[part 13 of 15: packages /TPConfig to /ComponentTypes]
AUTOSAR XML (schema 4-3-0)
package /TPConfig
  can tp config CanTPConfig_HCP3_CANFD01: communication-cluster=HCP3_CANFD01, can-tp-ecu=HCP3_IONode
    68 x can tp address:
      TA_0x1C403B1B: tp-address=473971483
      TA_0x1C423B1B: tp-address=474102555
      TA_0x1CD02268: tp-address=483402344
      TA_0x1CD22268: tp-address=483533416
      TA_0x1CD0226B: tp-address=483402347
      TA_0x1CD2226B: tp-address=483533419
      TA_0x1CD0226E: tp-address=483402350
      TA_0x1CD2226E: tp-address=483533422
      TA_0x1C446822: tp-address=474245154
      TA_0x1C466822: tp-address=474376226
      TA_0x1C446723: tp-address=474244899
      TA_0x1C466723: tp-address=474375971
      TA_0x1C446B22: tp-address=474245922
      TA_0x1C466B22: tp-address=474376994
      TA_0x1C446A23: tp-address=474245667
      TA_0x1C466A23: tp-address=474376739
      TA_0x1D001B73: tp-address=486546291
      TA_0x1D021B73: tp-address=486677363
      TA_0x1D00731B: tp-address=486568731
      TA_0x1D02731B: tp-address=486699803
      TA_0x1C446E22: tp-address=474246690
      TA_0x1C466E22: tp-address=474377762
      TA_0x1C446C24: tp-address=474246180
      TA_0x1C466C24: tp-address=474377252
      TA_0x1C446D23: tp-address=474246435
      TA_0x1C466D23: tp-address=474377507
      TA_0x1CD0246C: tp-address=483402860
      TA_0x1CD2246C: tp-address=483533932
      TA_0x1CD02367: tp-address=483402599
      TA_0x1CD22367: tp-address=483533671
      TA_0x1CD0236A: tp-address=483402602
      TA_0x1CD2236A: tp-address=483533674
      TA_0x1CD0236D: tp-address=483402605
      TA_0x1CD2236D: tp-address=483533677
      TA_0x1CC01B3B: tp-address=482351931
      TA_0x1CC21B3B: tp-address=482483003
      TA_0x1C401693: tp-address=473962131
      TA_0x1C421693: tp-address=474093203
      TA_0x1C400693: tp-address=473958035
      TA_0x1C420693: tp-address=474089107
      TA_0x1C440024: tp-address=474218532
      TA_0x1C460024: tp-address=474349604
      TA_0x1C440022: tp-address=474218530
      TA_0x1C460022: tp-address=474349602
      TA_0x1C42001B: tp-address=474087451
      TA_0x1C460023: tp-address=474349603
      TA_0x1C4200A5: tp-address=474087589
      TA_0x1C4200A6: tp-address=474087590
      TA_0x1C410000: tp-address=474021888
      TA_0x1C40001B: tp-address=473956379
      TA_0x1C440023: tp-address=474218531
      TA_0x1C4000A5: tp-address=473956517
      TA_0x1C4000A6: tp-address=473956518
      TA_0x1C42021B: tp-address=474087963
      TA_0x1C460224: tp-address=474350116
      TA_0x1C460222: tp-address=474350114
      TA_0x1C460223: tp-address=474350115
      TA_0x1C4202A5: tp-address=474088101
      TA_0x1C4202A6: tp-address=474088102
      TA_0x1C410200: tp-address=474022400
      TA_0x1C440224: tp-address=474219044
      TA_0x1C440222: tp-address=474219042
      TA_0x1C40021B: tp-address=473956891
      TA_0x1C407093: tp-address=473985171
      TA_0x1C427093: tp-address=474116243
      TA_0x1C440223: tp-address=474219043
      TA_0x1C4002A5: tp-address=473957029
      TA_0x1C4002A6: tp-address=473957030
    35 x can tp channel, all with channel-mode=HALF-DUPLEX-MODE:
      TPC_HCP3_CANFD01_XIX_TPCHType_CANFD_ARC_Master_XIX_0x1C403B1B_XIX_0x1C423B1B_XIX_Physical: channel-id=781318823
      TPC_HCP3_CANFD01_XIX_TPCHType_CANFD_HID_Slave_XIX_0x1CD02268_XIX_0x1CD22268_XIX_Physical: channel-id=1886458101
      TPC_HCP3_CANFD01_XIX_TPCHType_CANFD_HID_Slave_XIX_0x1CD0226B_XIX_0x1CD2226B_XIX_Physical: channel-id=533078475
      TPC_HCP3_CANFD01_XIX_TPCHType_CANFD_HID_Slave_XIX_0x1CD0226E_XIX_0x1CD2226E_XIX_Physical: channel-id=29550741
      TPC_HCP3_CANFD01_XIX_TPCHType_CANFD_HID_Master_XIX_0x1C446822_XIX_0x1C466822_XIX_Physical: channel-id=267511542
      TPC_HCP3_CANFD01_XIX_TPCHType_CANFD_HID_Master_XIX_0x1C446723_XIX_0x1C466723_XIX_Physical: channel-id=79765770
      TPC_HCP3_CANFD01_XIX_TPCHType_CANFD_HID_Master_XIX_0x1C446B22_XIX_0x1C466B22_XIX_Physical: channel-id=1864853942
      TPC_HCP3_CANFD01_XIX_TPCHType_CANFD_HID_Master_XIX_0x1C446A23_XIX_0x1C466A23_XIX_Physical: channel-id=1517576630
      TPC_HCP3_CANFD01_XIX_TPCHType_CANFD_HID_Slave_XIX_0x1D001B73_XIX_0x1D021B73_XIX_Physical: channel-id=1735088907
      TPC_HCP3_CANFD01_XIX_TPCHType_CANFD_HID_Master_XIX_0x1D00731B_XIX_0x1D02731B_XIX_Physical: channel-id=1786858122
      TPC_HCP3_CANFD01_XIX_TPCHType_CANFD_HID_Master_XIX_0x1C446E22_XIX_0x1C466E22_XIX_Physical: channel-id=1950910634
      TPC_HCP3_CANFD01_XIX_TPCHType_CANFD_HID_Master_XIX_0x1C446C24_XIX_0x1C466C24_XIX_Physical: channel-id=1649502038
      TPC_HCP3_CANFD01_XIX_TPCHType_CANFD_HID_Master_XIX_0x1C446D23_XIX_0x1C466D23_XIX_Physical: channel-id=1996779350
      TPC_HCP3_CANFD01_XIX_TPCHType_CANFD_HID_Slave_XIX_0x1CD0246C_XIX_0x1CD2246C_XIX_Physical: channel-id=665003883
      TPC_HCP3_CANFD01_XIX_TPCHType_CANFD_HID_Slave_XIX_0x1CD02367_XIX_0x1CD22367_XIX_Physical: channel-id=1539180789
      TPC_HCP3_CANFD01_XIX_TPCHType_CANFD_HID_Slave_XIX_0x1CD0236A_XIX_0x1CD2236A_XIX_Physical: channel-id=880355787
      TPC_HCP3_CANFD01_XIX_TPCHType_CANFD_HID_Slave_XIX_0x1CD0236D_XIX_0x1CD2236D_XIX_Physical: channel-id=317726571
      TPC_HCP3_CANFD01_XIX_TPCHType_CANFD_ARC_Slave_XIX_0x1CC01B3B_XIX_0x1CC21B3B_XIX_Physical: channel-id=2114590746
      TPC_HCP3_CANFD01_XIX_TPCHType_CANFD_Flash_DIA_XIX_0x1C401693_XIX_0x1C421693_XIX_Physical: channel-id=4065219
      TPC_HCP3_CANFD01_XIX_TPCHType_CANFD_Diag_XIX_0x1C400693_XIX_0x1C420693_XIX_Physical: channel-id=307815037
      TPC_HCP3_CANFD01_XIX_TPCHType_CANFD_ISO_Diagnose_XIX_0x1C440024_XIX_0x1C460024_XIX_Physical: channel-id=237980624
      TPC_HCP3_CANFD01_XIX_TPCHType_CANFD_ISO_Diagnose_XIX_0x1C440022_XIX_0x1C460022_XIX_Physical: channel-id=613066768
      TPC_HCP3_CANFD01_XIX_TPCHType_CANFD_ISO_Diagnose_XIX_0x1C410000_XIX_Functional: channel-id=531585000
      TPC_HCP3_CANFD01_XIX_TPCHType_CANFD_ISO_Diagnose_XIX_0x1C40001B_XIX_0x1C42001B_XIX_Physical: channel-id=706849680
      TPC_HCP3_CANFD01_XIX_TPCHType_CANFD_ISO_Diagnose_XIX_0x1C440023_XIX_0x1C460023_XIX_Physical: channel-id=425523696
      TPC_HCP3_CANFD01_XIX_TPCHType_CANFD_ISO_Diagnose_XIX_0x1C4000A5_XIX_0x1C4200A5_XIX_Physical: channel-id=1095840240
      TPC_HCP3_CANFD01_XIX_TPCHType_CANFD_ISO_Diagnose_XIX_0x1C4000A6_XIX_0x1C4200A6_XIX_Physical: channel-id=1283383312
      TPC_HCP3_CANFD01_XIX_TPCHType_CANFD_OBDC_Diagnose_XIX_0x1C410200_XIX_Functional: channel-id=89177809
      TPC_HCP3_CANFD01_XIX_TPCHType_CANFD_OBDC_Diagnose_XIX_0x1C440224_XIX_0x1C460224_XIX_Physical: channel-id=1373287515
      TPC_HCP3_CANFD01_XIX_TPCHType_CANFD_OBDC_Diagnose_XIX_0x1C440222_XIX_0x1C460222_XIX_Physical: channel-id=1748373659
      TPC_HCP3_CANFD01_XIX_TPCHType_CANFD_OBDC_Diagnose_XIX_0x1C40021B_XIX_0x1C42021B_XIX_Physical: channel-id=428457211
      TPC_HCP3_CANFD01_XIX_TPCHType_CANFD_OBDC_SSN_Diagnose_XIX_0x1C407093_XIX_0x1C427093_XIX_Physical: channel-id=26808244
      TPC_HCP3_CANFD01_XIX_TPCHType_CANFD_OBDC_Diagnose_XIX_0x1C440223_XIX_0x1C460223_XIX_Physical: channel-id=1560830587
      TPC_HCP3_CANFD01_XIX_TPCHType_CANFD_OBDC_Diagnose_XIX_0x1C4002A5_XIX_0x1C4202A5_XIX_Physical: channel-id=39466651
      TPC_HCP3_CANFD01_XIX_TPCHType_CANFD_OBDC_Diagnose_XIX_0x1C4002A6_XIX_0x1C4202A6_XIX_Physical: channel-id=148076421
    can-tp-connection addressing-format=STANDARD, can-tp-channel=TPC_HCP3_CANFD01_XIX_TPCHType_CANFD_ARC_Master_XIX_0x1C403B1B_XIX_0x1C423B1B_XIX_Physical, cancellation=true, data-pdu=ARC_HUD_Req_FD_XIX_HCP3_CANFD01, flow-control-pdu=ARC_HUD_Resp_FD_XIX_HCP3_CANFD01, max-block-size=15, padding-activation=true, receiver=TPN_HUD_XIX_HCP3_CANFD01_XIX_474102555, ta-type=PHYSICAL, timeout-br=0.1, timeout-bs=1.0, timeout-cr=1.0, timeout-cs=0.2, tp-sdu=CDD_HCP3_CANFD01_XIX_TPCHType_CANFD_ARC_Master_XIX_0x1C403B1B_XIX_0x1C423B1B_XIX_Physical, transmitter=TPN_Info_El_XIX_HCP3_CANFD01_XIX_473971483:
      ident TPCN_HCP3_CANFD01_XIX_TPCHType_CANFD_ARC_Master_XIX_0x1C403B1B_Info_El_XIX_0x1C423B1B_HUD_XIX_Physical
    can-tp-connection addressing-format=STANDARD, can-tp-channel=TPC_HCP3_CANFD01_XIX_TPCHType_CANFD_ARC_Master_XIX_0x1C403B1B_XIX_0x1C423B1B_XIX_Physical, cancellation=true, data-pdu=ARC_HUD_Resp_FD_XIX_HCP3_CANFD01, flow-control-pdu=ARC_HUD_Req_FD_XIX_HCP3_CANFD01, max-block-size=15, padding-activation=true, receiver=TPN_Info_El_XIX_HCP3_CANFD01_XIX_473971483, ta-type=PHYSICAL, timeout-br=0.1, timeout-bs=1.0, timeout-cr=1.0, timeout-cs=0.2, tp-sdu=CDD_HCP3_CANFD01_XIX_TPCHType_CANFD_ARC_Master_XIX_0x1C423B1B_XIX_0x1C403B1B_XIX_Physical, transmitter=TPN_HUD_XIX_HCP3_CANFD01_XIX_474102555:
      ident TPCN_HCP3_CANFD01_XIX_TPCHType_CANFD_ARC_Master_XIX_0x1C423B1B_HUD_XIX_0x1C403B1B_Info_El_XIX_Physical
    can-tp-connection addressing-format=STANDARD, can-tp-channel=TPC_HCP3_CANFD01_XIX_TPCHType_CANFD_ARC_Slave_XIX_0x1CC01B3B_XIX_0x1CC21B3B_XIX_Physical, cancellation=true, data-pdu=HUD_ARC_Req_FD_XIX_HCP3_CANFD01, flow-control-pdu=HUD_ARC_Resp_FD_XIX_HCP3_CANFD01, max-block-size=15, padding-activation=true, receiver=TPN_Info_El_XIX_HCP3_CANFD01_XIX_482483003, ta-type=PHYSICAL, timeout-br=0.1, timeout-bs=1.0, timeout-cr=1.0, timeout-cs=0.2, tp-sdu=CDD_HCP3_CANFD01_XIX_TPCHType_CANFD_ARC_Slave_XIX_0x1CC01B3B_XIX_0x1CC21B3B_XIX_Physical, transmitter=TPN_HUD_XIX_HCP3_CANFD01_XIX_482351931:
      ident TPCN_HCP3_CANFD01_XIX_TPCHType_CANFD_ARC_Slave_XIX_0x1CC01B3B_HUD_XIX_0x1CC21B3B_Info_El_XIX_Physical
    can-tp-connection addressing-format=STANDARD, can-tp-channel=TPC_HCP3_CANFD01_XIX_TPCHType_CANFD_ARC_Slave_XIX_0x1CC01B3B_XIX_0x1CC21B3B_XIX_Physical, cancellation=true, data-pdu=HUD_ARC_Resp_FD_XIX_HCP3_CANFD01, flow-control-pdu=HUD_ARC_Req_FD_XIX_HCP3_CANFD01, max-block-size=15, padding-activation=true, receiver=TPN_HUD_XIX_HCP3_CANFD01_XIX_482351931, ta-type=PHYSICAL, timeout-br=0.1, timeout-bs=1.0, timeout-cr=1.0, timeout-cs=0.2, tp-sdu=CDD_HCP3_CANFD01_XIX_TPCHType_CANFD_ARC_Slave_XIX_0x1CC21B3B_XIX_0x1CC01B3B_XIX_Physical, transmitter=TPN_Info_El_XIX_HCP3_CANFD01_XIX_482483003:
      ident TPCN_HCP3_CANFD01_XIX_TPCHType_CANFD_ARC_Slave_XIX_0x1CC21B3B_Info_El_XIX_0x1CC01B3B_HUD_XIX_Physical
    can-tp-connection addressing-format=STANDARD, can-tp-channel=TPC_HCP3_CANFD01_XIX_TPCHType_CANFD_Diag_XIX_0x1C400693_XIX_0x1C420693_XIX_Physical, cancellation=true, data-pdu=Diag_LSR_1_Req_FD_XIX_HCP3_CANFD01, flow-control-pdu=Diag_LSR_1_Resp_FD_XIX_HCP3_CANFD01, max-block-size=15, padding-activation=true, receiver=TPN_LSR_1_XIX_HCP3_CANFD01_XIX_474089107, ta-type=PHYSICAL, timeout-br=0.1, timeout-bs=1.0, timeout-cr=1.0, timeout-cs=0.2, tp-sdu=DCM_HCP3_CANFD01_XIX_TPCHType_CANFD_Diag_XIX_0x1C400693_XIX_0x1C420693_XIX_Physical, transmitter=TPN_Info_El_XIX_HCP3_CANFD01_XIX_473958035:
      ident TPCN_HCP3_CANFD01_XIX_TPCHType_CANFD_Diag_XIX_0x1C400693_Info_El_XIX_0x1C420693_LSR_1_XIX_Physical
    can-tp-connection addressing-format=STANDARD, can-tp-channel=TPC_HCP3_CANFD01_XIX_TPCHType_CANFD_Diag_XIX_0x1C400693_XIX_0x1C420693_XIX_Physical, cancellation=true, data-pdu=Diag_LSR_1_Resp_FD_XIX_HCP3_CANFD01, flow-control-pdu=Diag_LSR_1_Req_FD_XIX_HCP3_CANFD01, max-block-size=15, padding-activation=true, receiver=TPN_Info_El_XIX_HCP3_CANFD01_XIX_473958035, ta-type=PHYSICAL, timeout-br=0.1, timeout-bs=1.0, timeout-cr=1.0, timeout-cs=0.2, tp-sdu=DCM_HCP3_CANFD01_XIX_TPCHType_CANFD_Diag_XIX_0x1C420693_XIX_0x1C400693_XIX_Physical, transmitter=TPN_LSR_1_XIX_HCP3_CANFD01_XIX_474089107:
      ident TPCN_HCP3_CANFD01_XIX_TPCHType_CANFD_Diag_XIX_0x1C420693_LSR_1_XIX_0x1C400693_Info_El_XIX_Physical
    can-tp-connection addressing-format=STANDARD, can-tp-channel=TPC_HCP3_CANFD01_XIX_TPCHType_CANFD_Flash_DIA_XIX_0x1C401693_XIX_0x1C421693_XIX_Physical, cancellation=true, data-pdu=DIA_LSR_1_Req_FD_XIX_HCP3_CANFD01, flow-control-pdu=DIA_LSR_1_Resp_FD_XIX_HCP3_CANFD01, max-block-size=15, padding-activation=true, receiver=TPN_LSR_1_XIX_HCP3_CANFD01_XIX_474093203, ta-type=PHYSICAL, timeout-br=0.1, timeout-bs=1.0, timeout-cr=1.0, timeout-cs=0.2, tp-sdu=DCM_HCP3_CANFD01_XIX_TPCHType_CANFD_Flash_DIA_XIX_0x1C401693_XIX_0x1C421693_XIX_Physical, transmitter=TPN_Info_El_XIX_HCP3_CANFD01_XIX_473962131:
      ident TPCN_HCP3_CANFD01_XIX_TPCHType_CANFD_Flash_DIA_XIX_0x1C401693_Info_El_XIX_0x1C421693_LSR_1_XIX_Physical
    can-tp-connection addressing-format=STANDARD, can-tp-channel=TPC_HCP3_CANFD01_XIX_TPCHType_CANFD_Flash_DIA_XIX_0x1C401693_XIX_0x1C421693_XIX_Physical, cancellation=true, data-pdu=DIA_LSR_1_Resp_FD_XIX_HCP3_CANFD01, flow-control-pdu=DIA_LSR_1_Req_FD_XIX_HCP3_CANFD01, max-block-size=15, padding-activation=true, receiver=TPN_Info_El_XIX_HCP3_CANFD01_XIX_473962131, ta-type=PHYSICAL, timeout-br=0.1, timeout-bs=1.0, timeout-cr=1.0, timeout-cs=0.2, tp-sdu=DCM_HCP3_CANFD01_XIX_TPCHType_CANFD_Flash_DIA_XIX_0x1C421693_XIX_0x1C401693_XIX_Physical, transmitter=TPN_LSR_1_XIX_HCP3_CANFD01_XIX_474093203:
      ident TPCN_HCP3_CANFD01_XIX_TPCHType_CANFD_Flash_DIA_XIX_0x1C421693_LSR_1_XIX_0x1C401693_Info_El_XIX_Physical
    can-tp-connection addressing-format=STANDARD, can-tp-channel=TPC_HCP3_CANFD01_XIX_TPCHType_CANFD_HID_Master_XIX_0x1C446723_XIX_0x1C466723_XIX_Physical, cancellation=true, data-pdu=DispCtrlPID_PID_Req_FD_XIX_HCP3_CANFD01, flow-control-pdu=DispCtrlPID_PID_Resp_FD_XIX_HCP3_CANFD01, max-block-size=15, padding-activation=true, receiver=TPN_PID_XIX_HCP3_CANFD01_XIX_474375971, ta-type=PHYSICAL, timeout-br=0.1, timeout-bs=1.0, timeout-cr=1.0, timeout-cs=0.2, tp-sdu=CDD_HCP3_CANFD01_XIX_TPCHType_CANFD_HID_Master_XIX_0x1C446723_XIX_0x1C466723_XIX_Physical, transmitter=TPN_Info_El_XIX_HCP3_CANFD01_XIX_474244899:
      ident TPCN_HCP3_CANFD01_XIX_TPCHType_CANFD_HID_Master_XIX_0x1C446723_Info_El_XIX_0x1C466723_PID_XIX_Physical
    can-tp-connection addressing-format=STANDARD, can-tp-channel=TPC_HCP3_CANFD01_XIX_TPCHType_CANFD_HID_Master_XIX_0x1C446822_XIX_0x1C466822_XIX_Physical, cancellation=true, data-pdu=DispCtrlCID_CID_Req_FD_XIX_HCP3_CANFD01, flow-control-pdu=DispCtrlCID_CID_Resp_FD_XIX_HCP3_CANFD01, max-block-size=15, padding-activation=true, receiver=TPN_CID_XIX_HCP3_CANFD01_XIX_474376226, ta-type=PHYSICAL, timeout-br=0.1, timeout-bs=1.0, timeout-cr=1.0, timeout-cs=0.2, tp-sdu=CDD_HCP3_CANFD01_XIX_TPCHType_CANFD_HID_Master_XIX_0x1C446822_XIX_0x1C466822_XIX_Physical, transmitter=TPN_Info_El_XIX_HCP3_CANFD01_XIX_474245154:
      ident TPCN_HCP3_CANFD01_XIX_TPCHType_CANFD_HID_Master_XIX_0x1C446822_Info_El_XIX_0x1C466822_CID_XIX_Physical
    can-tp-connection addressing-format=STANDARD, can-tp-channel=TPC_HCP3_CANFD01_XIX_TPCHType_CANFD_HID_Master_XIX_0x1C446A23_XIX_0x1C466A23_XIX_Physical, cancellation=true, data-pdu=DispInpPID_PID_Req_FD_XIX_HCP3_CANFD01, flow-control-pdu=DispInpPID_PID_Resp_FD_XIX_HCP3_CANFD01, max-block-size=15, padding-activation=true, receiver=TPN_PID_XIX_HCP3_CANFD01_XIX_474376739, ta-type=PHYSICAL, timeout-br=0.1, timeout-bs=1.0, timeout-cr=1.0, timeout-cs=0.2, tp-sdu=CDD_HCP3_CANFD01_XIX_TPCHType_CANFD_HID_Master_XIX_0x1C446A23_XIX_0x1C466A23_XIX_Physical, transmitter=TPN_Info_El_XIX_HCP3_CANFD01_XIX_474245667:
      ident TPCN_HCP3_CANFD01_XIX_TPCHType_CANFD_HID_Master_XIX_0x1C446A23_Info_El_XIX_0x1C466A23_PID_XIX_Physical
    can-tp-connection addressing-format=STANDARD, can-tp-channel=TPC_HCP3_CANFD01_XIX_TPCHType_CANFD_HID_Master_XIX_0x1C446B22_XIX_0x1C466B22_XIX_Physical, cancellation=true, data-pdu=DispInpCID_CID_Req_FD_XIX_HCP3_CANFD01, flow-control-pdu=DispInpCID_CID_Resp_FD_XIX_HCP3_CANFD01, max-block-size=15, padding-activation=true, receiver=TPN_CID_XIX_HCP3_CANFD01_XIX_474376994, ta-type=PHYSICAL, timeout-br=0.1, timeout-bs=1.0, timeout-cr=1.0, timeout-cs=0.2, tp-sdu=CDD_HCP3_CANFD01_XIX_TPCHType_CANFD_HID_Master_XIX_0x1C446B22_XIX_0x1C466B22_XIX_Physical, transmitter=TPN_Info_El_XIX_HCP3_CANFD01_XIX_474245922:
      ident TPCN_HCP3_CANFD01_XIX_TPCHType_CANFD_HID_Master_XIX_0x1C446B22_Info_El_XIX_0x1C466B22_CID_XIX_Physical
    can-tp-connection addressing-format=STANDARD, can-tp-channel=TPC_HCP3_CANFD01_XIX_TPCHType_CANFD_HID_Master_XIX_0x1C446C24_XIX_0x1C466C24_XIX_Physical, cancellation=true, data-pdu=KeyInpLSR_LSR_Req_FD_XIX_HCP3_CANFD01, flow-control-pdu=KeyInpLSR_LSR_Resp_FD_XIX_HCP3_CANFD01, max-block-size=15, padding-activation=true, receiver=TPN_CCF_XIX_HCP3_CANFD01_XIX_474377252, ta-type=PHYSICAL, timeout-br=0.1, timeout-bs=1.0, timeout-cr=1.0, timeout-cs=0.2, tp-sdu=CDD_HCP3_CANFD01_XIX_TPCHType_CANFD_HID_Master_XIX_0x1C446C24_XIX_0x1C466C24_XIX_Physical, transmitter=TPN_Info_El_XIX_HCP3_CANFD01_XIX_474246180:
      ident TPCN_HCP3_CANFD01_XIX_TPCHType_CANFD_HID_Master_XIX_0x1C446C24_Info_El_XIX_0x1C466C24_CCF_XIX_Physical
    can-tp-connection addressing-format=STANDARD, can-tp-channel=TPC_HCP3_CANFD01_XIX_TPCHType_CANFD_HID_Master_XIX_0x1C446D23_XIX_0x1C466D23_XIX_Physical, cancellation=true, data-pdu=KeyInpPID_PID_Req_FD_XIX_HCP3_CANFD01, flow-control-pdu=KeyInpPID_PID_Resp_FD_XIX_HCP3_CANFD01, max-block-size=15, padding-activation=true, receiver=TPN_PID_XIX_HCP3_CANFD01_XIX_474377507, ta-type=PHYSICAL, timeout-br=0.1, timeout-bs=1.0, timeout-cr=1.0, timeout-cs=0.2, tp-sdu=CDD_HCP3_CANFD01_XIX_TPCHType_CANFD_HID_Master_XIX_0x1C446D23_XIX_0x1C466D23_XIX_Physical, transmitter=TPN_Info_El_XIX_HCP3_CANFD01_XIX_474246435:
      ident TPCN_HCP3_CANFD01_XIX_TPCHType_CANFD_HID_Master_XIX_0x1C446D23_Info_El_XIX_0x1C466D23_PID_XIX_Physical
    can-tp-connection addressing-format=STANDARD, can-tp-channel=TPC_HCP3_CANFD01_XIX_TPCHType_CANFD_HID_Master_XIX_0x1C446E22_XIX_0x1C466E22_XIX_Physical, cancellation=true, data-pdu=KeyInpCID_CID_Req_FD_XIX_HCP3_CANFD01, flow-control-pdu=KeyInpCID_CID_Resp_FD_XIX_HCP3_CANFD01, max-block-size=15, padding-activation=true, receiver=TPN_CID_XIX_HCP3_CANFD01_XIX_474377762, ta-type=PHYSICAL, timeout-br=0.1, timeout-bs=1.0, timeout-cr=1.0, timeout-cs=0.2, tp-sdu=CDD_HCP3_CANFD01_XIX_TPCHType_CANFD_HID_Master_XIX_0x1C446E22_XIX_0x1C466E22_XIX_Physical, transmitter=TPN_Info_El_XIX_HCP3_CANFD01_XIX_474246690:
      ident TPCN_HCP3_CANFD01_XIX_TPCHType_CANFD_HID_Master_XIX_0x1C446E22_Info_El_XIX_0x1C466E22_CID_XIX_Physical
    can-tp-connection addressing-format=STANDARD, can-tp-channel=TPC_HCP3_CANFD01_XIX_TPCHType_CANFD_HID_Master_XIX_0x1C446723_XIX_0x1C466723_XIX_Physical, cancellation=true, data-pdu=DispCtrlPID_PID_Resp_FD_XIX_HCP3_CANFD01, flow-control-pdu=DispCtrlPID_PID_Req_FD_XIX_HCP3_CANFD01, max-block-size=15, padding-activation=true, receiver=TPN_Info_El_XIX_HCP3_CANFD01_XIX_474244899, ta-type=PHYSICAL, timeout-br=0.1, timeout-bs=1.0, timeout-cr=1.0, timeout-cs=0.2, tp-sdu=CDD_HCP3_CANFD01_XIX_TPCHType_CANFD_HID_Master_XIX_0x1C466723_XIX_0x1C446723_XIX_Physical, transmitter=TPN_PID_XIX_HCP3_CANFD01_XIX_474375971:
      ident TPCN_HCP3_CANFD01_XIX_TPCHType_CANFD_HID_Master_XIX_0x1C466723_PID_XIX_0x1C446723_Info_El_XIX_Physical
    can-tp-connection addressing-format=STANDARD, can-tp-channel=TPC_HCP3_CANFD01_XIX_TPCHType_CANFD_HID_Master_XIX_0x1C446822_XIX_0x1C466822_XIX_Physical, cancellation=true, data-pdu=DispCtrlCID_CID_Resp_FD_XIX_HCP3_CANFD01, flow-control-pdu=DispCtrlCID_CID_Req_FD_XIX_HCP3_CANFD01, max-block-size=15, padding-activation=true, receiver=TPN_Info_El_XIX_HCP3_CANFD01_XIX_474245154, ta-type=PHYSICAL, timeout-br=0.1, timeout-bs=1.0, timeout-cr=1.0, timeout-cs=0.2, tp-sdu=CDD_HCP3_CANFD01_XIX_TPCHType_CANFD_HID_Master_XIX_0x1C466822_XIX_0x1C446822_XIX_Physical, transmitter=TPN_CID_XIX_HCP3_CANFD01_XIX_474376226:
      ident TPCN_HCP3_CANFD01_XIX_TPCHType_CANFD_HID_Master_XIX_0x1C466822_CID_XIX_0x1C446822_Info_El_XIX_Physical
    can-tp-connection addressing-format=STANDARD, can-tp-channel=TPC_HCP3_CANFD01_XIX_TPCHType_CANFD_HID_Master_XIX_0x1C446A23_XIX_0x1C466A23_XIX_Physical, cancellation=true, data-pdu=DispInpPID_PID_Resp_FD_XIX_HCP3_CANFD01, flow-control-pdu=DispInpPID_PID_Req_FD_XIX_HCP3_CANFD01, max-block-size=15, padding-activation=true, receiver=TPN_Info_El_XIX_HCP3_CANFD01_XIX_474245667, ta-type=PHYSICAL, timeout-br=0.1, timeout-bs=1.0, timeout-cr=1.0, timeout-cs=0.2, tp-sdu=CDD_HCP3_CANFD01_XIX_TPCHType_CANFD_HID_Master_XIX_0x1C466A23_XIX_0x1C446A23_XIX_Physical, transmitter=TPN_PID_XIX_HCP3_CANFD01_XIX_474376739:
      ident TPCN_HCP3_CANFD01_XIX_TPCHType_CANFD_HID_Master_XIX_0x1C466A23_PID_XIX_0x1C446A23_Info_El_XIX_Physical
    can-tp-connection addressing-format=STANDARD, can-tp-channel=TPC_HCP3_CANFD01_XIX_TPCHType_CANFD_HID_Master_XIX_0x1C446B22_XIX_0x1C466B22_XIX_Physical, cancellation=true, data-pdu=DispInpCID_CID_Resp_FD_XIX_HCP3_CANFD01, flow-control-pdu=DispInpCID_CID_Req_FD_XIX_HCP3_CANFD01, max-block-size=15, padding-activation=true, receiver=TPN_Info_El_XIX_HCP3_CANFD01_XIX_474245922, ta-type=PHYSICAL, timeout-br=0.1, timeout-bs=1.0, timeout-cr=1.0, timeout-cs=0.2, tp-sdu=CDD_HCP3_CANFD01_XIX_TPCHType_CANFD_HID_Master_XIX_0x1C466B22_XIX_0x1C446B22_XIX_Physical, transmitter=TPN_CID_XIX_HCP3_CANFD01_XIX_474376994:
      ident TPCN_HCP3_CANFD01_XIX_TPCHType_CANFD_HID_Master_XIX_0x1C466B22_CID_XIX_0x1C446B22_Info_El_XIX_Physical
    can-tp-connection addressing-format=STANDARD, can-tp-channel=TPC_HCP3_CANFD01_XIX_TPCHType_CANFD_HID_Master_XIX_0x1C446C24_XIX_0x1C466C24_XIX_Physical, cancellation=true, data-pdu=KeyInpLSR_LSR_Resp_FD_XIX_HCP3_CANFD01, flow-control-pdu=KeyInpLSR_LSR_Req_FD_XIX_HCP3_CANFD01, max-block-size=15, padding-activation=true, receiver=TPN_Info_El_XIX_HCP3_CANFD01_XIX_474246180, ta-type=PHYSICAL, timeout-br=0.1, timeout-bs=1.0, timeout-cr=1.0, timeout-cs=0.2, tp-sdu=CDD_HCP3_CANFD01_XIX_TPCHType_CANFD_HID_Master_XIX_0x1C466C24_XIX_0x1C446C24_XIX_Physical, transmitter=TPN_CCF_XIX_HCP3_CANFD01_XIX_474377252:
      ident TPCN_HCP3_CANFD01_XIX_TPCHType_CANFD_HID_Master_XIX_0x1C466C24_CCF_XIX_0x1C446C24_Info_El_XIX_Physical
    can-tp-connection addressing-format=STANDARD, can-tp-channel=TPC_HCP3_CANFD01_XIX_TPCHType_CANFD_HID_Master_XIX_0x1C446D23_XIX_0x1C466D23_XIX_Physical, cancellation=true, data-pdu=KeyInpPID_PID_Resp_FD_XIX_HCP3_CANFD01, flow-control-pdu=KeyInpPID_PID_Req_FD_XIX_HCP3_CANFD01, max-block-size=15, padding-activation=true, receiver=TPN_Info_El_XIX_HCP3_CANFD01_XIX_474246435, ta-type=PHYSICAL, timeout-br=0.1, timeout-bs=1.0, timeout-cr=1.0, timeout-cs=0.2, tp-sdu=CDD_HCP3_CANFD01_XIX_TPCHType_CANFD_HID_Master_XIX_0x1C466D23_XIX_0x1C446D23_XIX_Physical, transmitter=TPN_PID_XIX_HCP3_CANFD01_XIX_474377507:
      ident TPCN_HCP3_CANFD01_XIX_TPCHType_CANFD_HID_Master_XIX_0x1C466D23_PID_XIX_0x1C446D23_Info_El_XIX_Physical
    can-tp-connection addressing-format=STANDARD, can-tp-channel=TPC_HCP3_CANFD01_XIX_TPCHType_CANFD_HID_Master_XIX_0x1C446E22_XIX_0x1C466E22_XIX_Physical, cancellation=true, data-pdu=KeyInpCID_CID_Resp_FD_XIX_HCP3_CANFD01, flow-control-pdu=KeyInpCID_CID_Req_FD_XIX_HCP3_CANFD01, max-block-size=15, padding-activation=true, receiver=TPN_Info_El_XIX_HCP3_CANFD01_XIX_474246690, ta-type=PHYSICAL, timeout-br=0.1, timeout-bs=1.0, timeout-cr=1.0, timeout-cs=0.2, tp-sdu=CDD_HCP3_CANFD01_XIX_TPCHType_CANFD_HID_Master_XIX_0x1C466E22_XIX_0x1C446E22_XIX_Physical, transmitter=TPN_CID_XIX_HCP3_CANFD01_XIX_474377762:
      ident TPCN_HCP3_CANFD01_XIX_TPCHType_CANFD_HID_Master_XIX_0x1C466E22_CID_XIX_0x1C446E22_Info_El_XIX_Physical
    can-tp-connection addressing-format=STANDARD, can-tp-channel=TPC_HCP3_CANFD01_XIX_TPCHType_CANFD_HID_Master_XIX_0x1D00731B_XIX_0x1D02731B_XIX_Physical, cancellation=true, data-pdu=HID_ZR_HUD_Req_FD_XIX_HCP3_CANFD01, flow-control-pdu=HID_ZR_HUD_Resp_FD_XIX_HCP3_CANFD01, max-block-size=15, padding-activation=true, receiver=TPN_HUD_XIX_HCP3_CANFD01_XIX_486699803, ta-type=PHYSICAL, timeout-br=0.1, timeout-bs=1.0, timeout-cr=1.0, timeout-cs=0.2, tp-sdu=CDD_HCP3_CANFD01_XIX_TPCHType_CANFD_HID_Master_XIX_0x1D00731B_XIX_0x1D02731B_XIX_Physical, transmitter=TPN_Info_El_XIX_HCP3_CANFD01_XIX_486568731:
      ident TPCN_HCP3_CANFD01_XIX_TPCHType_CANFD_HID_Master_XIX_0x1D00731B_Info_El_XIX_0x1D02731B_HUD_XIX_Physical
    can-tp-connection addressing-format=STANDARD, can-tp-channel=TPC_HCP3_CANFD01_XIX_TPCHType_CANFD_HID_Master_XIX_0x1D00731B_XIX_0x1D02731B_XIX_Physical, cancellation=true, data-pdu=HID_ZR_HUD_Resp_FD_XIX_HCP3_CANFD01, flow-control-pdu=HID_ZR_HUD_Req_FD_XIX_HCP3_CANFD01, max-block-size=15, padding-activation=true, receiver=TPN_Info_El_XIX_HCP3_CANFD01_XIX_486568731, ta-type=PHYSICAL, timeout-br=0.1, timeout-bs=1.0, timeout-cr=1.0, timeout-cs=0.2, tp-sdu=CDD_HCP3_CANFD01_XIX_TPCHType_CANFD_HID_Master_XIX_0x1D02731B_XIX_0x1D00731B_XIX_Physical, transmitter=TPN_HUD_XIX_HCP3_CANFD01_XIX_486699803:
      ident TPCN_HCP3_CANFD01_XIX_TPCHType_CANFD_HID_Master_XIX_0x1D02731B_HUD_XIX_0x1D00731B_Info_El_XIX_Physical
    can-tp-connection addressing-format=STANDARD, can-tp-channel=TPC_HCP3_CANFD01_XIX_TPCHType_CANFD_HID_Slave_XIX_0x1CD02268_XIX_0x1CD22268_XIX_Physical, cancellation=true, data-pdu=CID_DispCtrlCID_Req_FD_XIX_HCP3_CANFD01, flow-control-pdu=CID_DispCtrlCID_Resp_FD_XIX_HCP3_CANFD01, max-block-size=15, padding-activation=true, receiver=TPN_Info_El_XIX_HCP3_CANFD01_XIX_483533416, ta-type=PHYSICAL, timeout-br=0.1, timeout-bs=1.0, timeout-cr=1.0, timeout-cs=0.2, tp-sdu=CDD_HCP3_CANFD01_XIX_TPCHType_CANFD_HID_Slave_XIX_0x1CD02268_XIX_0x1CD22268_XIX_Physical, transmitter=TPN_CID_XIX_HCP3_CANFD01_XIX_483402344:
      ident TPCN_HCP3_CANFD01_XIX_TPCHType_CANFD_HID_Slave_XIX_0x1CD02268_CID_XIX_0x1CD22268_Info_El_XIX_Physical
    can-tp-connection addressing-format=STANDARD, can-tp-channel=TPC_HCP3_CANFD01_XIX_TPCHType_CANFD_HID_Slave_XIX_0x1CD0226B_XIX_0x1CD2226B_XIX_Physical, cancellation=true, data-pdu=CID_DispInpCID_Req_FD_XIX_HCP3_CANFD01, flow-control-pdu=CID_DispInpCID_Resp_FD_XIX_HCP3_CANFD01, max-block-size=15, padding-activation=true, receiver=TPN_Info_El_XIX_HCP3_CANFD01_XIX_483533419, ta-type=PHYSICAL, timeout-br=0.1, timeout-bs=1.0, timeout-cr=1.0, timeout-cs=0.2, tp-sdu=CDD_HCP3_CANFD01_XIX_TPCHType_CANFD_HID_Slave_XIX_0x1CD0226B_XIX_0x1CD2226B_XIX_Physical, transmitter=TPN_CID_XIX_HCP3_CANFD01_XIX_483402347:
      ident TPCN_HCP3_CANFD01_XIX_TPCHType_CANFD_HID_Slave_XIX_0x1CD0226B_CID_XIX_0x1CD2226B_Info_El_XIX_Physical
    can-tp-connection addressing-format=STANDARD, can-tp-channel=TPC_HCP3_CANFD01_XIX_TPCHType_CANFD_HID_Slave_XIX_0x1CD0226E_XIX_0x1CD2226E_XIX_Physical, cancellation=true, data-pdu=CID_KeyInpCID_Req_FD_XIX_HCP3_CANFD01, flow-control-pdu=CID_KeyInpCID_Resp_FD_XIX_HCP3_CANFD01, max-block-size=15, padding-activation=true, receiver=TPN_Info_El_XIX_HCP3_CANFD01_XIX_483533422, ta-type=PHYSICAL, timeout-br=0.1, timeout-bs=1.0, timeout-cr=1.0, timeout-cs=0.2, tp-sdu=CDD_HCP3_CANFD01_XIX_TPCHType_CANFD_HID_Slave_XIX_0x1CD0226E_XIX_0x1CD2226E_XIX_Physical, transmitter=TPN_CID_XIX_HCP3_CANFD01_XIX_483402350:
      ident TPCN_HCP3_CANFD01_XIX_TPCHType_CANFD_HID_Slave_XIX_0x1CD0226E_CID_XIX_0x1CD2226E_Info_El_XIX_Physical
    can-tp-connection addressing-format=STANDARD, can-tp-channel=TPC_HCP3_CANFD01_XIX_TPCHType_CANFD_HID_Slave_XIX_0x1CD02367_XIX_0x1CD22367_XIX_Physical, cancellation=true, data-pdu=PID_DispCtrlPID_Req_FD_XIX_HCP3_CANFD01, flow-control-pdu=PID_DispCtrlPID_Resp_FD_XIX_HCP3_CANFD01, max-block-size=15, padding-activation=true, receiver=TPN_Info_El_XIX_HCP3_CANFD01_XIX_483533671, ta-type=PHYSICAL, timeout-br=0.1, timeout-bs=1.0, timeout-cr=1.0, timeout-cs=0.2, tp-sdu=CDD_HCP3_CANFD01_XIX_TPCHType_CANFD_HID_Slave_XIX_0x1CD02367_XIX_0x1CD22367_XIX_Physical, transmitter=TPN_PID_XIX_HCP3_CANFD01_XIX_483402599:
      ident TPCN_HCP3_CANFD01_XIX_TPCHType_CANFD_HID_Slave_XIX_0x1CD02367_PID_XIX_0x1CD22367_Info_El_XIX_Physical
    can-tp-connection addressing-format=STANDARD, can-tp-channel=TPC_HCP3_CANFD01_XIX_TPCHType_CANFD_HID_Slave_XIX_0x1CD0236A_XIX_0x1CD2236A_XIX_Physical, cancellation=true, data-pdu=PID_DispInpPID_Req_FD_XIX_HCP3_CANFD01, flow-control-pdu=PID_DispInpPID_Resp_FD_XIX_HCP3_CANFD01, max-block-size=15, padding-activation=true, receiver=TPN_Info_El_XIX_HCP3_CANFD01_XIX_483533674, ta-type=PHYSICAL, timeout-br=0.1, timeout-bs=1.0, timeout-cr=1.0, timeout-cs=0.2, tp-sdu=CDD_HCP3_CANFD01_XIX_TPCHType_CANFD_HID_Slave_XIX_0x1CD0236A_XIX_0x1CD2236A_XIX_Physical, transmitter=TPN_PID_XIX_HCP3_CANFD01_XIX_483402602:
      ident TPCN_HCP3_CANFD01_XIX_TPCHType_CANFD_HID_Slave_XIX_0x1CD0236A_PID_XIX_0x1CD2236A_Info_El_XIX_Physical
    can-tp-connection addressing-format=STANDARD, can-tp-channel=TPC_HCP3_CANFD01_XIX_TPCHType_CANFD_HID_Slave_XIX_0x1CD0236D_XIX_0x1CD2236D_XIX_Physical, cancellation=true, data-pdu=PID_KeyInpPID_Req_FD_XIX_HCP3_CANFD01, flow-control-pdu=PID_KeyInpPID_Resp_FD_XIX_HCP3_CANFD01, max-block-size=15, padding-activation=true, receiver=TPN_Info_El_XIX_HCP3_CANFD01_XIX_483533677, ta-type=PHYSICAL, timeout-br=0.1, timeout-bs=1.0, timeout-cr=1.0, timeout-cs=0.2, tp-sdu=CDD_HCP3_CANFD01_XIX_TPCHType_CANFD_HID_Slave_XIX_0x1CD0236D_XIX_0x1CD2236D_XIX_Physical, transmitter=TPN_PID_XIX_HCP3_CANFD01_XIX_483402605:
      ident TPCN_HCP3_CANFD01_XIX_TPCHType_CANFD_HID_Slave_XIX_0x1CD0236D_PID_XIX_0x1CD2236D_Info_El_XIX_Physical
    can-tp-connection addressing-format=STANDARD, can-tp-channel=TPC_HCP3_CANFD01_XIX_TPCHType_CANFD_HID_Slave_XIX_0x1CD0246C_XIX_0x1CD2246C_XIX_Physical, cancellation=true, data-pdu=LSR_KeyInpLSR_Req_FD_XIX_HCP3_CANFD01, flow-control-pdu=LSR_KeyInpLSR_Resp_FD_XIX_HCP3_CANFD01, max-block-size=15, padding-activation=true, receiver=TPN_Info_El_XIX_HCP3_CANFD01_XIX_483533932, ta-type=PHYSICAL, timeout-br=0.1, timeout-bs=1.0, timeout-cr=1.0, timeout-cs=0.2, tp-sdu=CDD_HCP3_CANFD01_XIX_TPCHType_CANFD_HID_Slave_XIX_0x1CD0246C_XIX_0x1CD2246C_XIX_Physical, transmitter=TPN_CCF_XIX_HCP3_CANFD01_XIX_483402860:
      ident TPCN_HCP3_CANFD01_XIX_TPCHType_CANFD_HID_Slave_XIX_0x1CD0246C_CCF_XIX_0x1CD2246C_Info_El_XIX_Physical
    can-tp-connection addressing-format=STANDARD, can-tp-channel=TPC_HCP3_CANFD01_XIX_TPCHType_CANFD_HID_Slave_XIX_0x1CD02268_XIX_0x1CD22268_XIX_Physical, cancellation=true, data-pdu=CID_DispCtrlCID_Resp_FD_XIX_HCP3_CANFD01, flow-control-pdu=CID_DispCtrlCID_Req_FD_XIX_HCP3_CANFD01, max-block-size=15, padding-activation=true, receiver=TPN_CID_XIX_HCP3_CANFD01_XIX_483402344, ta-type=PHYSICAL, timeout-br=0.1, timeout-bs=1.0, timeout-cr=1.0, timeout-cs=0.2, tp-sdu=CDD_HCP3_CANFD01_XIX_TPCHType_CANFD_HID_Slave_XIX_0x1CD22268_XIX_0x1CD02268_XIX_Physical, transmitter=TPN_Info_El_XIX_HCP3_CANFD01_XIX_483533416:
      ident TPCN_HCP3_CANFD01_XIX_TPCHType_CANFD_HID_Slave_XIX_0x1CD22268_Info_El_XIX_0x1CD02268_CID_XIX_Physical
    can-tp-connection addressing-format=STANDARD, can-tp-channel=TPC_HCP3_CANFD01_XIX_TPCHType_CANFD_HID_Slave_XIX_0x1CD0226B_XIX_0x1CD2226B_XIX_Physical, cancellation=true, data-pdu=CID_DispInpCID_Resp_FD_XIX_HCP3_CANFD01, flow-control-pdu=CID_DispInpCID_Req_FD_XIX_HCP3_CANFD01, max-block-size=15, padding-activation=true, receiver=TPN_CID_XIX_HCP3_CANFD01_XIX_483402347, ta-type=PHYSICAL, timeout-br=0.1, timeout-bs=1.0, timeout-cr=1.0, timeout-cs=0.2, tp-sdu=CDD_HCP3_CANFD01_XIX_TPCHType_CANFD_HID_Slave_XIX_0x1CD2226B_XIX_0x1CD0226B_XIX_Physical, transmitter=TPN_Info_El_XIX_HCP3_CANFD01_XIX_483533419:
      ident TPCN_HCP3_CANFD01_XIX_TPCHType_CANFD_HID_Slave_XIX_0x1CD2226B_Info_El_XIX_0x1CD0226B_CID_XIX_Physical
    can-tp-connection addressing-format=STANDARD, can-tp-channel=TPC_HCP3_CANFD01_XIX_TPCHType_CANFD_HID_Slave_XIX_0x1CD0226E_XIX_0x1CD2226E_XIX_Physical, cancellation=true, data-pdu=CID_KeyInpCID_Resp_FD_XIX_HCP3_CANFD01, flow-control-pdu=CID_KeyInpCID_Req_FD_XIX_HCP3_CANFD01, max-block-size=15, padding-activation=true, receiver=TPN_CID_XIX_HCP3_CANFD01_XIX_483402350, ta-type=PHYSICAL, timeout-br=0.1, timeout-bs=1.0, timeout-cr=1.0, timeout-cs=0.2, tp-sdu=CDD_HCP3_CANFD01_XIX_TPCHType_CANFD_HID_Slave_XIX_0x1CD2226E_XIX_0x1CD0226E_XIX_Physical, transmitter=TPN_Info_El_XIX_HCP3_CANFD01_XIX_483533422:
      ident TPCN_HCP3_CANFD01_XIX_TPCHType_CANFD_HID_Slave_XIX_0x1CD2226E_Info_El_XIX_0x1CD0226E_CID_XIX_Physical
    can-tp-connection addressing-format=STANDARD, can-tp-channel=TPC_HCP3_CANFD01_XIX_TPCHType_CANFD_HID_Slave_XIX_0x1CD02367_XIX_0x1CD22367_XIX_Physical, cancellation=true, data-pdu=PID_DispCtrlPID_Resp_FD_XIX_HCP3_CANFD01, flow-control-pdu=PID_DispCtrlPID_Req_FD_XIX_HCP3_CANFD01, max-block-size=15, padding-activation=true, receiver=TPN_PID_XIX_HCP3_CANFD01_XIX_483402599, ta-type=PHYSICAL, timeout-br=0.1, timeout-bs=1.0, timeout-cr=1.0, timeout-cs=0.2, tp-sdu=CDD_HCP3_CANFD01_XIX_TPCHType_CANFD_HID_Slave_XIX_0x1CD22367_XIX_0x1CD02367_XIX_Physical, transmitter=TPN_Info_El_XIX_HCP3_CANFD01_XIX_483533671:
      ident TPCN_HCP3_CANFD01_XIX_TPCHType_CANFD_HID_Slave_XIX_0x1CD22367_Info_El_XIX_0x1CD02367_PID_XIX_Physical
    can-tp-connection addressing-format=STANDARD, can-tp-channel=TPC_HCP3_CANFD01_XIX_TPCHType_CANFD_HID_Slave_XIX_0x1CD0236A_XIX_0x1CD2236A_XIX_Physical, cancellation=true, data-pdu=PID_DispInpPID_Resp_FD_XIX_HCP3_CANFD01, flow-control-pdu=PID_DispInpPID_Req_FD_XIX_HCP3_CANFD01, max-block-size=15, padding-activation=true, receiver=TPN_PID_XIX_HCP3_CANFD01_XIX_483402602, ta-type=PHYSICAL, timeout-br=0.1, timeout-bs=1.0, timeout-cr=1.0, timeout-cs=0.2, tp-sdu=CDD_HCP3_CANFD01_XIX_TPCHType_CANFD_HID_Slave_XIX_0x1CD2236A_XIX_0x1CD0236A_XIX_Physical, transmitter=TPN_Info_El_XIX_HCP3_CANFD01_XIX_483533674:
      ident TPCN_HCP3_CANFD01_XIX_TPCHType_CANFD_HID_Slave_XIX_0x1CD2236A_Info_El_XIX_0x1CD0236A_PID_XIX_Physical
    can-tp-connection addressing-format=STANDARD, can-tp-channel=TPC_HCP3_CANFD01_XIX_TPCHType_CANFD_HID_Slave_XIX_0x1CD0236D_XIX_0x1CD2236D_XIX_Physical, cancellation=true, data-pdu=PID_KeyInpPID_Resp_FD_XIX_HCP3_CANFD01, flow-control-pdu=PID_KeyInpPID_Req_FD_XIX_HCP3_CANFD01, max-block-size=15, padding-activation=true, receiver=TPN_PID_XIX_HCP3_CANFD01_XIX_483402605, ta-type=PHYSICAL, timeout-br=0.1, timeout-bs=1.0, timeout-cr=1.0, timeout-cs=0.2, tp-sdu=CDD_HCP3_CANFD01_XIX_TPCHType_CANFD_HID_Slave_XIX_0x1CD2236D_XIX_0x1CD0236D_XIX_Physical, transmitter=TPN_Info_El_XIX_HCP3_CANFD01_XIX_483533677:
      ident TPCN_HCP3_CANFD01_XIX_TPCHType_CANFD_HID_Slave_XIX_0x1CD2236D_Info_El_XIX_0x1CD0236D_PID_XIX_Physical
    can-tp-connection addressing-format=STANDARD, can-tp-channel=TPC_HCP3_CANFD01_XIX_TPCHType_CANFD_HID_Slave_XIX_0x1CD0246C_XIX_0x1CD2246C_XIX_Physical, cancellation=true, data-pdu=LSR_KeyInpLSR_Resp_FD_XIX_HCP3_CANFD01, flow-control-pdu=LSR_KeyInpLSR_Req_FD_XIX_HCP3_CANFD01, max-block-size=15, padding-activation=true, receiver=TPN_CCF_XIX_HCP3_CANFD01_XIX_483402860, ta-type=PHYSICAL, timeout-br=0.1, timeout-bs=1.0, timeout-cr=1.0, timeout-cs=0.2, tp-sdu=CDD_HCP3_CANFD01_XIX_TPCHType_CANFD_HID_Slave_XIX_0x1CD2246C_XIX_0x1CD0246C_XIX_Physical, transmitter=TPN_Info_El_XIX_HCP3_CANFD01_XIX_483533932:
      ident TPCN_HCP3_CANFD01_XIX_TPCHType_CANFD_HID_Slave_XIX_0x1CD2246C_Info_El_XIX_0x1CD0246C_CCF_XIX_Physical
    can-tp-connection addressing-format=STANDARD, can-tp-channel=TPC_HCP3_CANFD01_XIX_TPCHType_CANFD_HID_Slave_XIX_0x1D001B73_XIX_0x1D021B73_XIX_Physical, cancellation=true, data-pdu=HID_HUD_ZR_Req_FD_XIX_HCP3_CANFD01, flow-control-pdu=HID_HUD_ZR_Resp_FD_XIX_HCP3_CANFD01, max-block-size=15, padding-activation=true, receiver=TPN_Info_El_XIX_HCP3_CANFD01_XIX_486677363, ta-type=PHYSICAL, timeout-br=0.1, timeout-bs=1.0, timeout-cr=1.0, timeout-cs=0.2, tp-sdu=CDD_HCP3_CANFD01_XIX_TPCHType_CANFD_HID_Slave_XIX_0x1D001B73_XIX_0x1D021B73_XIX_Physical, transmitter=TPN_HUD_XIX_HCP3_CANFD01_XIX_486546291:
      ident TPCN_HCP3_CANFD01_XIX_TPCHType_CANFD_HID_Slave_XIX_0x1D001B73_HUD_XIX_0x1D021B73_Info_El_XIX_Physical
    can-tp-connection addressing-format=STANDARD, can-tp-channel=TPC_HCP3_CANFD01_XIX_TPCHType_CANFD_HID_Slave_XIX_0x1D001B73_XIX_0x1D021B73_XIX_Physical, cancellation=true, data-pdu=HID_HUD_ZR_Resp_FD_XIX_HCP3_CANFD01, flow-control-pdu=HID_HUD_ZR_Req_FD_XIX_HCP3_CANFD01, max-block-size=15, padding-activation=true, receiver=TPN_HUD_XIX_HCP3_CANFD01_XIX_486546291, ta-type=PHYSICAL, timeout-br=0.1, timeout-bs=1.0, timeout-cr=1.0, timeout-cs=0.2, tp-sdu=CDD_HCP3_CANFD01_XIX_TPCHType_CANFD_HID_Slave_XIX_0x1D021B73_XIX_0x1D001B73_XIX_Physical, transmitter=TPN_Info_El_XIX_HCP3_CANFD01_XIX_486677363:
      ident TPCN_HCP3_CANFD01_XIX_TPCHType_CANFD_HID_Slave_XIX_0x1D021B73_Info_El_XIX_0x1D001B73_HUD_XIX_Physical
    can-tp-connection addressing-format=STANDARD, can-tp-channel=TPC_HCP3_CANFD01_XIX_TPCHType_CANFD_ISO_Diagnose_XIX_0x1C40001B_XIX_0x1C42001B_XIX_Physical, cancellation=true, data-pdu=ISOx_HUD_Req_FD_XIX_HCP3_CANFD01, flow-control-pdu=ISOx_HUD_Resp_FD_XIX_HCP3_CANFD01, max-block-size=15, padding-activation=true, receiver=TPN_HUD_XIX_HCP3_CANFD01_XIX_474087451, ta-type=PHYSICAL, timeout-br=0.1, timeout-bs=1.0, timeout-cr=1.0, timeout-cs=0.2, tp-sdu=DCM_HCP3_CANFD01_XIX_TPCHType_CANFD_ISO_Diagnose_XIX_0x1C40001B_XIX_0x1C42001B_XIX_Physical, transmitter=TPN_Info_El_XIX_HCP3_CANFD01_XIX_473956379:
      ident TPCN_HCP3_CANFD01_XIX_TPCHType_CANFD_ISO_Diagnose_XIX_0x1C40001B_Info_El_XIX_0x1C42001B_HUD_XIX_Physical
    can-tp-connection addressing-format=STANDARD, can-tp-channel=TPC_HCP3_CANFD01_XIX_TPCHType_CANFD_ISO_Diagnose_XIX_0x1C4000A5_XIX_0x1C4200A5_XIX_Physical, cancellation=true, data-pdu=ISOx_WLC1_Req_FD_XIX_HCP3_CANFD01, flow-control-pdu=ISOx_WLC1_Resp_FD_XIX_HCP3_CANFD01, max-block-size=15, padding-activation=true, receiver=TPN_WLC1_XIX_HCP3_CANFD01_XIX_474087589, ta-type=PHYSICAL, timeout-br=0.1, timeout-bs=1.0, timeout-cr=1.0, timeout-cs=0.2, tp-sdu=DCM_HCP3_CANFD01_XIX_TPCHType_CANFD_ISO_Diagnose_XIX_0x1C4000A5_XIX_0x1C4200A5_XIX_Physical, transmitter=TPN_Info_El_XIX_HCP3_CANFD01_XIX_473956517:
      ident TPCN_HCP3_CANFD01_XIX_TPCHType_CANFD_ISO_Diagnose_XIX_0x1C4000A5_Info_El_XIX_0x1C4200A5_WLC1_XIX_Physical
    can-tp-connection addressing-format=STANDARD, can-tp-channel=TPC_HCP3_CANFD01_XIX_TPCHType_CANFD_ISO_Diagnose_XIX_0x1C4000A6_XIX_0x1C4200A6_XIX_Physical, cancellation=true, data-pdu=ISOx_WLC2_Req_FD_XIX_HCP3_CANFD01, flow-control-pdu=ISOx_WLC2_Resp_FD_XIX_HCP3_CANFD01, max-block-size=15, padding-activation=true, receiver=TPN_WLC2_XIX_HCP3_CANFD01_XIX_474087590, ta-type=PHYSICAL, timeout-br=0.1, timeout-bs=1.0, timeout-cr=1.0, timeout-cs=0.2, tp-sdu=DCM_HCP3_CANFD01_XIX_TPCHType_CANFD_ISO_Diagnose_XIX_0x1C4000A6_XIX_0x1C4200A6_XIX_Physical, transmitter=TPN_Info_El_XIX_HCP3_CANFD01_XIX_473956518:
      ident TPCN_HCP3_CANFD01_XIX_TPCHType_CANFD_ISO_Diagnose_XIX_0x1C4000A6_Info_El_XIX_0x1C4200A6_WLC2_XIX_Physical
    can-tp-connection addressing-format=STANDARD, can-tp-channel=TPC_HCP3_CANFD01_XIX_TPCHType_CANFD_ISO_Diagnose_XIX_0x1C410000_XIX_Functional, cancellation=true, data-pdu=ISOx_Funkt_Req_All_FD_XIX_HCP3_CANFD01, max-block-size=15, multicast=TA_0x1C410000, padding-activation=true, receiver=[TPN_HUD_XIX_HCP3_CANFD01_XIX_474087451, TPN_HUD_XIX_HCP3_CANFD01_XIX_474087589, TPN_HUD_XIX_HCP3_CANFD01_XIX_474087590, TPN_HUD_XIX_HCP3_CANFD01_XIX_474349602, TPN_HUD_XIX_HCP3_CANFD01_XIX_474349603, TPN_HUD_XIX_HCP3_CANFD01_XIX_474349604, TPN_CCF_XIX_HCP3_CANFD01_XIX_474087451, TPN_CCF_XIX_HCP3_CANFD01_XIX_474087589, TPN_CCF_XIX_HCP3_CANFD01_XIX_474087590, TPN_CCF_XIX_HCP3_CANFD01_XIX_474349602, TPN_CCF_XIX_HCP3_CANFD01_XIX_474349603, TPN_CCF_XIX_HCP3_CANFD01_XIX_474349604, TPN_CID_XIX_HCP3_CANFD01_XIX_474087451, TPN_CID_XIX_HCP3_CANFD01_XIX_474087589, TPN_CID_XIX_HCP3_CANFD01_XIX_474087590, TPN_CID_XIX_HCP3_CANFD01_XIX_474349602, TPN_CID_XIX_HCP3_CANFD01_XIX_474349603, TPN_CID_XIX_HCP3_CANFD01_XIX_474349604, TPN_PID_XIX_HCP3_CANFD01_XIX_474087451, TPN_PID_XIX_HCP3_CANFD01_XIX_474087589, TPN_PID_XIX_HCP3_CANFD01_XIX_474087590, TPN_PID_XIX_HCP3_CANFD01_XIX_474349602, TPN_PID_XIX_HCP3_CANFD01_XIX_474349603, TPN_PID_XIX_HCP3_CANFD01_XIX_474349604, TPN_WLC1_XIX_HCP3_CANFD01_XIX_474087451, TPN_WLC1_XIX_HCP3_CANFD01_XIX_474087589, TPN_WLC1_XIX_HCP3_CANFD01_XIX_474087590, TPN_WLC1_XIX_HCP3_CANFD01_XIX_474349602, TPN_WLC1_XIX_HCP3_CANFD01_XIX_474349603, TPN_WLC1_XIX_HCP3_CANFD01_XIX_474349604, TPN_WLC2_XIX_HCP3_CANFD01_XIX_474087451, TPN_WLC2_XIX_HCP3_CANFD01_XIX_474087589, TPN_WLC2_XIX_HCP3_CANFD01_XIX_474087590, TPN_WLC2_XIX_HCP3_CANFD01_XIX_474349602, TPN_WLC2_XIX_HCP3_CANFD01_XIX_474349603, TPN_WLC2_XIX_HCP3_CANFD01_XIX_474349604], ta-type=FUNCTIONAL, timeout-br=0.1, timeout-bs=1.0, timeout-cr=1.0, timeout-cs=0.2, tp-sdu=DCM_HCP3_CANFD01_XIX_TPCHType_CANFD_ISO_Diagnose_XIX_0x1C410000_XIX_Functional, transmitter=TPN_Info_El_XIX_HCP3_CANFD01_XIX_474021888:
      ident TPCN_HCP3_CANFD01_XIX_TPCHType_CANFD_ISO_Diagnose_XIX_0x1C410000_Info_El_XIX_Functional
    can-tp-connection addressing-format=STANDARD, can-tp-channel=TPC_HCP3_CANFD01_XIX_TPCHType_CANFD_ISO_Diagnose_XIX_0x1C40001B_XIX_0x1C42001B_XIX_Physical, cancellation=true, data-pdu=ISOx_HUD_Resp_FD_XIX_HCP3_CANFD01, flow-control-pdu=ISOx_HUD_Req_FD_XIX_HCP3_CANFD01, max-block-size=15, padding-activation=true, receiver=TPN_Info_El_XIX_HCP3_CANFD01_XIX_473956379, ta-type=PHYSICAL, timeout-br=0.1, timeout-bs=1.0, timeout-cr=1.0, timeout-cs=0.2, tp-sdu=DCM_HCP3_CANFD01_XIX_TPCHType_CANFD_ISO_Diagnose_XIX_0x1C42001B_XIX_0x1C40001B_XIX_Physical, transmitter=TPN_HUD_XIX_HCP3_CANFD01_XIX_474087451:
      ident TPCN_HCP3_CANFD01_XIX_TPCHType_CANFD_ISO_Diagnose_XIX_0x1C42001B_HUD_XIX_0x1C40001B_Info_El_XIX_Physical
    can-tp-connection addressing-format=STANDARD, can-tp-channel=TPC_HCP3_CANFD01_XIX_TPCHType_CANFD_ISO_Diagnose_XIX_0x1C4000A5_XIX_0x1C4200A5_XIX_Physical, cancellation=true, data-pdu=ISOx_WLC1_Resp_FD_XIX_HCP3_CANFD01, flow-control-pdu=ISOx_WLC1_Req_FD_XIX_HCP3_CANFD01, max-block-size=15, padding-activation=true, receiver=TPN_Info_El_XIX_HCP3_CANFD01_XIX_473956517, ta-type=PHYSICAL, timeout-br=0.1, timeout-bs=1.0, timeout-cr=1.0, timeout-cs=0.2, tp-sdu=DCM_HCP3_CANFD01_XIX_TPCHType_CANFD_ISO_Diagnose_XIX_0x1C4200A5_XIX_0x1C4000A5_XIX_Physical, transmitter=TPN_WLC1_XIX_HCP3_CANFD01_XIX_474087589:
      ident TPCN_HCP3_CANFD01_XIX_TPCHType_CANFD_ISO_Diagnose_XIX_0x1C4200A5_WLC1_XIX_0x1C4000A5_Info_El_XIX_Physical
    can-tp-connection addressing-format=STANDARD, can-tp-channel=TPC_HCP3_CANFD01_XIX_TPCHType_CANFD_ISO_Diagnose_XIX_0x1C4000A6_XIX_0x1C4200A6_XIX_Physical, cancellation=true, data-pdu=ISOx_WLC2_Resp_FD_XIX_HCP3_CANFD01, flow-control-pdu=ISOx_WLC2_Req_FD_XIX_HCP3_CANFD01, max-block-size=15, padding-activation=true, receiver=TPN_Info_El_XIX_HCP3_CANFD01_XIX_473956518, ta-type=PHYSICAL, timeout-br=0.1, timeout-bs=1.0, timeout-cr=1.0, timeout-cs=0.2, tp-sdu=DCM_HCP3_CANFD01_XIX_TPCHType_CANFD_ISO_Diagnose_XIX_0x1C4200A6_XIX_0x1C4000A6_XIX_Physical, transmitter=TPN_WLC2_XIX_HCP3_CANFD01_XIX_474087590:
      ident TPCN_HCP3_CANFD01_XIX_TPCHType_CANFD_ISO_Diagnose_XIX_0x1C4200A6_WLC2_XIX_0x1C4000A6_Info_El_XIX_Physical
    can-tp-connection addressing-format=STANDARD, can-tp-channel=TPC_HCP3_CANFD01_XIX_TPCHType_CANFD_ISO_Diagnose_XIX_0x1C440022_XIX_0x1C460022_XIX_Physical, cancellation=true, data-pdu=ISOx_CID_Req_FD_XIX_HCP3_CANFD01, flow-control-pdu=ISOx_CID_Resp_FD_XIX_HCP3_CANFD01, max-block-size=15, padding-activation=true, receiver=TPN_CID_XIX_HCP3_CANFD01_XIX_474349602, ta-type=PHYSICAL, timeout-br=0.1, timeout-bs=1.0, timeout-cr=1.0, timeout-cs=0.2, tp-sdu=DCM_HCP3_CANFD01_XIX_TPCHType_CANFD_ISO_Diagnose_XIX_0x1C440022_XIX_0x1C460022_XIX_Physical, transmitter=TPN_Info_El_XIX_HCP3_CANFD01_XIX_474218530:
      ident TPCN_HCP3_CANFD01_XIX_TPCHType_CANFD_ISO_Diagnose_XIX_0x1C440022_Info_El_XIX_0x1C460022_CID_XIX_Physical
    can-tp-connection addressing-format=STANDARD, can-tp-channel=TPC_HCP3_CANFD01_XIX_TPCHType_CANFD_ISO_Diagnose_XIX_0x1C440023_XIX_0x1C460023_XIX_Physical, cancellation=true, data-pdu=ISOx_PID_Req_FD_XIX_HCP3_CANFD01, flow-control-pdu=ISOx_PID_Resp_FD_XIX_HCP3_CANFD01, max-block-size=15, padding-activation=true, receiver=TPN_PID_XIX_HCP3_CANFD01_XIX_474349603, ta-type=PHYSICAL, timeout-br=0.1, timeout-bs=1.0, timeout-cr=1.0, timeout-cs=0.2, tp-sdu=DCM_HCP3_CANFD01_XIX_TPCHType_CANFD_ISO_Diagnose_XIX_0x1C440023_XIX_0x1C460023_XIX_Physical, transmitter=TPN_Info_El_XIX_HCP3_CANFD01_XIX_474218531:
      ident TPCN_HCP3_CANFD01_XIX_TPCHType_CANFD_ISO_Diagnose_XIX_0x1C440023_Info_El_XIX_0x1C460023_PID_XIX_Physical
    can-tp-connection addressing-format=STANDARD, can-tp-channel=TPC_HCP3_CANFD01_XIX_TPCHType_CANFD_ISO_Diagnose_XIX_0x1C440024_XIX_0x1C460024_XIX_Physical, cancellation=true, data-pdu=ISOx_CCF_Req_FD_XIX_HCP3_CANFD01, flow-control-pdu=ISOx_CCF_Resp_FD_XIX_HCP3_CANFD01, max-block-size=15, padding-activation=true, receiver=TPN_CCF_XIX_HCP3_CANFD01_XIX_474349604, ta-type=PHYSICAL, timeout-br=0.1, timeout-bs=1.0, timeout-cr=1.0, timeout-cs=0.2, tp-sdu=DCM_HCP3_CANFD01_XIX_TPCHType_CANFD_ISO_Diagnose_XIX_0x1C440024_XIX_0x1C460024_XIX_Physical, transmitter=TPN_Info_El_XIX_HCP3_CANFD01_XIX_474218532:
      ident TPCN_HCP3_CANFD01_XIX_TPCHType_CANFD_ISO_Diagnose_XIX_0x1C440024_Info_El_XIX_0x1C460024_CCF_XIX_Physical
    can-tp-connection addressing-format=STANDARD, can-tp-channel=TPC_HCP3_CANFD01_XIX_TPCHType_CANFD_ISO_Diagnose_XIX_0x1C440022_XIX_0x1C460022_XIX_Physical, cancellation=true, data-pdu=ISOx_CID_Resp_FD_XIX_HCP3_CANFD01, flow-control-pdu=ISOx_CID_Req_FD_XIX_HCP3_CANFD01, max-block-size=15, padding-activation=true, receiver=TPN_Info_El_XIX_HCP3_CANFD01_XIX_474218530, ta-type=PHYSICAL, timeout-br=0.1, timeout-bs=1.0, timeout-cr=1.0, timeout-cs=0.2, tp-sdu=DCM_HCP3_CANFD01_XIX_TPCHType_CANFD_ISO_Diagnose_XIX_0x1C460022_XIX_0x1C440022_XIX_Physical, transmitter=TPN_CID_XIX_HCP3_CANFD01_XIX_474349602:
      ident TPCN_HCP3_CANFD01_XIX_TPCHType_CANFD_ISO_Diagnose_XIX_0x1C460022_CID_XIX_0x1C440022_Info_El_XIX_Physical
    can-tp-connection addressing-format=STANDARD, can-tp-channel=TPC_HCP3_CANFD01_XIX_TPCHType_CANFD_ISO_Diagnose_XIX_0x1C440023_XIX_0x1C460023_XIX_Physical, cancellation=true, data-pdu=ISOx_PID_Resp_FD_XIX_HCP3_CANFD01, flow-control-pdu=ISOx_PID_Req_FD_XIX_HCP3_CANFD01, max-block-size=15, padding-activation=true, receiver=TPN_Info_El_XIX_HCP3_CANFD01_XIX_474218531, ta-type=PHYSICAL, timeout-br=0.1, timeout-bs=1.0, timeout-cr=1.0, timeout-cs=0.2, tp-sdu=DCM_HCP3_CANFD01_XIX_TPCHType_CANFD_ISO_Diagnose_XIX_0x1C460023_XIX_0x1C440023_XIX_Physical, transmitter=TPN_PID_XIX_HCP3_CANFD01_XIX_474349603:
      ident TPCN_HCP3_CANFD01_XIX_TPCHType_CANFD_ISO_Diagnose_XIX_0x1C460023_PID_XIX_0x1C440023_Info_El_XIX_Physical
    can-tp-connection addressing-format=STANDARD, can-tp-channel=TPC_HCP3_CANFD01_XIX_TPCHType_CANFD_ISO_Diagnose_XIX_0x1C440024_XIX_0x1C460024_XIX_Physical, cancellation=true, data-pdu=ISOx_CCF_Resp_FD_XIX_HCP3_CANFD01, flow-control-pdu=ISOx_CCF_Req_FD_XIX_HCP3_CANFD01, max-block-size=15, padding-activation=true, receiver=TPN_Info_El_XIX_HCP3_CANFD01_XIX_474218532, ta-type=PHYSICAL, timeout-br=0.1, timeout-bs=1.0, timeout-cr=1.0, timeout-cs=0.2, tp-sdu=DCM_HCP3_CANFD01_XIX_TPCHType_CANFD_ISO_Diagnose_XIX_0x1C460024_XIX_0x1C440024_XIX_Physical, transmitter=TPN_CCF_XIX_HCP3_CANFD01_XIX_474349604:
      ident TPCN_HCP3_CANFD01_XIX_TPCHType_CANFD_ISO_Diagnose_XIX_0x1C460024_CCF_XIX_0x1C440024_Info_El_XIX_Physical
    can-tp-connection addressing-format=STANDARD, can-tp-channel=TPC_HCP3_CANFD01_XIX_TPCHType_CANFD_OBDC_Diagnose_XIX_0x1C40021B_XIX_0x1C42021B_XIX_Physical, cancellation=true, data-pdu=OBDC_HUD_Req_FD_XIX_HCP3_CANFD01, flow-control-pdu=OBDC_HUD_Resp_FD_XIX_HCP3_CANFD01, max-block-size=15, padding-activation=true, receiver=TPN_HUD_XIX_HCP3_CANFD01_XIX_474087963, ta-type=PHYSICAL, timeout-br=0.1, timeout-bs=1.0, timeout-cr=1.0, timeout-cs=0.2, tp-sdu=DCM_HCP3_CANFD01_XIX_TPCHType_CANFD_OBDC_Diagnose_XIX_0x1C40021B_XIX_0x1C42021B_XIX_Physical, transmitter=TPN_Info_El_XIX_HCP3_CANFD01_XIX_473956891:
      ident TPCN_HCP3_CANFD01_XIX_TPCHType_CANFD_OBDC_Diagnose_XIX_0x1C40021B_Info_El_XIX_0x1C42021B_HUD_XIX_Physical
    can-tp-connection addressing-format=STANDARD, can-tp-channel=TPC_HCP3_CANFD01_XIX_TPCHType_CANFD_OBDC_Diagnose_XIX_0x1C4002A5_XIX_0x1C4202A5_XIX_Physical, cancellation=true, data-pdu=OBDC_WLC1_Req_FD_XIX_HCP3_CANFD01, flow-control-pdu=OBDC_WLC1_Resp_FD_XIX_HCP3_CANFD01, max-block-size=15, padding-activation=true, receiver=TPN_WLC1_XIX_HCP3_CANFD01_XIX_474088101, ta-type=PHYSICAL, timeout-br=0.1, timeout-bs=1.0, timeout-cr=1.0, timeout-cs=0.2, tp-sdu=DCM_HCP3_CANFD01_XIX_TPCHType_CANFD_OBDC_Diagnose_XIX_0x1C4002A5_XIX_0x1C4202A5_XIX_Physical, transmitter=TPN_Info_El_XIX_HCP3_CANFD01_XIX_473957029:
      ident TPCN_HCP3_CANFD01_XIX_TPCHType_CANFD_OBDC_Diagnose_XIX_0x1C4002A5_Info_El_XIX_0x1C4202A5_WLC1_XIX_Physical
    can-tp-connection addressing-format=STANDARD, can-tp-channel=TPC_HCP3_CANFD01_XIX_TPCHType_CANFD_OBDC_Diagnose_XIX_0x1C4002A6_XIX_0x1C4202A6_XIX_Physical, cancellation=true, data-pdu=OBDC_WLC2_Req_FD_XIX_HCP3_CANFD01, flow-control-pdu=OBDC_WLC2_Resp_FD_XIX_HCP3_CANFD01, max-block-size=15, padding-activation=true, receiver=TPN_WLC2_XIX_HCP3_CANFD01_XIX_474088102, ta-type=PHYSICAL, timeout-br=0.1, timeout-bs=1.0, timeout-cr=1.0, timeout-cs=0.2, tp-sdu=DCM_HCP3_CANFD01_XIX_TPCHType_CANFD_OBDC_Diagnose_XIX_0x1C4002A6_XIX_0x1C4202A6_XIX_Physical, transmitter=TPN_Info_El_XIX_HCP3_CANFD01_XIX_473957030:
      ident TPCN_HCP3_CANFD01_XIX_TPCHType_CANFD_OBDC_Diagnose_XIX_0x1C4002A6_Info_El_XIX_0x1C4202A6_WLC2_XIX_Physical
    can-tp-connection addressing-format=STANDARD, can-tp-channel=TPC_HCP3_CANFD01_XIX_TPCHType_CANFD_OBDC_Diagnose_XIX_0x1C410200_XIX_Functional, cancellation=true, data-pdu=OBDC_Funktionaler_Req_All_FD_XIX_HCP3_CANFD01, max-block-size=15, multicast=TA_0x1C410200, padding-activation=true, receiver=[TPN_HUD_XIX_HCP3_CANFD01_XIX_474087963, TPN_HUD_XIX_HCP3_CANFD01_XIX_474088101, TPN_HUD_XIX_HCP3_CANFD01_XIX_474088102, TPN_HUD_XIX_HCP3_CANFD01_XIX_474350114, TPN_HUD_XIX_HCP3_CANFD01_XIX_474350115, TPN_HUD_XIX_HCP3_CANFD01_XIX_474350116, TPN_CCF_XIX_HCP3_CANFD01_XIX_474087963, TPN_CCF_XIX_HCP3_CANFD01_XIX_474088101, TPN_CCF_XIX_HCP3_CANFD01_XIX_474088102, TPN_CCF_XIX_HCP3_CANFD01_XIX_474350114, TPN_CCF_XIX_HCP3_CANFD01_XIX_474350115, TPN_CCF_XIX_HCP3_CANFD01_XIX_474350116, TPN_CID_XIX_HCP3_CANFD01_XIX_474087963, TPN_CID_XIX_HCP3_CANFD01_XIX_474088101, TPN_CID_XIX_HCP3_CANFD01_XIX_474088102, TPN_CID_XIX_HCP3_CANFD01_XIX_474350114, TPN_CID_XIX_HCP3_CANFD01_XIX_474350115, TPN_CID_XIX_HCP3_CANFD01_XIX_474350116, TPN_PID_XIX_HCP3_CANFD01_XIX_474087963, TPN_PID_XIX_HCP3_CANFD01_XIX_474088101, TPN_PID_XIX_HCP3_CANFD01_XIX_474088102, TPN_PID_XIX_HCP3_CANFD01_XIX_474350114, TPN_PID_XIX_HCP3_CANFD01_XIX_474350115, TPN_PID_XIX_HCP3_CANFD01_XIX_474350116, TPN_WLC1_XIX_HCP3_CANFD01_XIX_474087963, TPN_WLC1_XIX_HCP3_CANFD01_XIX_474088101, TPN_WLC1_XIX_HCP3_CANFD01_XIX_474088102, TPN_WLC1_XIX_HCP3_CANFD01_XIX_474350114, TPN_WLC1_XIX_HCP3_CANFD01_XIX_474350115, TPN_WLC1_XIX_HCP3_CANFD01_XIX_474350116, TPN_WLC2_XIX_HCP3_CANFD01_XIX_474087963, TPN_WLC2_XIX_HCP3_CANFD01_XIX_474088101, TPN_WLC2_XIX_HCP3_CANFD01_XIX_474088102, TPN_WLC2_XIX_HCP3_CANFD01_XIX_474350114, TPN_WLC2_XIX_HCP3_CANFD01_XIX_474350115, TPN_WLC2_XIX_HCP3_CANFD01_XIX_474350116], ta-type=FUNCTIONAL, timeout-br=0.1, timeout-bs=1.0, timeout-cr=1.0, timeout-cs=0.2, tp-sdu=DCM_HCP3_CANFD01_XIX_TPCHType_CANFD_OBDC_Diagnose_XIX_0x1C410200_XIX_Functional, transmitter=TPN_Info_El_XIX_HCP3_CANFD01_XIX_474022400:
      ident TPCN_HCP3_CANFD01_XIX_TPCHType_CANFD_OBDC_Diagnose_XIX_0x1C410200_Info_El_XIX_Functional
    can-tp-connection addressing-format=STANDARD, can-tp-channel=TPC_HCP3_CANFD01_XIX_TPCHType_CANFD_OBDC_Diagnose_XIX_0x1C40021B_XIX_0x1C42021B_XIX_Physical, cancellation=true, data-pdu=OBDC_HUD_Resp_FD_XIX_HCP3_CANFD01, flow-control-pdu=OBDC_HUD_Req_FD_XIX_HCP3_CANFD01, max-block-size=15, padding-activation=true, receiver=TPN_Info_El_XIX_HCP3_CANFD01_XIX_473956891, ta-type=PHYSICAL, timeout-br=0.1, timeout-bs=1.0, timeout-cr=1.0, timeout-cs=0.2, tp-sdu=DCM_HCP3_CANFD01_XIX_TPCHType_CANFD_OBDC_Diagnose_XIX_0x1C42021B_XIX_0x1C40021B_XIX_Physical, transmitter=TPN_HUD_XIX_HCP3_CANFD01_XIX_474087963:
      ident TPCN_HCP3_CANFD01_XIX_TPCHType_CANFD_OBDC_Diagnose_XIX_0x1C42021B_HUD_XIX_0x1C40021B_Info_El_XIX_Physical
    can-tp-connection addressing-format=STANDARD, can-tp-channel=TPC_HCP3_CANFD01_XIX_TPCHType_CANFD_OBDC_Diagnose_XIX_0x1C4002A5_XIX_0x1C4202A5_XIX_Physical, cancellation=true, data-pdu=OBDC_WLC1_Resp_FD_XIX_HCP3_CANFD01, flow-control-pdu=OBDC_WLC1_Req_FD_XIX_HCP3_CANFD01, max-block-size=15, padding-activation=true, receiver=TPN_Info_El_XIX_HCP3_CANFD01_XIX_473957029, ta-type=PHYSICAL, timeout-br=0.1, timeout-bs=1.0, timeout-cr=1.0, timeout-cs=0.2, tp-sdu=DCM_HCP3_CANFD01_XIX_TPCHType_CANFD_OBDC_Diagnose_XIX_0x1C4202A5_XIX_0x1C4002A5_XIX_Physical, transmitter=TPN_WLC1_XIX_HCP3_CANFD01_XIX_474088101:
      ident TPCN_HCP3_CANFD01_XIX_TPCHType_CANFD_OBDC_Diagnose_XIX_0x1C4202A5_WLC1_XIX_0x1C4002A5_Info_El_XIX_Physical
    can-tp-connection addressing-format=STANDARD, can-tp-channel=TPC_HCP3_CANFD01_XIX_TPCHType_CANFD_OBDC_Diagnose_XIX_0x1C4002A6_XIX_0x1C4202A6_XIX_Physical, cancellation=true, data-pdu=OBDC_WLC2_Resp_FD_XIX_HCP3_CANFD01, flow-control-pdu=OBDC_WLC2_Req_FD_XIX_HCP3_CANFD01, max-block-size=15, padding-activation=true, receiver=TPN_Info_El_XIX_HCP3_CANFD01_XIX_473957030, ta-type=PHYSICAL, timeout-br=0.1, timeout-bs=1.0, timeout-cr=1.0, timeout-cs=0.2, tp-sdu=DCM_HCP3_CANFD01_XIX_TPCHType_CANFD_OBDC_Diagnose_XIX_0x1C4202A6_XIX_0x1C4002A6_XIX_Physical, transmitter=TPN_WLC2_XIX_HCP3_CANFD01_XIX_474088102:
      ident TPCN_HCP3_CANFD01_XIX_TPCHType_CANFD_OBDC_Diagnose_XIX_0x1C4202A6_WLC2_XIX_0x1C4002A6_Info_El_XIX_Physical
    can-tp-connection addressing-format=STANDARD, can-tp-channel=TPC_HCP3_CANFD01_XIX_TPCHType_CANFD_OBDC_Diagnose_XIX_0x1C440222_XIX_0x1C460222_XIX_Physical, cancellation=true, data-pdu=OBDC_CID_Req_FD_XIX_HCP3_CANFD01, flow-control-pdu=OBDC_CID_Resp_FD_XIX_HCP3_CANFD01, max-block-size=15, padding-activation=true, receiver=TPN_CID_XIX_HCP3_CANFD01_XIX_474350114, ta-type=PHYSICAL, timeout-br=0.1, timeout-bs=1.0, timeout-cr=1.0, timeout-cs=0.2, tp-sdu=DCM_HCP3_CANFD01_XIX_TPCHType_CANFD_OBDC_Diagnose_XIX_0x1C440222_XIX_0x1C460222_XIX_Physical, transmitter=TPN_Info_El_XIX_HCP3_CANFD01_XIX_474219042:
      ident TPCN_HCP3_CANFD01_XIX_TPCHType_CANFD_OBDC_Diagnose_XIX_0x1C440222_Info_El_XIX_0x1C460222_CID_XIX_Physical
    can-tp-connection addressing-format=STANDARD, can-tp-channel=TPC_HCP3_CANFD01_XIX_TPCHType_CANFD_OBDC_Diagnose_XIX_0x1C440223_XIX_0x1C460223_XIX_Physical, cancellation=true, data-pdu=OBDC_PID_Req_FD_XIX_HCP3_CANFD01, flow-control-pdu=OBDC_PID_Resp_FD_XIX_HCP3_CANFD01, max-block-size=15, padding-activation=true, receiver=TPN_PID_XIX_HCP3_CANFD01_XIX_474350115, ta-type=PHYSICAL, timeout-br=0.1, timeout-bs=1.0, timeout-cr=1.0, timeout-cs=0.2, tp-sdu=DCM_HCP3_CANFD01_XIX_TPCHType_CANFD_OBDC_Diagnose_XIX_0x1C440223_XIX_0x1C460223_XIX_Physical, transmitter=TPN_Info_El_XIX_HCP3_CANFD01_XIX_474219043:
      ident TPCN_HCP3_CANFD01_XIX_TPCHType_CANFD_OBDC_Diagnose_XIX_0x1C440223_Info_El_XIX_0x1C460223_PID_XIX_Physical
    can-tp-connection addressing-format=STANDARD, can-tp-channel=TPC_HCP3_CANFD01_XIX_TPCHType_CANFD_OBDC_Diagnose_XIX_0x1C440224_XIX_0x1C460224_XIX_Physical, cancellation=true, data-pdu=OBDC_CCF_Req_FD_XIX_HCP3_CANFD01, flow-control-pdu=OBDC_CCF_Resp_FD_XIX_HCP3_CANFD01, max-block-size=15, padding-activation=true, receiver=TPN_CCF_XIX_HCP3_CANFD01_XIX_474350116, ta-type=PHYSICAL, timeout-br=0.1, timeout-bs=1.0, timeout-cr=1.0, timeout-cs=0.2, tp-sdu=DCM_HCP3_CANFD01_XIX_TPCHType_CANFD_OBDC_Diagnose_XIX_0x1C440224_XIX_0x1C460224_XIX_Physical, transmitter=TPN_Info_El_XIX_HCP3_CANFD01_XIX_474219044:
      ident TPCN_HCP3_CANFD01_XIX_TPCHType_CANFD_OBDC_Diagnose_XIX_0x1C440224_Info_El_XIX_0x1C460224_CCF_XIX_Physical
    can-tp-connection addressing-format=STANDARD, can-tp-channel=TPC_HCP3_CANFD01_XIX_TPCHType_CANFD_OBDC_Diagnose_XIX_0x1C440222_XIX_0x1C460222_XIX_Physical, cancellation=true, data-pdu=OBDC_CID_Resp_FD_XIX_HCP3_CANFD01, flow-control-pdu=OBDC_CID_Req_FD_XIX_HCP3_CANFD01, max-block-size=15, padding-activation=true, receiver=TPN_Info_El_XIX_HCP3_CANFD01_XIX_474219042, ta-type=PHYSICAL, timeout-br=0.1, timeout-bs=1.0, timeout-cr=1.0, timeout-cs=0.2, tp-sdu=DCM_HCP3_CANFD01_XIX_TPCHType_CANFD_OBDC_Diagnose_XIX_0x1C460222_XIX_0x1C440222_XIX_Physical, transmitter=TPN_CID_XIX_HCP3_CANFD01_XIX_474350114:
      ident TPCN_HCP3_CANFD01_XIX_TPCHType_CANFD_OBDC_Diagnose_XIX_0x1C460222_CID_XIX_0x1C440222_Info_El_XIX_Physical
    can-tp-connection addressing-format=STANDARD, can-tp-channel=TPC_HCP3_CANFD01_XIX_TPCHType_CANFD_OBDC_Diagnose_XIX_0x1C440223_XIX_0x1C460223_XIX_Physical, cancellation=true, data-pdu=OBDC_PID_Resp_FD_XIX_HCP3_CANFD01, flow-control-pdu=OBDC_PID_Req_FD_XIX_HCP3_CANFD01, max-block-size=15, padding-activation=true, receiver=TPN_Info_El_XIX_HCP3_CANFD01_XIX_474219043, ta-type=PHYSICAL, timeout-br=0.1, timeout-bs=1.0, timeout-cr=1.0, timeout-cs=0.2, tp-sdu=DCM_HCP3_CANFD01_XIX_TPCHType_CANFD_OBDC_Diagnose_XIX_0x1C460223_XIX_0x1C440223_XIX_Physical, transmitter=TPN_PID_XIX_HCP3_CANFD01_XIX_474350115:
      ident TPCN_HCP3_CANFD01_XIX_TPCHType_CANFD_OBDC_Diagnose_XIX_0x1C460223_PID_XIX_0x1C440223_Info_El_XIX_Physical
    can-tp-connection addressing-format=STANDARD, can-tp-channel=TPC_HCP3_CANFD01_XIX_TPCHType_CANFD_OBDC_Diagnose_XIX_0x1C440224_XIX_0x1C460224_XIX_Physical, cancellation=true, data-pdu=OBDC_CCF_Resp_FD_XIX_HCP3_CANFD01, flow-control-pdu=OBDC_CCF_Req_FD_XIX_HCP3_CANFD01, max-block-size=15, padding-activation=true, receiver=TPN_Info_El_XIX_HCP3_CANFD01_XIX_474219044, ta-type=PHYSICAL, timeout-br=0.1, timeout-bs=1.0, timeout-cr=1.0, timeout-cs=0.2, tp-sdu=DCM_HCP3_CANFD01_XIX_TPCHType_CANFD_OBDC_Diagnose_XIX_0x1C460224_XIX_0x1C440224_XIX_Physical, transmitter=TPN_CCF_XIX_HCP3_CANFD01_XIX_474350116:
      ident TPCN_HCP3_CANFD01_XIX_TPCHType_CANFD_OBDC_Diagnose_XIX_0x1C460224_CCF_XIX_0x1C440224_Info_El_XIX_Physical
    can-tp-connection addressing-format=STANDARD, can-tp-channel=TPC_HCP3_CANFD01_XIX_TPCHType_CANFD_OBDC_SSN_Diagnose_XIX_0x1C407093_XIX_0x1C427093_XIX_Physical, cancellation=true, data-pdu=OBDC_SSN_LSR_1_Req_FD_XIX_HCP3_CANFD01, flow-control-pdu=OBDC_SSN_LSR_1_Resp_FD_XIX_HCP3_CANFD01, max-block-size=15, padding-activation=true, receiver=TPN_LSR_1_XIX_HCP3_CANFD01_XIX_474116243, ta-type=PHYSICAL, timeout-br=0.1, timeout-bs=1.0, timeout-cr=1.0, timeout-cs=0.2, tp-sdu=DCM_HCP3_CANFD01_XIX_TPCHType_CANFD_OBDC_SSN_Diagnose_XIX_0x1C407093_XIX_0x1C427093_XIX_Physical, transmitter=TPN_Info_El_XIX_HCP3_CANFD01_XIX_473985171:
      ident TPCN_HCP3_CANFD01_XIX_TPCHType_CANFD_OBDC_SSN_Diagnose_XIX_0x1C407093_Info_El_XIX_0x1C427093_LSR_1_XIX_Physical
    can-tp-connection addressing-format=STANDARD, can-tp-channel=TPC_HCP3_CANFD01_XIX_TPCHType_CANFD_OBDC_SSN_Diagnose_XIX_0x1C407093_XIX_0x1C427093_XIX_Physical, cancellation=true, data-pdu=OBDC_SSN_LSR_1_Resp_FD_XIX_HCP3_CANFD01, flow-control-pdu=OBDC_SSN_LSR_1_Req_FD_XIX_HCP3_CANFD01, max-block-size=15, padding-activation=true, receiver=TPN_Info_El_XIX_HCP3_CANFD01_XIX_473985171, ta-type=PHYSICAL, timeout-br=0.1, timeout-bs=1.0, timeout-cr=1.0, timeout-cs=0.2, tp-sdu=DCM_HCP3_CANFD01_XIX_TPCHType_CANFD_OBDC_SSN_Diagnose_XIX_0x1C427093_XIX_0x1C407093_XIX_Physical, transmitter=TPN_LSR_1_XIX_HCP3_CANFD01_XIX_474116243:
      ident TPCN_HCP3_CANFD01_XIX_TPCHType_CANFD_OBDC_SSN_Diagnose_XIX_0x1C427093_LSR_1_XIX_0x1C407093_Info_El_XIX_Physical
    128 x can tp node, all with max-fc-wait=15, st-min=0.005, timeout-ar=1.0, timeout-as=1.0:
      TPN_HUD_XIX_HCP3_CANFD01_XIX_474087451: tp-address=TA_0x1C42001B
      TPN_HUD_XIX_HCP3_CANFD01_XIX_474087589: tp-address=TA_0x1C4200A5
      TPN_HUD_XIX_HCP3_CANFD01_XIX_474087590: tp-address=TA_0x1C4200A6
      TPN_HUD_XIX_HCP3_CANFD01_XIX_474087963: tp-address=TA_0x1C42021B
      TPN_HUD_XIX_HCP3_CANFD01_XIX_474088101: tp-address=TA_0x1C4202A5
      TPN_HUD_XIX_HCP3_CANFD01_XIX_474088102: tp-address=TA_0x1C4202A6
      TPN_HUD_XIX_HCP3_CANFD01_XIX_474102555: tp-address=TA_0x1C423B1B
      TPN_HUD_XIX_HCP3_CANFD01_XIX_474349602: tp-address=TA_0x1C460022
      TPN_HUD_XIX_HCP3_CANFD01_XIX_474349603: tp-address=TA_0x1C460023
      TPN_HUD_XIX_HCP3_CANFD01_XIX_474349604: tp-address=TA_0x1C460024
      TPN_HUD_XIX_HCP3_CANFD01_XIX_474350114: tp-address=TA_0x1C460222
      TPN_HUD_XIX_HCP3_CANFD01_XIX_474350115: tp-address=TA_0x1C460223
      TPN_HUD_XIX_HCP3_CANFD01_XIX_474350116: tp-address=TA_0x1C460224
      TPN_HUD_XIX_HCP3_CANFD01_XIX_482351931: tp-address=TA_0x1CC01B3B
      TPN_HUD_XIX_HCP3_CANFD01_XIX_486546291: tp-address=TA_0x1D001B73
      TPN_HUD_XIX_HCP3_CANFD01_XIX_486699803: tp-address=TA_0x1D02731B
      TPN_CCF_XIX_HCP3_CANFD01_XIX_474087451: tp-address=TA_0x1C42001B
      TPN_CCF_XIX_HCP3_CANFD01_XIX_474087589: tp-address=TA_0x1C4200A5
      TPN_CCF_XIX_HCP3_CANFD01_XIX_474087590: tp-address=TA_0x1C4200A6
      TPN_CCF_XIX_HCP3_CANFD01_XIX_474087963: tp-address=TA_0x1C42021B
      TPN_CCF_XIX_HCP3_CANFD01_XIX_474088101: tp-address=TA_0x1C4202A5
      TPN_CCF_XIX_HCP3_CANFD01_XIX_474088102: tp-address=TA_0x1C4202A6
      TPN_CCF_XIX_HCP3_CANFD01_XIX_474349602: tp-address=TA_0x1C460022
      TPN_CCF_XIX_HCP3_CANFD01_XIX_474349603: tp-address=TA_0x1C460023
      TPN_CCF_XIX_HCP3_CANFD01_XIX_474349604: tp-address=TA_0x1C460024
      TPN_CCF_XIX_HCP3_CANFD01_XIX_474350114: tp-address=TA_0x1C460222
      TPN_CCF_XIX_HCP3_CANFD01_XIX_474350115: tp-address=TA_0x1C460223
      TPN_CCF_XIX_HCP3_CANFD01_XIX_474350116: tp-address=TA_0x1C460224
      TPN_CCF_XIX_HCP3_CANFD01_XIX_474377252: tp-address=TA_0x1C466C24
      TPN_CCF_XIX_HCP3_CANFD01_XIX_483402860: tp-address=TA_0x1CD0246C
      TPN_CID_XIX_HCP3_CANFD01_XIX_474087451: tp-address=TA_0x1C42001B
      TPN_CID_XIX_HCP3_CANFD01_XIX_474087589: tp-address=TA_0x1C4200A5
      TPN_CID_XIX_HCP3_CANFD01_XIX_474087590: tp-address=TA_0x1C4200A6
      TPN_CID_XIX_HCP3_CANFD01_XIX_474087963: tp-address=TA_0x1C42021B
      TPN_CID_XIX_HCP3_CANFD01_XIX_474088101: tp-address=TA_0x1C4202A5
      TPN_CID_XIX_HCP3_CANFD01_XIX_474088102: tp-address=TA_0x1C4202A6
      TPN_CID_XIX_HCP3_CANFD01_XIX_474349602: tp-address=TA_0x1C460022
      TPN_CID_XIX_HCP3_CANFD01_XIX_474349603: tp-address=TA_0x1C460023
      TPN_CID_XIX_HCP3_CANFD01_XIX_474349604: tp-address=TA_0x1C460024
      TPN_CID_XIX_HCP3_CANFD01_XIX_474350114: tp-address=TA_0x1C460222
      TPN_CID_XIX_HCP3_CANFD01_XIX_474350115: tp-address=TA_0x1C460223
      TPN_CID_XIX_HCP3_CANFD01_XIX_474350116: tp-address=TA_0x1C460224
      TPN_CID_XIX_HCP3_CANFD01_XIX_474376226: tp-address=TA_0x1C466822
      TPN_CID_XIX_HCP3_CANFD01_XIX_474376994: tp-address=TA_0x1C466B22
      TPN_CID_XIX_HCP3_CANFD01_XIX_474377762: tp-address=TA_0x1C466E22
      TPN_CID_XIX_HCP3_CANFD01_XIX_483402344: tp-address=TA_0x1CD02268
      TPN_CID_XIX_HCP3_CANFD01_XIX_483402347: tp-address=TA_0x1CD0226B
      TPN_CID_XIX_HCP3_CANFD01_XIX_483402350: tp-address=TA_0x1CD0226E
      TPN_Info_El_XIX_HCP3_CANFD01_XIX_473956379: connector=CN_HCP3_CANFD01, tp-address=TA_0x1C40001B
      TPN_Info_El_XIX_HCP3_CANFD01_XIX_473956517: connector=CN_HCP3_CANFD01, tp-address=TA_0x1C4000A5
      TPN_Info_El_XIX_HCP3_CANFD01_XIX_473956518: connector=CN_HCP3_CANFD01, tp-address=TA_0x1C4000A6
      TPN_Info_El_XIX_HCP3_CANFD01_XIX_473956891: connector=CN_HCP3_CANFD01, tp-address=TA_0x1C40021B
      TPN_Info_El_XIX_HCP3_CANFD01_XIX_473957029: connector=CN_HCP3_CANFD01, tp-address=TA_0x1C4002A5
      TPN_Info_El_XIX_HCP3_CANFD01_XIX_473957030: connector=CN_HCP3_CANFD01, tp-address=TA_0x1C4002A6
      TPN_Info_El_XIX_HCP3_CANFD01_XIX_473958035: connector=CN_HCP3_CANFD01, tp-address=TA_0x1C400693
      TPN_Info_El_XIX_HCP3_CANFD01_XIX_473962131: connector=CN_HCP3_CANFD01, tp-address=TA_0x1C401693
      TPN_Info_El_XIX_HCP3_CANFD01_XIX_473971483: connector=CN_HCP3_CANFD01, tp-address=TA_0x1C403B1B
      TPN_Info_El_XIX_HCP3_CANFD01_XIX_473985171: connector=CN_HCP3_CANFD01, tp-address=TA_0x1C407093
      TPN_Info_El_XIX_HCP3_CANFD01_XIX_474021888: connector=CN_HCP3_CANFD01, tp-address=TA_0x1C410000
      TPN_Info_El_XIX_HCP3_CANFD01_XIX_474022400: connector=CN_HCP3_CANFD01, tp-address=TA_0x1C410200
      TPN_Info_El_XIX_HCP3_CANFD01_XIX_474218530: connector=CN_HCP3_CANFD01, tp-address=TA_0x1C440022
      TPN_Info_El_XIX_HCP3_CANFD01_XIX_474218531: connector=CN_HCP3_CANFD01, tp-address=TA_0x1C440023
      TPN_Info_El_XIX_HCP3_CANFD01_XIX_474218532: connector=CN_HCP3_CANFD01, tp-address=TA_0x1C440024
      TPN_Info_El_XIX_HCP3_CANFD01_XIX_474219042: connector=CN_HCP3_CANFD01, tp-address=TA_0x1C440222
      TPN_Info_El_XIX_HCP3_CANFD01_XIX_474219043: connector=CN_HCP3_CANFD01, tp-address=TA_0x1C440223
      TPN_Info_El_XIX_HCP3_CANFD01_XIX_474219044: connector=CN_HCP3_CANFD01, tp-address=TA_0x1C440224
      TPN_Info_El_XIX_HCP3_CANFD01_XIX_474244899: connector=CN_HCP3_CANFD01, tp-address=TA_0x1C446723
      TPN_Info_El_XIX_HCP3_CANFD01_XIX_474245154: connector=CN_HCP3_CANFD01, tp-address=TA_0x1C446822
      TPN_Info_El_XIX_HCP3_CANFD01_XIX_474245667: connector=CN_HCP3_CANFD01, tp-address=TA_0x1C446A23
      TPN_Info_El_XIX_HCP3_CANFD01_XIX_474245922: connector=CN_HCP3_CANFD01, tp-address=TA_0x1C446B22
      TPN_Info_El_XIX_HCP3_CANFD01_XIX_474246180: connector=CN_HCP3_CANFD01, tp-address=TA_0x1C446C24
      TPN_Info_El_XIX_HCP3_CANFD01_XIX_474246435: connector=CN_HCP3_CANFD01, tp-address=TA_0x1C446D23
      TPN_Info_El_XIX_HCP3_CANFD01_XIX_474246690: connector=CN_HCP3_CANFD01, tp-address=TA_0x1C446E22
      TPN_Info_El_XIX_HCP3_CANFD01_XIX_482483003: connector=CN_HCP3_CANFD01, tp-address=TA_0x1CC21B3B
      TPN_Info_El_XIX_HCP3_CANFD01_XIX_483533416: connector=CN_HCP3_CANFD01, tp-address=TA_0x1CD22268
      TPN_Info_El_XIX_HCP3_CANFD01_XIX_483533419: connector=CN_HCP3_CANFD01, tp-address=TA_0x1CD2226B
      TPN_Info_El_XIX_HCP3_CANFD01_XIX_483533422: connector=CN_HCP3_CANFD01, tp-address=TA_0x1CD2226E
      TPN_Info_El_XIX_HCP3_CANFD01_XIX_483533671: connector=CN_HCP3_CANFD01, tp-address=TA_0x1CD22367
      TPN_Info_El_XIX_HCP3_CANFD01_XIX_483533674: connector=CN_HCP3_CANFD01, tp-address=TA_0x1CD2236A
      TPN_Info_El_XIX_HCP3_CANFD01_XIX_483533677: connector=CN_HCP3_CANFD01, tp-address=TA_0x1CD2236D
      TPN_Info_El_XIX_HCP3_CANFD01_XIX_483533932: connector=CN_HCP3_CANFD01, tp-address=TA_0x1CD2246C
      TPN_Info_El_XIX_HCP3_CANFD01_XIX_486568731: connector=CN_HCP3_CANFD01, tp-address=TA_0x1D00731B
      TPN_Info_El_XIX_HCP3_CANFD01_XIX_486677363: connector=CN_HCP3_CANFD01, tp-address=TA_0x1D021B73
      TPN_LSR_1_XIX_HCP3_CANFD01_XIX_474089107: tp-address=TA_0x1C420693
      TPN_LSR_1_XIX_HCP3_CANFD01_XIX_474093203: tp-address=TA_0x1C421693
      TPN_LSR_1_XIX_HCP3_CANFD01_XIX_474116243: tp-address=TA_0x1C427093
      TPN_PID_XIX_HCP3_CANFD01_XIX_474087451: tp-address=TA_0x1C42001B
      TPN_PID_XIX_HCP3_CANFD01_XIX_474087589: tp-address=TA_0x1C4200A5
      TPN_PID_XIX_HCP3_CANFD01_XIX_474087590: tp-address=TA_0x1C4200A6
      TPN_PID_XIX_HCP3_CANFD01_XIX_474087963: tp-address=TA_0x1C42021B
      TPN_PID_XIX_HCP3_CANFD01_XIX_474088101: tp-address=TA_0x1C4202A5
      TPN_PID_XIX_HCP3_CANFD01_XIX_474088102: tp-address=TA_0x1C4202A6
      TPN_PID_XIX_HCP3_CANFD01_XIX_474349602: tp-address=TA_0x1C460022
      TPN_PID_XIX_HCP3_CANFD01_XIX_474349603: tp-address=TA_0x1C460023
      TPN_PID_XIX_HCP3_CANFD01_XIX_474349604: tp-address=TA_0x1C460024
      TPN_PID_XIX_HCP3_CANFD01_XIX_474350114: tp-address=TA_0x1C460222
      TPN_PID_XIX_HCP3_CANFD01_XIX_474350115: tp-address=TA_0x1C460223
      TPN_PID_XIX_HCP3_CANFD01_XIX_474350116: tp-address=TA_0x1C460224
      TPN_PID_XIX_HCP3_CANFD01_XIX_474375971: tp-address=TA_0x1C466723
      TPN_PID_XIX_HCP3_CANFD01_XIX_474376739: tp-address=TA_0x1C466A23
      TPN_PID_XIX_HCP3_CANFD01_XIX_474377507: tp-address=TA_0x1C466D23
      TPN_PID_XIX_HCP3_CANFD01_XIX_483402599: tp-address=TA_0x1CD02367
      TPN_PID_XIX_HCP3_CANFD01_XIX_483402602: tp-address=TA_0x1CD0236A
      TPN_PID_XIX_HCP3_CANFD01_XIX_483402605: tp-address=TA_0x1CD0236D
      TPN_WLC1_XIX_HCP3_CANFD01_XIX_474087451: tp-address=TA_0x1C42001B
      TPN_WLC1_XIX_HCP3_CANFD01_XIX_474087589: tp-address=TA_0x1C4200A5
      TPN_WLC1_XIX_HCP3_CANFD01_XIX_474087590: tp-address=TA_0x1C4200A6
      TPN_WLC1_XIX_HCP3_CANFD01_XIX_474087963: tp-address=TA_0x1C42021B
      TPN_WLC1_XIX_HCP3_CANFD01_XIX_474088101: tp-address=TA_0x1C4202A5
      TPN_WLC1_XIX_HCP3_CANFD01_XIX_474088102: tp-address=TA_0x1C4202A6
      TPN_WLC1_XIX_HCP3_CANFD01_XIX_474349602: tp-address=TA_0x1C460022
      TPN_WLC1_XIX_HCP3_CANFD01_XIX_474349603: tp-address=TA_0x1C460023
      TPN_WLC1_XIX_HCP3_CANFD01_XIX_474349604: tp-address=TA_0x1C460024
      TPN_WLC1_XIX_HCP3_CANFD01_XIX_474350114: tp-address=TA_0x1C460222
      TPN_WLC1_XIX_HCP3_CANFD01_XIX_474350115: tp-address=TA_0x1C460223
      TPN_WLC1_XIX_HCP3_CANFD01_XIX_474350116: tp-address=TA_0x1C460224
      TPN_WLC2_XIX_HCP3_CANFD01_XIX_474087451: tp-address=TA_0x1C42001B
      TPN_WLC2_XIX_HCP3_CANFD01_XIX_474087589: tp-address=TA_0x1C4200A5
      TPN_WLC2_XIX_HCP3_CANFD01_XIX_474087590: tp-address=TA_0x1C4200A6
      TPN_WLC2_XIX_HCP3_CANFD01_XIX_474087963: tp-address=TA_0x1C42021B
      TPN_WLC2_XIX_HCP3_CANFD01_XIX_474088101: tp-address=TA_0x1C4202A5
      TPN_WLC2_XIX_HCP3_CANFD01_XIX_474088102: tp-address=TA_0x1C4202A6
      TPN_WLC2_XIX_HCP3_CANFD01_XIX_474349602: tp-address=TA_0x1C460022
      TPN_WLC2_XIX_HCP3_CANFD01_XIX_474349603: tp-address=TA_0x1C460023
      TPN_WLC2_XIX_HCP3_CANFD01_XIX_474349604: tp-address=TA_0x1C460024
      TPN_WLC2_XIX_HCP3_CANFD01_XIX_474350114: tp-address=TA_0x1C460222
      TPN_WLC2_XIX_HCP3_CANFD01_XIX_474350115: tp-address=TA_0x1C460223
      TPN_WLC2_XIX_HCP3_CANFD01_XIX_474350116: tp-address=TA_0x1C460224
  do ip tp config DoIPTPConfig_ETH_Cluster_E3_1_2: communication-cluster=ETH_Cluster_E3_1_2
    11 x do ip logic address:
      DLA_XIX_0xE80: address=3712
      DLA_XIX_0xE400: address=58368
      DLA_XIX_0x3124: address=12580
      DLA_XIX_0x3122: address=12578
      DLA_XIX_0x1073: address=4211
      DLA_XIX_0x101B: address=4123
      DLA_XIX_0x3493: address=13459
      DLA_XIX_0x3123: address=12579
      DLA_XIX_0x30A5: address=12453
      DLA_XIX_0x30A6: address=12454
      DLA_XIX_0xF02: address=3842
    do-ip-tp-connection do-ip-source-address=DLA_XIX_0xE80, do-ip-target-address=DLA_XIX_0xE400, tp-sdu=PT_VLAN_Cockpit_XIX_TPCHType_DoIP_Cockpit_XIX_0xE80_XIX_Functional:
      ident TPCN_VLAN_Cockpit_XIX_TPCHType_DoIP_Cockpit_XIX_0xE80_ICAS1Sys02_XIX_Functional
    do-ip-tp-connection do-ip-source-address=DLA_XIX_0xE80, do-ip-target-address=DLA_XIX_0x3124, tp-sdu=PT_VLAN_Cockpit_XIX_TPCHType_DoIP_Cockpit_XIX_0xE80_XIX_0x3124_XIX_Physical:
      ident TPCN_VLAN_Cockpit_XIX_TPCHType_DoIP_Cockpit_XIX_0xE80_ICAS1Sys02_XIX_0x3124_Info_El_XIX_Physical
    do-ip-tp-connection do-ip-source-address=DLA_XIX_0x3124, do-ip-target-address=DLA_XIX_0xE80, tp-sdu=PT_VLAN_Cockpit_XIX_TPCHType_DoIP_Cockpit_XIX_0x3124_XIX_0xE80_XIX_Physical:
      ident TPCN_VLAN_Cockpit_XIX_TPCHType_DoIP_Cockpit_XIX_0x3124_Info_El_XIX_0xE80_ICAS1Sys02_XIX_Physical
    do-ip-tp-connection do-ip-source-address=DLA_XIX_0xE80, do-ip-target-address=DLA_XIX_0x3122, tp-sdu=PT_VLAN_Cockpit_XIX_TPCHType_DoIP_Cockpit_XIX_0xE80_XIX_0x3122_XIX_Physical:
      ident TPCN_VLAN_Cockpit_XIX_TPCHType_DoIP_Cockpit_XIX_0xE80_ICAS1Sys02_XIX_0x3122_Info_El_XIX_Physical
    do-ip-tp-connection do-ip-source-address=DLA_XIX_0x3122, do-ip-target-address=DLA_XIX_0xE80, tp-sdu=PT_VLAN_Cockpit_XIX_TPCHType_DoIP_Cockpit_XIX_0x3122_XIX_0xE80_XIX_Physical:
      ident TPCN_VLAN_Cockpit_XIX_TPCHType_DoIP_Cockpit_XIX_0x3122_Info_El_XIX_0xE80_ICAS1Sys02_XIX_Physical
    do-ip-tp-connection do-ip-source-address=DLA_XIX_0xE80, do-ip-target-address=DLA_XIX_0x1073, tp-sdu=PT_VLAN_Cockpit_XIX_TPCHType_DoIP_Cockpit_XIX_0xE80_XIX_0x1073_XIX_Physical:
      ident TPCN_VLAN_Cockpit_XIX_TPCHType_DoIP_Cockpit_XIX_0xE80_ICAS1Sys02_XIX_0x1073_Info_El_XIX_Physical
    do-ip-tp-connection do-ip-source-address=DLA_XIX_0x1073, do-ip-target-address=DLA_XIX_0xE80, tp-sdu=PT_VLAN_Cockpit_XIX_TPCHType_DoIP_Cockpit_XIX_0x1073_XIX_0xE80_XIX_Physical:
      ident TPCN_VLAN_Cockpit_XIX_TPCHType_DoIP_Cockpit_XIX_0x1073_Info_El_XIX_0xE80_ICAS1Sys02_XIX_Physical
    do-ip-tp-connection do-ip-source-address=DLA_XIX_0xE80, do-ip-target-address=DLA_XIX_0x101B, tp-sdu=PT_VLAN_Cockpit_XIX_TPCHType_DoIP_Cockpit_XIX_0xE80_XIX_0x101B_XIX_Physical:
      ident TPCN_VLAN_Cockpit_XIX_TPCHType_DoIP_Cockpit_XIX_0xE80_ICAS1Sys02_XIX_0x101B_Info_El_XIX_Physical
    do-ip-tp-connection do-ip-source-address=DLA_XIX_0x101B, do-ip-target-address=DLA_XIX_0xE80, tp-sdu=PT_VLAN_Cockpit_XIX_TPCHType_DoIP_Cockpit_XIX_0x101B_XIX_0xE80_XIX_Physical:
      ident TPCN_VLAN_Cockpit_XIX_TPCHType_DoIP_Cockpit_XIX_0x101B_Info_El_XIX_0xE80_ICAS1Sys02_XIX_Physical
    do-ip-tp-connection do-ip-source-address=DLA_XIX_0xE80, do-ip-target-address=DLA_XIX_0x3493, tp-sdu=PT_VLAN_Cockpit_XIX_TPCHType_DoIP_Cockpit_XIX_0xE80_XIX_0x3493_XIX_Physical:
      ident TPCN_VLAN_Cockpit_XIX_TPCHType_DoIP_Cockpit_XIX_0xE80_ICAS1Sys02_XIX_0x3493_Info_El_XIX_Physical
    do-ip-tp-connection do-ip-source-address=DLA_XIX_0x3493, do-ip-target-address=DLA_XIX_0xE80, tp-sdu=PT_VLAN_Cockpit_XIX_TPCHType_DoIP_Cockpit_XIX_0x3493_XIX_0xE80_XIX_Physical:
      ident TPCN_VLAN_Cockpit_XIX_TPCHType_DoIP_Cockpit_XIX_0x3493_Info_El_XIX_0xE80_ICAS1Sys02_XIX_Physical
    do-ip-tp-connection do-ip-source-address=DLA_XIX_0xE80, do-ip-target-address=DLA_XIX_0x3123, tp-sdu=PT_VLAN_Cockpit_XIX_TPCHType_DoIP_Cockpit_XIX_0xE80_XIX_0x3123_XIX_Physical:
      ident TPCN_VLAN_Cockpit_XIX_TPCHType_DoIP_Cockpit_XIX_0xE80_ICAS1Sys02_XIX_0x3123_Info_El_XIX_Physical
    do-ip-tp-connection do-ip-source-address=DLA_XIX_0x3123, do-ip-target-address=DLA_XIX_0xE80, tp-sdu=PT_VLAN_Cockpit_XIX_TPCHType_DoIP_Cockpit_XIX_0x3123_XIX_0xE80_XIX_Physical:
      ident TPCN_VLAN_Cockpit_XIX_TPCHType_DoIP_Cockpit_XIX_0x3123_Info_El_XIX_0xE80_ICAS1Sys02_XIX_Physical
    do-ip-tp-connection do-ip-source-address=DLA_XIX_0xE80, do-ip-target-address=DLA_XIX_0x30A5, tp-sdu=PT_VLAN_Cockpit_XIX_TPCHType_DoIP_Cockpit_XIX_0xE80_XIX_0x30A5_XIX_Physical:
      ident TPCN_VLAN_Cockpit_XIX_TPCHType_DoIP_Cockpit_XIX_0xE80_ICAS1Sys02_XIX_0x30A5_Info_El_XIX_Physical
    do-ip-tp-connection do-ip-source-address=DLA_XIX_0x30A5, do-ip-target-address=DLA_XIX_0xE80, tp-sdu=PT_VLAN_Cockpit_XIX_TPCHType_DoIP_Cockpit_XIX_0x30A5_XIX_0xE80_XIX_Physical:
      ident TPCN_VLAN_Cockpit_XIX_TPCHType_DoIP_Cockpit_XIX_0x30A5_Info_El_XIX_0xE80_ICAS1Sys02_XIX_Physical
    do-ip-tp-connection do-ip-source-address=DLA_XIX_0xE80, do-ip-target-address=DLA_XIX_0x30A6, tp-sdu=PT_VLAN_Cockpit_XIX_TPCHType_DoIP_Cockpit_XIX_0xE80_XIX_0x30A6_XIX_Physical:
      ident TPCN_VLAN_Cockpit_XIX_TPCHType_DoIP_Cockpit_XIX_0xE80_ICAS1Sys02_XIX_0x30A6_Info_El_XIX_Physical
    do-ip-tp-connection do-ip-source-address=DLA_XIX_0x30A6, do-ip-target-address=DLA_XIX_0xE80, tp-sdu=PT_VLAN_Cockpit_XIX_TPCHType_DoIP_Cockpit_XIX_0x30A6_XIX_0xE80_XIX_Physical:
      ident TPCN_VLAN_Cockpit_XIX_TPCHType_DoIP_Cockpit_XIX_0x30A6_Info_El_XIX_0xE80_ICAS1Sys02_XIX_Physical
    do-ip-tp-connection do-ip-source-address=DLA_XIX_0xF02, do-ip-target-address=DLA_XIX_0xE400, tp-sdu=PT_VLAN_Cockpit_XIX_TPCHType_DoIP_Cockpit_OBDC_XIX_0xF02_XIX_Functional:
      ident TPCN_VLAN_Cockpit_XIX_TPCHType_DoIP_Cockpit_OBDC_XIX_0xF02_ICAS1Sys02_XIX_Functional
    do-ip-tp-connection do-ip-source-address=DLA_XIX_0xF02, do-ip-target-address=DLA_XIX_0x3124, tp-sdu=PT_VLAN_Cockpit_XIX_TPCHType_DoIP_Cockpit_OBDC_XIX_0xF02_XIX_0x3124_XIX_Physical:
      ident TPCN_VLAN_Cockpit_XIX_TPCHType_DoIP_Cockpit_OBDC_XIX_0xF02_ICAS1Sys02_XIX_0x3124_Info_El_XIX_Physical
    do-ip-tp-connection do-ip-source-address=DLA_XIX_0x3124, do-ip-target-address=DLA_XIX_0xF02, tp-sdu=PT_VLAN_Cockpit_XIX_TPCHType_DoIP_Cockpit_OBDC_XIX_0x3124_XIX_0xF02_XIX_Physical:
      ident TPCN_VLAN_Cockpit_XIX_TPCHType_DoIP_Cockpit_OBDC_XIX_0x3124_Info_El_XIX_0xF02_ICAS1Sys02_XIX_Physical
    do-ip-tp-connection do-ip-source-address=DLA_XIX_0xF02, do-ip-target-address=DLA_XIX_0x3122, tp-sdu=PT_VLAN_Cockpit_XIX_TPCHType_DoIP_Cockpit_OBDC_XIX_0xF02_XIX_0x3122_XIX_Physical:
      ident TPCN_VLAN_Cockpit_XIX_TPCHType_DoIP_Cockpit_OBDC_XIX_0xF02_ICAS1Sys02_XIX_0x3122_Info_El_XIX_Physical
    do-ip-tp-connection do-ip-source-address=DLA_XIX_0x3122, do-ip-target-address=DLA_XIX_0xF02, tp-sdu=PT_VLAN_Cockpit_XIX_TPCHType_DoIP_Cockpit_OBDC_XIX_0x3122_XIX_0xF02_XIX_Physical:
      ident TPCN_VLAN_Cockpit_XIX_TPCHType_DoIP_Cockpit_OBDC_XIX_0x3122_Info_El_XIX_0xF02_ICAS1Sys02_XIX_Physical
    do-ip-tp-connection do-ip-source-address=DLA_XIX_0xF02, do-ip-target-address=DLA_XIX_0x101B, tp-sdu=PT_VLAN_Cockpit_XIX_TPCHType_DoIP_Cockpit_OBDC_XIX_0xF02_XIX_0x101B_XIX_Physical:
      ident TPCN_VLAN_Cockpit_XIX_TPCHType_DoIP_Cockpit_OBDC_XIX_0xF02_ICAS1Sys02_XIX_0x101B_Info_El_XIX_Physical
    do-ip-tp-connection do-ip-source-address=DLA_XIX_0x101B, do-ip-target-address=DLA_XIX_0xF02, tp-sdu=PT_VLAN_Cockpit_XIX_TPCHType_DoIP_Cockpit_OBDC_XIX_0x101B_XIX_0xF02_XIX_Physical:
      ident TPCN_VLAN_Cockpit_XIX_TPCHType_DoIP_Cockpit_OBDC_XIX_0x101B_Info_El_XIX_0xF02_ICAS1Sys02_XIX_Physical
    do-ip-tp-connection do-ip-source-address=DLA_XIX_0xF02, do-ip-target-address=DLA_XIX_0x3493, tp-sdu=PT_VLAN_Cockpit_XIX_TPCHType_DoIP_Cockpit_OBDC_XIX_0xF02_XIX_0x3493_XIX_Physical:
      ident TPCN_VLAN_Cockpit_XIX_TPCHType_DoIP_Cockpit_OBDC_XIX_0xF02_ICAS1Sys02_XIX_0x3493_Info_El_XIX_Physical
    do-ip-tp-connection do-ip-source-address=DLA_XIX_0x3493, do-ip-target-address=DLA_XIX_0xF02, tp-sdu=PT_VLAN_Cockpit_XIX_TPCHType_DoIP_Cockpit_OBDC_XIX_0x3493_XIX_0xF02_XIX_Physical:
      ident TPCN_VLAN_Cockpit_XIX_TPCHType_DoIP_Cockpit_OBDC_XIX_0x3493_Info_El_XIX_0xF02_ICAS1Sys02_XIX_Physical
    do-ip-tp-connection do-ip-source-address=DLA_XIX_0xF02, do-ip-target-address=DLA_XIX_0x3123, tp-sdu=PT_VLAN_Cockpit_XIX_TPCHType_DoIP_Cockpit_OBDC_XIX_0xF02_XIX_0x3123_XIX_Physical:
      ident TPCN_VLAN_Cockpit_XIX_TPCHType_DoIP_Cockpit_OBDC_XIX_0xF02_ICAS1Sys02_XIX_0x3123_Info_El_XIX_Physical
    do-ip-tp-connection do-ip-source-address=DLA_XIX_0x3123, do-ip-target-address=DLA_XIX_0xF02, tp-sdu=PT_VLAN_Cockpit_XIX_TPCHType_DoIP_Cockpit_OBDC_XIX_0x3123_XIX_0xF02_XIX_Physical:
      ident TPCN_VLAN_Cockpit_XIX_TPCHType_DoIP_Cockpit_OBDC_XIX_0x3123_Info_El_XIX_0xF02_ICAS1Sys02_XIX_Physical
    do-ip-tp-connection do-ip-source-address=DLA_XIX_0xF02, do-ip-target-address=DLA_XIX_0x1073, tp-sdu=PT_VLAN_Cockpit_XIX_TPCHType_DoIP_Cockpit_OBDC_XIX_0xF02_XIX_0x1073_XIX_Physical:
      ident TPCN_VLAN_Cockpit_XIX_TPCHType_DoIP_Cockpit_OBDC_XIX_0xF02_ICAS1Sys02_XIX_0x1073_Info_El_XIX_Physical
    do-ip-tp-connection do-ip-source-address=DLA_XIX_0x1073, do-ip-target-address=DLA_XIX_0xF02, tp-sdu=PT_VLAN_Cockpit_XIX_TPCHType_DoIP_Cockpit_OBDC_XIX_0x1073_XIX_0xF02_XIX_Physical:
      ident TPCN_VLAN_Cockpit_XIX_TPCHType_DoIP_Cockpit_OBDC_XIX_0x1073_Info_El_XIX_0xF02_ICAS1Sys02_XIX_Physical
    do-ip-tp-connection do-ip-source-address=DLA_XIX_0xF02, do-ip-target-address=DLA_XIX_0x30A5, tp-sdu=PT_VLAN_Cockpit_XIX_TPCHType_DoIP_Cockpit_OBDC_XIX_0xF02_XIX_0x30A5_XIX_Physical:
      ident TPCN_VLAN_Cockpit_XIX_TPCHType_DoIP_Cockpit_OBDC_XIX_0xF02_ICAS1Sys02_XIX_0x30A5_Info_El_XIX_Physical
    do-ip-tp-connection do-ip-source-address=DLA_XIX_0x30A5, do-ip-target-address=DLA_XIX_0xF02, tp-sdu=PT_VLAN_Cockpit_XIX_TPCHType_DoIP_Cockpit_OBDC_XIX_0x30A5_XIX_0xF02_XIX_Physical:
      ident TPCN_VLAN_Cockpit_XIX_TPCHType_DoIP_Cockpit_OBDC_XIX_0x30A5_Info_El_XIX_0xF02_ICAS1Sys02_XIX_Physical
    do-ip-tp-connection do-ip-source-address=DLA_XIX_0xF02, do-ip-target-address=DLA_XIX_0x30A6, tp-sdu=PT_VLAN_Cockpit_XIX_TPCHType_DoIP_Cockpit_OBDC_XIX_0xF02_XIX_0x30A6_XIX_Physical:
      ident TPCN_VLAN_Cockpit_XIX_TPCHType_DoIP_Cockpit_OBDC_XIX_0xF02_ICAS1Sys02_XIX_0x30A6_Info_El_XIX_Physical
    do-ip-tp-connection do-ip-source-address=DLA_XIX_0x30A6, do-ip-target-address=DLA_XIX_0xF02, tp-sdu=PT_VLAN_Cockpit_XIX_TPCHType_DoIP_Cockpit_OBDC_XIX_0x30A6_XIX_0xF02_XIX_Physical:
      ident TPCN_VLAN_Cockpit_XIX_TPCHType_DoIP_Cockpit_OBDC_XIX_0x30A6_Info_El_XIX_0xF02_ICAS1Sys02_XIX_Physical
package /SecureCommunication
  secure communication props set SecureCommunicationPropsSet
    secure communication authentication props SecureCommunicationAuthenticationProps_XIX_32: category=VW_PROFILE, auth-algorithm=SipHash24, auth-info-tx-length=32
    secure communication authentication props SecureCommunicationAuthenticationProps_Aes128_XIX_32: category=VW_PROFILE, auth-algorithm=AES128, auth-info-tx-length=32
    secure communication authentication props SecureCommunicationAuthenticationProps_XIX_64: category=VW_PROFILE, auth-algorithm=SipHash24, auth-info-tx-length=64
    secure communication freshness props SecureCommunicationFreshnessProps: category=VW_PROFILE, freshness-value-length=64, freshness-value-tx-length=0
package /DiagnosticServices
  diagnostic connection DC_HCP3_IONode_XIX_TPCHType_DoIP_Cockpit_OBDC: functional-request=TPCN_VLAN_Cockpit_XIX_TPCHType_DoIP_Cockpit_OBDC_XIX_0xF02_ICAS1Sys02_XIX_Functional, physical-request=TPCN_VLAN_Cockpit_XIX_TPCHType_DoIP_Cockpit_OBDC_XIX_0xF02_ICAS1Sys02_XIX_0x1073_Info_El_XIX_Physical, response=TPCN_VLAN_Cockpit_XIX_TPCHType_DoIP_Cockpit_OBDC_XIX_0x1073_Info_El_XIX_0xF02_ICAS1Sys02_XIX_Physical
  diagnostic connection DC_HCP3_IONode_XIX_TPCHType_DoIP_Cockpit: functional-request=TPCN_VLAN_Cockpit_XIX_TPCHType_DoIP_Cockpit_XIX_0xE80_ICAS1Sys02_XIX_Functional, physical-request=TPCN_VLAN_Cockpit_XIX_TPCHType_DoIP_Cockpit_XIX_0xE80_ICAS1Sys02_XIX_0x1073_Info_El_XIX_Physical, response=TPCN_VLAN_Cockpit_XIX_TPCHType_DoIP_Cockpit_XIX_0x1073_Info_El_XIX_0xE80_ICAS1Sys02_XIX_Physical
  diagnostic service table DST_HCP3_IONode: diagnostic-connections=[DC_HCP3_IONode_XIX_TPCHType_DoIP_Cockpit, DC_HCP3_IONode_XIX_TPCHType_DoIP_Cockpit_OBDC], ecu-instance=HCP3_IONode
package /SoAdRoutingGroup
  15 x so ad routing group:
    SoAdRG_WakeupclusterConfiguration_Instance1_configurationsEvent: event-group-control-type=ACTIVATION-UNICAST
    SoAdRG_WakeupclusterConfiguration_Instance1_Methods
    SoAdRG_WakeUpMonitorData_Instance3_Methods
    SoAdRG_SOMEIPTestabilityClient_Instance65534_TestFieldUInt8: event-group-control-type=ACTIVATION-AND-TRIGGER-UNICAST
    SoAdRG_SOMEIPTestabilityClient_Instance65534_testEventUInt8: event-group-control-type=ACTIVATION-UNICAST
    SoAdRG_SOMEIPTestabilityClient_Instance65534_Methods
    SoAdRG_SOMEIPTestabilityReliable_Instance1_TestFieldUInt64: event-group-control-type=ACTIVATION-AND-TRIGGER-UNICAST
    SoAdRG_SOMEIPTestabilityReliable_Instance1_testEventUInt8: event-group-control-type=ACTIVATION-UNICAST
    SoAdRG_SOMEIPTestabilityReliable_Instance1_TestFieldComplexStruct: event-group-control-type=ACTIVATION-AND-TRIGGER-UNICAST
    SoAdRG_SOMEIPTestabilityReliable_Instance1_TestFieldUInt8: event-group-control-type=ACTIVATION-AND-TRIGGER-UNICAST
    SoAdRG_SOMEIPTestabilityReliable_Instance1_Methods
    SoAdRG_IdsCanSensor_Instance3_periodicSignalElement0: event-group-control-type=ACTIVATION-AND-TRIGGER-UNICAST
    SoAdRG_IdsCanSensor_Instance3_canSensorFeaturesElement0: event-group-control-type=ACTIVATION-AND-TRIGGER-UNICAST
    SoAdRG_IdsCanSensor_Instance3_Methods
    SoAdRG_IDSSecurityEventSmall_Instance3_securityEvent: event-group-control-type=ACTIVATION-UNICAST
package /Interfaces
  419 x sender receiver interface:
    WakeupclusterConfigurationEvents
      data configurationsEvent: sw-impl-policy=QUEUED, type=AT_ConfigurationsEventApp
    WakeUpMonitorDataRnRMethods
      data configuration: sw-impl-policy=QUEUED, type=AT_ConfigurationTableApp
    SOMEIPTestabilityClientRnRMethods
      5 x data, all with sw-impl-policy=QUEUED:
        rnrEchoComplexDynamicArray: type=rnrEchoComplexDynamicArray_arg1ComplexDynArrayApp
        rnrEchoFloat32: type=rnrEchoFloat32_arg1Float32_typeApp
        rnrEchoUInt8UInt16UInt32: type=AT_RnRTestStructThreeArgumentsApp
        rnrEchoComplexStruct: type=AT_TestComplexStructApp
        noResponseUInt8: type=noResponseUInt8_inUInt8_typeApp
    SOMEIPTestabilityClientEvents
      data testEventUInt8: sw-impl-policy=QUEUED, type=testEventUInt8_data_typeApp
      data TestFieldUInt8: type=TestFieldUInt8_typeApp
    SOMEIPTestabilityReliableRnRMethods
      12 x data, all with sw-impl-policy=QUEUED:
        triggerEchoFloat32: type=triggerEchoFloat32_arg1Float32_typeApp
        triggerGetterUInt8: type=boolean
        triggerSetterUInt8: type=triggerSetterUInt8_inUInt8_typeApp
        triggerEchoComplexStruct: type=SOMEIPTestabilityReliable_AT_TestComplexStructApp
        triggerFireForgetUInt8: type=triggerFireForgetUInt8_inUInt8_typeApp
        triggerEchoLargeDataArray: type=AT_RnRTriggerEchoLDACmdTypeApp
        triggerFieldMulticast: type=triggerFieldMulticast_n_typeApp
        triggerEchoUInt8UInt16UInt32: type=SOMEIPTestabilityReliable_AT_RnRTestStructThreeArgumentsApp
        triggerEchoUInt8: type=triggerEchoUInt8_inUInt8_typeApp
        noResponseUInt8: type=SOMEIPTestabilityReliable_noResponseUInt8_inUInt8_typeApp
        triggerEventUInt8: type=triggerEventUInt8_n_typeApp
        triggerEchoComplexDynamicArray: type=triggerEchoComplexDynamicArray_arg1ComplexDynArrayApp
    SOMEIPTestabilityReliableEvents
      4 x data:
        testEventUInt8: sw-impl-policy=QUEUED, type=SOMEIPTestabilityReliable_testEventUInt8_data_typeApp
        TestFieldComplexStruct: type=SOMEIPTestabilityReliable_AT_TestComplexStructApp
        TestFieldUInt64: type=TestFieldUInt64_typeApp
        TestFieldUInt8: type=SOMEIPTestabilityReliable_TestFieldUInt8_typeApp
    IdsCanSensorEvents
      data canSensorFeaturesElement0: type=AT_CanSensorFeaturesTypeApp
      data periodicSignalElement0: type=AT_PeriodicSignalTypeApp
    IDSSecurityEventSmallEvents
      data securityEvent: sw-impl-policy=QUEUED, type=AT_SecurityEventStructApp
    IF_FT_Tuer_geoeffnet
      data DE_FT_Tuer_geoeffnet: type=boolean
    IF_STH_KVS_Ueberlauf
      data DE_STH_KVS_Ueberlauf: type=boolean
    IF_STH_KVS
      data DE_STH_KVS: type=uint16
    IF_OBD_Driving_Cycle
      data DE_OBD_Driving_Cycle: type=boolean
    IF_OBD_Warm_Up_Cycle
      data DE_OBD_Warm_Up_Cycle: type=boolean
    IF_VIN_1
      data DE_VIN_1: type=uint8
    IF_VIN_2
      data DE_VIN_2: type=uint8
    IF_VIN_3
      data DE_VIN_3: type=uint8
    IF_VIN_4
      data DE_VIN_4: type=uint8
    IF_VIN_5
      data DE_VIN_5: type=uint8
    IF_VIN_6
      data DE_VIN_6: type=uint8
    IF_VIN_7
      data DE_VIN_7: type=uint8
    IF_VIN_8
      data DE_VIN_8: type=uint8
    IF_VIN_15
      data DE_VIN_15: type=uint8
    IF_VIN_17
      data DE_VIN_17: type=uint8
    IF_VIN_14
      data DE_VIN_14: type=uint8
    IF_VIN_9
      data DE_VIN_9: type=uint8
    IF_VIN_13
      data DE_VIN_13: type=uint8
    IF_VIN_10
      data DE_VIN_10: type=uint8
    IF_SG_WFS_02
      data DE_SG_WFS_02: type=AT_SG_WFS_02
    IF_VIN_11
      data DE_VIN_11: type=uint8
    IF_VIN_12
      data DE_VIN_12: type=uint8
    IF_VIN_16
      data DE_VIN_16: type=uint8
    IF_KL_Geblaese_Status
      data DE_KL_Geblaese_Status: type=uint8
    IF_UH_Jahr
      data DE_UH_Jahr: type=uint8
    IF_UH_Minute
      data DE_UH_Minute: type=uint8
    IF_UH_Monat
      data DE_UH_Monat: type=uint8
    IF_UH_Sekunde
      data DE_UH_Sekunde: type=uint8
    IF_UH_Stunde
      data DE_UH_Stunde: type=uint8
    IF_UH_Tag
      data DE_UH_Tag: type=uint8
    IF_RA_Frequency_unit
      data DE_RA_Frequency_unit: type=uint8
    IF_RA_Frequency
      data DE_RA_Frequency: type=uint16
    IF_MFL_Tastencode_1
      data DE_MFL_Tastencode_1: type=uint8
    IF_MFL_Eventcode_1
      data DE_MFL_Eventcode_1: type=uint8
    IF_MFL_Tastencode_2
      data DE_MFL_Tastencode_2: type=uint8
    IF_MFL_Eventcode_2
      data DE_MFL_Eventcode_2: type=uint8
    IF_MFL_Variante
      data DE_MFL_Variante: type=uint8
    IF_MFL_Marke
      data DE_MFL_Marke: type=uint8
    IF_SI_QRS_Mode
      data DE_SI_QRS_Mode: type=boolean
    IF_SI_T_Mode
      data DE_SI_T_Mode: type=boolean
    IF_SI_NWDF
      data DE_SI_NWDF: type=boolean
    IF_SI_NWDF_gueltig
      data DE_SI_NWDF_gueltig: type=boolean
    IF_HUD_KD_Fehler
      data DE_HUD_KD_Fehler: type=boolean
    IF_NM_Gateway_NM_State
      data DE_NM_Gateway_NM_State: type=uint8
    IF_NM_Info_El_NM_aktiv_Tmin
      data DE_NM_Info_El_NM_aktiv_Tmin: type=boolean
    IF_NM_Info_El_UDS_CC
      data DE_NM_Info_El_UDS_CC: type=boolean
    IF_NM_Info_El_NM_State
      data DE_NM_Info_El_NM_State: type=uint8
    IF_NM_Info_El_NM_aktiv_KL15
      data DE_NM_Info_El_NM_aktiv_KL15: type=boolean
    IF_Info_El_KD_Fehler
      data DE_Info_El_KD_Fehler: type=boolean
    IF_Gateway_Nachlauftyp
      data DE_Gateway_Nachlauftyp: type=uint8
    IF_Info_El_Nachlauftyp
      data DE_Info_El_Nachlauftyp: type=uint8
    IF_RA_AM_Tuning
      data DE_RA_AM_Tuning: type=boolean
    IF_SI_T_Schutz
      data DE_SI_T_Schutz: type=boolean
    IF_SI_Bus_Identifikation
      data DE_SI_Bus_Identifikation: type=uint8
    IF_NM_Info_El_CBV_CRI
      data DE_NM_Info_El_CBV_CRI: type=boolean
    IF_NM_HUD_NM_State
      data DE_NM_HUD_NM_State: type=uint8
    IF_NM_Info_El_CBV_AWB
      data DE_NM_Info_El_CBV_AWB: type=boolean
    IF_NM_HUD_CBV_AWB
      data DE_NM_HUD_CBV_AWB: type=boolean
    IF_NM_Gateway_CBV_AWB
      data DE_NM_Gateway_CBV_AWB: type=boolean
    IF_HUD_Nachlauftyp
      data DE_HUD_Nachlauftyp: type=uint8
    IF_FT_Tuer_Status
      data DE_FT_Tuer_Status: type=uint8
    IF_HBFS_Tuer_Status
      data DE_HBFS_Tuer_Status: type=uint8
    IF_BT_Tuer_Status
      data DE_BT_Tuer_Status: type=uint8
    IF_HFS_Tuer_Status
      data DE_HFS_Tuer_Status: type=uint8
    IF_KN_Info_El_BusKnockOutTimer
      data DE_KN_Info_El_BusKnockOutTimer: type=uint8
    IF_WLC1_Systemzustand
      data DE_WLC1_Systemzustand: type=boolean
    IF_WLC2_Systemzustand
      data DE_WLC2_Systemzustand: type=boolean
    IF_AMP_Nachlauftyp
      data DE_AMP_Nachlauftyp: type=uint8
    IF_AMP_KD_Fehler
      data DE_AMP_KD_Fehler: type=boolean
    IF_NM_LSR_1_CBV_AWB
      data DE_NM_LSR_1_CBV_AWB: type=boolean
    IF_NM_LSR_1_NM_State
      data DE_NM_LSR_1_NM_State: type=uint8
    IF_NM_WLC1_NM_State
      data DE_NM_WLC1_NM_State: type=uint8
    IF_NM_WLC1_CBV_AWB
      data DE_NM_WLC1_CBV_AWB: type=boolean
    IF_NM_WLC2_NM_State
      data DE_NM_WLC2_NM_State: type=uint8
    IF_NM_WLC2_CBV_AWB
      data DE_NM_WLC2_CBV_AWB: type=boolean
    IF_WLC1_Nachlauftyp
      data DE_WLC1_Nachlauftyp: type=uint8
    IF_WLC1_KD_Fehler
      data DE_WLC1_KD_Fehler: type=boolean
    IF_WLC2_Nachlauftyp
      data DE_WLC2_Nachlauftyp: type=uint8
    IF_WLC2_KD_Fehler
      data DE_WLC2_KD_Fehler: type=boolean
    IF_LSR_SystemMode
      data DE_LSR_SystemMode: type=boolean
    IF_MFL_Paddle_Verbau
      data DE_MFL_Paddle_Verbau: type=boolean
    IF_ORU_Status
      data DE_ORU_Status: type=uint8
    IF_SI_P_Mode_gueltig
      data DE_SI_P_Mode_gueltig: type=boolean
    IF_SI_P_Mode
      data DE_SI_P_Mode: type=boolean
    IF_NVEM_Abschaltstufe
      data DE_NVEM_Abschaltstufe: type=uint8
    IF_DispKBI_FS_Nachlauftyp
      data DE_DispKBI_FS_Nachlauftyp: type=uint8
    IF_DispKBI_FS_KD_Fehler
      data DE_DispKBI_FS_KD_Fehler: type=boolean
    IF_NM_DispKBI_FS_CBV_AWB
      data DE_NM_DispKBI_FS_CBV_AWB: type=boolean
    IF_NM_DispKBI_FS_NM_State
      data DE_NM_DispKBI_FS_NM_State: type=uint8
    IF_SOK_ungeschuetzte_Zeit
      data DE_SOK_ungeschuetzte_Zeit: type=uint64
    IF_ICAS3Sys01_KD_Fehler
      data DE_ICAS3Sys01_KD_Fehler: type=boolean
    IF_SI_NWDF_30
      data DE_SI_NWDF_30: type=boolean
    IF_NM_HUD_FCIB
      data DE_NM_HUD_FCIB: type=uint64
    IF_NM_HUD_FCAB
      data DE_NM_HUD_FCAB: type=uint64
    IF_SI_FCAB
      data DE_SI_FCAB: type=uint64
    IF_VDSO_Vx3d
      data DE_VDSO_Vx3d: type=uint16
    IF_SG_VDSO_05
      data DE_SG_VDSO_05: type=AT_SG_VDSO_05
    IF_NM_Info_El_FCIB
      data DE_NM_Info_El_FCIB: type=uint64
    IF_NM_Info_El_FCAB
      data DE_NM_Info_El_FCAB: type=uint64
    IF_NM_Info_El_NM_aktiv_Diag
      data DE_NM_Info_El_NM_aktiv_Diag: type=boolean
    IF_ZV_Heck_offen
      data DE_ZV_Heck_offen: type=boolean
    IF_NM_Gateway_FCAB
      data DE_NM_Gateway_FCAB: type=uint64
    IF_NM_Gateway_FCIB
      data DE_NM_Gateway_FCIB: type=uint64
    IF_NM_Info_El_NM_aktiv_CABaktiv
      data DE_NM_Info_El_NM_aktiv_CABaktiv: type=boolean
    IF_NM_DispKBI_FS_FCAB
      data DE_NM_DispKBI_FS_FCAB: type=uint64
    IF_NM_DispKBI_FS_FCIB
      data DE_NM_DispKBI_FS_FCIB: type=uint64
    IF_Info_El_SNI_10
      data DE_Info_El_SNI_10: type=uint16
    IF_HUD_SNI_10
      data DE_HUD_SNI_10: type=uint16
    IF_DispKBI_FS_SNI_10
      data DE_DispKBI_FS_SNI_10: type=uint16
    IF_KST_KL_15
      data DE_KST_KL_15: type=boolean
    IF_SG_ClampControl_01
      data DE_SG_ClampControl_01: type=AT_SG_ClampControl_01
    IF_KST_Kl_S
      data DE_KST_Kl_S: type=boolean
    IF_KST_Kl_50_Startanforderung
      data DE_KST_Kl_50_Startanforderung: type=boolean
    IF_KN_Info_El_ECUKnockOutTimer
      data DE_KN_Info_El_ECUKnockOutTimer: type=uint8
    IF_KN_Info_El_BusKnockOut
      data DE_KN_Info_El_BusKnockOut: type=uint8
    IF_KN_Info_El_ECUKnockOut
      data DE_KN_Info_El_ECUKnockOut: type=uint8
    IF_PTAcvSrv_StDrvMd
      data DE_PTAcvSrv_StDrvMd: type=uint8
    IF_PTAcvSrv_StPwrMd
      data DE_PTAcvSrv_StPwrMd: type=uint8
    IF_CID_VW_SL_App_SW_Version_Nr
      data DE_CID_VW_SL_App_SW_Version_Nr: type=uint32
    IF_CID_LVDS_Status
      data DE_CID_LVDS_Status: type=boolean
    IF_CID_VW_SL_Spare_Part_Nr_EndNr
      data DE_CID_VW_SL_Spare_Part_Nr_EndNr: type=uint32
    IF_CID_VW_SL_HW_Version_Nr
      data DE_CID_VW_SL_HW_Version_Nr: type=uint32
    IF_CID_VW_SL_Spare_Part_Nr_MittelNr
      data DE_CID_VW_SL_Spare_Part_Nr_MittelNr: type=uint32
    IF_CID_VW_SL_Spare_Part_Nr_TMA
      data DE_CID_VW_SL_Spare_Part_Nr_TMA: type=uint32
    IF_ZV_verriegelt_extern_ist_02
      data DE_ZV_verriegelt_extern_ist_02: type=uint8
    IF_CID_State
      data DE_CID_State: type=uint8
    IF_ZR_State_CID
      data DE_ZR_State_CID: type=uint8
    IF_CID_VW_SL_Spare_Part_Nr_Index
      data DE_CID_VW_SL_Spare_Part_Nr_Index: type=uint16
    IF_TNK_Tankinhalt_roh
      data DE_TNK_Tankinhalt_roh: type=uint16
    IF_TNK_FStatus_Tank
      data DE_TNK_FStatus_Tank: type=boolean
    IF_ClampControl_01_BZ
      data DE_ClampControl_01_BZ: type=uint8
    IF_ClampControl_01_CRC
      data DE_ClampControl_01_CRC: type=uint8
    IF_NM_CCF_FCIB
      data DE_NM_CCF_FCIB: type=uint64
    IF_NM_CCF_FCAB
      data DE_NM_CCF_FCAB: type=uint64
    IF_NM_CCF_CBV_AWB
      data DE_NM_CCF_CBV_AWB: type=boolean
    IF_NM_CCF_CBV_CRI
      data DE_NM_CCF_CBV_CRI: type=boolean
    IF_NM_CCF_NM_State
      data DE_NM_CCF_NM_State: type=uint8
    IF_NM_CID_FCAB
      data DE_NM_CID_FCAB: type=uint64
    IF_NM_CID_CBV_AWB
      data DE_NM_CID_CBV_AWB: type=boolean
    IF_NM_CID_FCIB
      data DE_NM_CID_FCIB: type=uint64
    IF_NM_CID_NM_State
      data DE_NM_CID_NM_State: type=uint8
    IF_NM_WLC2_FCAB
      data DE_NM_WLC2_FCAB: type=uint64
    IF_NM_WLC1_FCIB
      data DE_NM_WLC1_FCIB: type=uint64
    IF_NM_WLC1_FCAB
      data DE_NM_WLC1_FCAB: type=uint64
    IF_NM_WLC2_FCIB
      data DE_NM_WLC2_FCIB: type=uint64
    IF_NM_LSR_1_FCAB
      data DE_NM_LSR_1_FCAB: type=uint64
    IF_LSR_VW_SL_Spare_Part_Nr_MittelNr
      data DE_LSR_VW_SL_Spare_Part_Nr_MittelNr: type=uint32
    IF_LSR_VW_SL_HW_Version_Nr
      data DE_LSR_VW_SL_HW_Version_Nr: type=uint32
    IF_LSR_VW_SL_App_SW_Version_Nr
      data DE_LSR_VW_SL_App_SW_Version_Nr: type=uint32
    IF_LSR_VW_SL_Spare_Part_Nr_EndNr
      data DE_LSR_VW_SL_Spare_Part_Nr_EndNr: type=uint32
    IF_LSR_VW_SL_Spare_Part_Nr_TMA
      data DE_LSR_VW_SL_Spare_Part_Nr_TMA: type=uint32
    IF_LSR_VW_SL_Spare_Part_Nr_Index
      data DE_LSR_VW_SL_Spare_Part_Nr_Index: type=uint16
    IF_VDSO_DKmtg
      data DE_VDSO_DKmtg: type=uint32
    IF_VDSO_DKmtg_Auth
      data DE_VDSO_DKmtg_Auth: type=uint32
    IF_NM_AMP_FCIB
      data DE_NM_AMP_FCIB: type=uint64
    IF_DW_Kilometerstand
      data DE_DW_Kilometerstand: type=uint32
    IF_SOK_Zeit_Info_El_Zeit
      data DE_SOK_Zeit_Info_El_Zeit: type=uint64
    IF_SOK_Zeit_Info_El_Challenge
      data DE_SOK_Zeit_Info_El_Challenge: type=uint64
    IF_PID_KD_Fehler
      data DE_PID_KD_Fehler: type=boolean
    IF_TNK_Tankwarnung
      data DE_TNK_Tankwarnung: type=boolean
    IF_TNK_Tankwarnung_ungueltig
      data DE_TNK_Tankwarnung_ungueltig: type=boolean
    IF_TNK_Tankinhalt_hochaufl
      data DE_TNK_Tankinhalt_hochaufl: type=uint16
    IF_TNK_Max_Tankinhalt
      data DE_TNK_Max_Tankinhalt: type=uint8
    IF_TNK_Min_Tankinhalt
      data DE_TNK_Min_Tankinhalt: type=uint8
    IF_CID_KD_Fehler
      data DE_CID_KD_Fehler: type=boolean
    IF_DS_Info_El_StMemChanged
      data DE_DS_Info_El_StMemChanged: type=boolean
    IF_DS_Info_El_WIRChanged
      data DE_DS_Info_El_WIRChanged: type=boolean
    IF_DS_Info_El_IdentValid
      data DE_DS_Info_El_IdentValid: type=boolean
    IF_DS_Info_El_ConfDTCChanged
      data DE_DS_Info_El_ConfDTCChanged: type=boolean
    IF_DS_Info_El_MemSel10Changed
      data DE_DS_Info_El_MemSel10Changed: type=boolean
    IF_DS_Info_El_TestFailedChanged
      data DE_DS_Info_El_TestFailedChanged: type=boolean
    IF_DS_Info_El_DiagAdr
      data DE_DS_Info_El_DiagAdr: type=uint16
    IF_DS_Info_El_MemSelChanged
      data DE_DS_Info_El_MemSelChanged: type=boolean
    IF_TG_Geber_1_Stand
      data DE_TG_Geber_1_Stand: type=uint16
    IF_TG_QBit_Geber_2
      data DE_TG_QBit_Geber_2: type=boolean
    IF_TG_QBit_Geber_4
      data DE_TG_QBit_Geber_4: type=boolean
    IF_TG_Geber_4_Stand
      data DE_TG_Geber_4_Stand: type=uint16
    IF_TG_QBit_Geber_3
      data DE_TG_QBit_Geber_3: type=boolean
    IF_TG_Geber_2_Stand
      data DE_TG_Geber_2_Stand: type=uint16
    IF_TG_QBit_Geber_1
      data DE_TG_QBit_Geber_1: type=boolean
    IF_TG_Geber_3_Stand
      data DE_TG_Geber_3_Stand: type=uint16
    IF_CCF_KD_Fehler
      data DE_CCF_KD_Fehler: type=boolean
    IF_PID_VW_SL_Spare_Part_Nr_MittelNr
      data DE_PID_VW_SL_Spare_Part_Nr_MittelNr: type=uint32
    IF_PID_VW_SL_HW_Version_Nr
      data DE_PID_VW_SL_HW_Version_Nr: type=uint32
    IF_PID_EEPROM_Error
      data DE_PID_EEPROM_Error: type=boolean
    IF_PID_Touch_Errorstate
      data DE_PID_Touch_Errorstate: type=uint8
    IF_PID_VW_SL_Spare_Part_Nr_Index
      data DE_PID_VW_SL_Spare_Part_Nr_Index: type=uint16
    IF_PID_SW_inconsistent
      data DE_PID_SW_inconsistent: type=boolean
    IF_PID_Slider_Errorstate
      data DE_PID_Slider_Errorstate: type=uint8
    IF_PID_VW_SL_Spare_Part_Nr_EndNr
      data DE_PID_VW_SL_Spare_Part_Nr_EndNr: type=uint32
    IF_PID_VW_SL_App_SW_Version_Nr
      data DE_PID_VW_SL_App_SW_Version_Nr: type=uint32
    IF_PID_CL_30F
      data DE_PID_CL_30F: type=uint8
    IF_PID_Backlight_OpenCircuit
      data DE_PID_Backlight_OpenCircuit: type=boolean
    IF_PID_SystemMode
      data DE_PID_SystemMode: type=boolean
    IF_PID_Haptik_Errorstate
      data DE_PID_Haptik_Errorstate: type=uint8
    IF_PID_VW_SL_Spare_Part_Nr_TMA
      data DE_PID_VW_SL_Spare_Part_Nr_TMA: type=uint32
    IF_PID_FanSpeed
      data DE_PID_FanSpeed: type=uint8
    IF_PID_ShutterFoil_Errorstate
      data DE_PID_ShutterFoil_Errorstate: type=uint8
    IF_PID_State
      data DE_PID_State: type=uint8
    IF_PID_LVDS_State
      data DE_PID_LVDS_State: type=boolean
    IF_PID_Backlight_ShortCircuit
      data DE_PID_Backlight_ShortCircuit: type=boolean
    IF_PID_Temp_Error
      data DE_PID_Temp_Error: type=boolean
    IF_PID_CL30_Overvoltage_Error
      data DE_PID_CL30_Overvoltage_Error: type=boolean
    IF_PID_PCB_Temp_Error
      data DE_PID_PCB_Temp_Error: type=boolean
    IF_PID_OperatingTime_hr
      data DE_PID_OperatingTime_hr: type=uint16
    IF_PID_LVDS_Errorstate
      data DE_PID_LVDS_Errorstate: type=uint8
    IF_PID_CL30_Undervoltage_Error
      data DE_PID_CL30_Undervoltage_Error: type=boolean
    IF_PID_Proximity_Errorstate
      data DE_PID_Proximity_Errorstate: type=uint8
    IF_PID_LVDS_Splitter_Errorstate
      data DE_PID_LVDS_Splitter_Errorstate: type=uint8
    IF_PID_HDCP_Status
      data DE_PID_HDCP_Status: type=boolean
    IF_PID_Photosensor
      data DE_PID_Photosensor: type=uint16
    IF_ZR_State_PID
      data DE_ZR_State_PID: type=uint8
    IF_PID_TempSensorMax
      data DE_PID_TempSensorMax: type=uint8
    IF_PID_OperatingTime_min
      data DE_PID_OperatingTime_min: type=uint8
    IF_PID_PCB_TempSensor
      data DE_PID_PCB_TempSensor: type=uint8
    IF_PID_DispDerating
      data DE_PID_DispDerating: type=uint8
    IF_PID_PCB_TempSensorMax
      data DE_PID_PCB_TempSensorMax: type=uint8
    IF_PID_TempSensor
      data DE_PID_TempSensor: type=uint8
    IF_CID_DispDerating
      data DE_CID_DispDerating: type=uint8
    IF_CID_Backlight_ShortCircuit
      data DE_CID_Backlight_ShortCircuit: type=boolean
    IF_CID_TempSensorMax
      data DE_CID_TempSensorMax: type=uint8
    IF_CID_ShutterFoil_Errorstate
      data DE_CID_ShutterFoil_Errorstate: type=uint8
    IF_CID_EEPROM_Error
      data DE_CID_EEPROM_Error: type=boolean
    IF_CID_PCB_Temp_Error
      data DE_CID_PCB_Temp_Error: type=boolean
    IF_CID_CL30_Overvolt_Error
      data DE_CID_CL30_Overvolt_Error: type=boolean
    IF_CID_Temp_Error
      data DE_CID_Temp_Error: type=boolean
    IF_CID_Slider_Errorstate
      data DE_CID_Slider_Errorstate: type=uint8
    IF_CID_Proximity_Errorstate
      data DE_CID_Proximity_Errorstate: type=uint8
    IF_CID_OperatingTime_min
      data DE_CID_OperatingTime_min: type=uint8
    IF_CID_LVDS_Errorstate
      data DE_CID_LVDS_Errorstate: type=uint8
    IF_CID_Photosensor
      data DE_CID_Photosensor: type=uint16
    IF_CID_SW_inconsistent
      data DE_CID_SW_inconsistent: type=boolean
    IF_CID_TempSensor
      data DE_CID_TempSensor: type=uint8
    IF_CID_Haptik_Errorstate
      data DE_CID_Haptik_Errorstate: type=uint8
    IF_CID_FanSpeed
      data DE_CID_FanSpeed: type=uint8
    IF_CID_HDCP_Status
      data DE_CID_HDCP_Status: type=boolean
    IF_CID_SystemMode
      data DE_CID_SystemMode: type=boolean
    IF_CID_PCB_TempSensorMax
      data DE_CID_PCB_TempSensorMax: type=uint8
    IF_CID_LVDS_Splitter_Errorstate
      data DE_CID_LVDS_Splitter_Errorstate: type=uint8
    IF_CID_PCB_TempSensor
      data DE_CID_PCB_TempSensor: type=uint8
    IF_CID_Backlight_OpenCircuit
      data DE_CID_Backlight_OpenCircuit: type=boolean
    IF_CID_CL30_Undervolt_Error
      data DE_CID_CL30_Undervolt_Error: type=boolean
    IF_CID_CL_30F
      data DE_CID_CL_30F: type=uint8
    IF_CID_OperatingTime_hr
      data DE_CID_OperatingTime_hr: type=uint16
    IF_CID_Touch_Errorstate
      data DE_CID_Touch_Errorstate: type=uint8
    IF_ZR_IOC_Mode
      data DE_ZR_IOC_Mode: type=uint8
    IF_ZR_SYS1_Mode
      data DE_ZR_SYS1_Mode: type=uint8
    IF_ZR_HUD_Mode
      data DE_ZR_HUD_Mode: type=uint8
    IF_ZR_IVI1_Mode
      data DE_ZR_IVI1_Mode: type=uint8
    IF_ZR_CL_Mode
      data DE_ZR_CL_Mode: type=uint8
    IF_FID_PCB_Temp_Error
      data DE_FID_PCB_Temp_Error: type=boolean
    IF_FID_PCB_TempSensorMax
      data DE_FID_PCB_TempSensorMax: type=uint8
    IF_FID_TempSensorMax
      data DE_FID_TempSensorMax: type=uint8
    IF_FID_State
      data DE_FID_State: type=uint8
    IF_FID_DispDerating
      data DE_FID_DispDerating: type=uint8
    IF_FID_EEPROM_Error
      data DE_FID_EEPROM_Error: type=boolean
    IF_FID_CL30_Undervolt_Error
      data DE_FID_CL30_Undervolt_Error: type=boolean
    IF_FID_OperatingTime_min
      data DE_FID_OperatingTime_min: type=uint8
    IF_FID_CL_30F
      data DE_FID_CL_30F: type=uint8
    IF_FID_LVDS_State
      data DE_FID_LVDS_State: type=boolean
    IF_FID_OperatingTime_hr
      data DE_FID_OperatingTime_hr: type=uint16
    IF_FID_Temp_Error
      data DE_FID_Temp_Error: type=boolean
    IF_FID_TempSensor
      data DE_FID_TempSensor: type=uint8
    IF_FID_Photosensor
      data DE_FID_Photosensor: type=uint16
    IF_FID_PCB_TempSensor
      data DE_FID_PCB_TempSensor: type=uint8
    IF_FID_SystemMode
      data DE_FID_SystemMode: type=boolean
    IF_FID_Backlight_OpenCircuit
      data DE_FID_Backlight_OpenCircuit: type=boolean
    IF_FID_Backlight_ShortCircuit
      data DE_FID_Backlight_ShortCircuit: type=boolean
    IF_FID_CL30_Overvolt_Error
      data DE_FID_CL30_Overvolt_Error: type=boolean
    IF_ZR_State_FID
      data DE_ZR_State_FID: type=uint8
    IF_VDSO_Vx3dDisp
      data DE_VDSO_Vx3dDisp: type=uint16
    IF_TNK_Nachtanken_erkannt
      data DE_TNK_Nachtanken_erkannt: type=boolean
    IF_TNK_Kraftstoffvorrat
      data DE_TNK_Kraftstoffvorrat: type=uint16
    IF_NM_HUD_SNI_10
      data DE_NM_HUD_SNI_10: type=uint16
    IF_NM_CCF_SNI_10
      data DE_NM_CCF_SNI_10: type=uint16
    IF_NM_CID_SNI_10
      data DE_NM_CID_SNI_10: type=uint16
    IF_NM_Info_El_SNI_10
      data DE_NM_Info_El_SNI_10: type=uint16
    IF_NM_Gateway_SNI_10
      data DE_NM_Gateway_SNI_10: type=uint16
    IF_NM_DispKBI_FS_SNI_10
      data DE_NM_DispKBI_FS_SNI_10: type=uint16
    IF_NM_LSR_1_SNI_10
      data DE_NM_LSR_1_SNI_10: type=uint16
    IF_NM_PID_FCIB
      data DE_NM_PID_FCIB: type=uint64
    IF_NM_PID_FCAB
      data DE_NM_PID_FCAB: type=uint64
    IF_NM_PID_SNI_10
      data DE_NM_PID_SNI_10: type=uint16
    IF_NM_WLC2_SNI_10
      data DE_NM_WLC2_SNI_10: type=uint16
    IF_NM_PID_CBV_AWB
      data DE_NM_PID_CBV_AWB: type=boolean
    IF_NM_WLC1_SNI_10
      data DE_NM_WLC1_SNI_10: type=uint16
    IF_NM_PID_NM_State
      data DE_NM_PID_NM_State: type=uint8
    IF_TG_Geber_1_Mittelwert
      data DE_TG_Geber_1_Mittelwert: type=uint16
    IF_TG_Geber_2_Mittelwert
      data DE_TG_Geber_2_Mittelwert: type=uint16
    IF_TG_Geber_3_Mittelwert
      data DE_TG_Geber_3_Mittelwert: type=uint16
    IF_TG_Geber_4_Mittelwert
      data DE_TG_Geber_4_Mittelwert: type=uint16
    IF_KST_Ausstiegswunsch_Status
      data DE_KST_Ausstiegswunsch_Status: type=boolean
    IF_FID_SW_inconsistent
      data DE_FID_SW_inconsistent: type=boolean
    IF_FID_LVDS_Errorstate
      data DE_FID_LVDS_Errorstate: type=uint8
    IF_CID_Nachlauftyp
      data DE_CID_Nachlauftyp: type=uint8
    IF_PID_Nachlauftyp
      data DE_PID_Nachlauftyp: type=uint8
    IF_ICAS3Sys01_SNI_10
      data DE_ICAS3Sys01_SNI_10: type=uint16
    IF_TNK_Tankanzeigefreigabe
      data DE_TNK_Tankanzeigefreigabe: type=boolean
    IF_CE_VolCns
      data DE_CE_VolCns: type=uint16
    IF_CE_FlgOvf_VolCns
      data DE_CE_FlgOvf_VolCns: type=boolean
    IF_KST_ComfortReadyStatus
      data DE_KST_ComfortReadyStatus: type=boolean
    IF_VDSO_05_BZ
      data DE_VDSO_05_BZ: type=uint8
    IF_VDSO_05_CRC
      data DE_VDSO_05_CRC: type=uint8
    IF_CID_SNI_10
      data DE_CID_SNI_10: type=uint16
    IF_MM_PropulsionSystemActive
      data DE_MM_PropulsionSystemActive: type=boolean
    IF_FID_VA_Response
      data DE_FID_VA_Response: type=FID_VA_Response
    IF_FID_VA_Communication_Init_Ack
      data DE_FID_VA_Communication_Init_Ack: type=FID_VA_Communication_Init_Ack
    IF_LSR_EEPROM_Error_TNCTOC
      data DE_LSR_EEPROM_Error_TNCTOC: type=boolean
    IF_LSR_SW_inconsistent_TF
      data DE_LSR_SW_inconsistent_TF: type=boolean
    IF_LSR_EEPROM_Error_TF
      data DE_LSR_EEPROM_Error_TF: type=boolean
    IF_LSR_dimming_post_carriage
      data DE_LSR_dimming_post_carriage: type=boolean
    IF_LSR_dimming_PWM
      data DE_LSR_dimming_PWM: type=uint8
    IF_LSR_CL30_Overvolt_Error
      data DE_LSR_CL30_Overvolt_Error: type=boolean
    IF_LSR_SW_inconsistent_TNCTOC
      data DE_LSR_SW_inconsistent_TNCTOC: type=boolean
    IF_LSR_CL30_Undervoltage_Error
      data DE_LSR_CL30_Undervoltage_Error: type=boolean
    IF_DTSO_StPrpUnitAcvWhl
      data DE_DTSO_StPrpUnitAcvWhl: type=uint8
    IF_PID_VA_Response
      data DE_PID_VA_Response: type=PID_VA_Response
    IF_PID_VA_Communication_Init_Ack
      data DE_PID_VA_Communication_Init_Ack: type=PID_VA_Communication_Init_Ack
    IF_ZR_VA_Challenge_PID
      data DE_ZR_VA_Challenge_PID: type=ZR_VA_Challenge_PID
    IF_ZR_VA_Communication_Init_FID
      data DE_ZR_VA_Communication_Init_FID: type=ZR_VA_Communication_Init_FID
    IF_ZR_VA_Challenge_FID
      data DE_ZR_VA_Challenge_FID: type=ZR_VA_Challenge_FID
    IF_ZR_VA_Challenge_CID
      data DE_ZR_VA_Challenge_CID: type=ZR_VA_Challenge_CID
    IF_ZR_VA_Communication_Init_CID
      data DE_ZR_VA_Communication_Init_CID: type=ZR_VA_Communication_Init_CID
    IF_ZR_VA_Communication_Init_PID
      data DE_ZR_VA_Communication_Init_PID: type=ZR_VA_Communication_Init_PID
    IF_CID_VA_Response
      data DE_CID_VA_Response: type=CID_VA_Response
    IF_CID_VA_Communication_Init_Ack
      data DE_CID_VA_Communication_Init_Ack: type=CID_VA_Communication_Init_Ack
    IF_DTSO_StPTEgySrc
      data DE_DTSO_StPTEgySrc: type=uint8
    IF_NM_aktiv_Internetverbindung
      data DE_NM_aktiv_Internetverbindung: type=boolean
    IF_NM_aktiv_Tankinhalt_ermitteln
      data DE_NM_aktiv_Tankinhalt_ermitteln: type=boolean
    IF_AMP_SNI_10
      data DE_AMP_SNI_10: type=uint16
    IF_HWP_01_BZ
      data DE_HWP_01_BZ: type=uint8
    IF_SG_HWP_01
      data DE_SG_HWP_01: type=AT_SG_HWP_01
    IF_HWP_01_CRC
      data DE_HWP_01_CRC: type=uint8
    IF_HWP_HMI_ASIL_Color
      data DE_HWP_HMI_ASIL_Color: type=uint8
    IF_HWP_HMI_State
      data DE_HWP_HMI_State: type=uint8
    IF_IP_TS_CTO_01_Data
      data DE_IP_TS_CTO_01_Data: type=IP_TS_CTO_01_Data
    IF_IP_TS_DTO_01_Data
      data DE_IP_TS_DTO_01_Data: type=IP_TS_DTO_01_Data
    IF_IP_TS_DTO_04_Data
      data DE_IP_TS_DTO_04_Data: type=IP_TS_DTO_04_Data
    IF_IP_TS_DTO_02_Data
      data DE_IP_TS_DTO_02_Data: type=IP_TS_DTO_02_Data
    IF_IP_TS_DTO_03_Data
      data DE_IP_TS_DTO_03_Data: type=IP_TS_DTO_03_Data
    IF_TCPServer_IP_TS_DTO_01_Data
      data DE_TCPServer_IP_TS_DTO_01_Data: type=TCPServer_IP_TS_DTO_01_Data
    IF_TCPServer_IP_TS_DTO_03_Data
      data DE_TCPServer_IP_TS_DTO_03_Data: type=TCPServer_IP_TS_DTO_03_Data
    IF_TCPServer_IP_TS_DTO_04_Data
      data DE_TCPServer_IP_TS_DTO_04_Data: type=TCPServer_IP_TS_DTO_04_Data
    IF_TCPServer_IP_TS_DTO_02_Data
      data DE_TCPServer_IP_TS_DTO_02_Data: type=TCPServer_IP_TS_DTO_02_Data
    IF_WLC1_ChargingStatus
      data DE_WLC1_ChargingStatus: type=uint8
    IF_WLC1_UsedChargingStandard
      data DE_WLC1_UsedChargingStandard: type=uint8
    IF_WLC2_ChargingEfficiency
      data DE_WLC2_ChargingEfficiency: type=uint8
    IF_WLC2_ChargingStatus
      data DE_WLC2_ChargingStatus: type=uint8
    IF_WLC1_ChargingEfficiency
      data DE_WLC1_ChargingEfficiency: type=uint8
    IF_WLC2_UsedChargingStandard
      data DE_WLC2_UsedChargingStandard: type=uint8
    IF_NM_Info_El_Wakeup_V12
      data DE_NM_Info_El_Wakeup_V12: type=uint8
    IF_FoD_Info_El_Resp_Eth_Data
      data DE_FoD_Info_El_Resp_Eth_Data: sw-impl-policy=QUEUED, type=FoD_Info_El_Resp_Eth_Data
    IF_FoD_Info_El_Req_Eth_Data
      data DE_FoD_Info_El_Req_Eth_Data: sw-impl-policy=QUEUED, type=FoD_Info_El_Req_Eth_Data
    IF_SOK_FoD_Info_El_Req_Eth_Challeng
      data DE_SOK_FoD_Info_El_Req_Eth_Challeng: type=uint64
    IF_SOK_FoD_Info_El_Resp_Eth_Challen
      data DE_SOK_FoD_Info_El_Resp_Eth_Challen: type=uint64
    IF_KN_AMP_DiagPfad_V12
      data DE_KN_AMP_DiagPfad_V12: type=boolean
    IF_KN_DispKBI_FS_DiagPfad_V12
      data DE_KN_DispKBI_FS_DiagPfad_V12: type=boolean
    IF_KN_HUD_DiagPfad_V12
      data DE_KN_HUD_DiagPfad_V12: type=boolean
    IF_KN_CID_DiagPfad_V12
      data DE_KN_CID_DiagPfad_V12: type=boolean
    IF_KN_PID_DiagPfad_V12
      data DE_KN_PID_DiagPfad_V12: type=boolean
    IF_KN_WLC1_DiagPfad_V12
      data DE_KN_WLC1_DiagPfad_V12: type=boolean
    IF_KN_HCP3Sys03_DiagPfad_V12
      data DE_KN_HCP3Sys03_DiagPfad_V12: type=boolean
    IF_KN_WLC2_DiagPfad_V12
      data DE_KN_WLC2_DiagPfad_V12: type=boolean
    IF_KN_CCF_DiagPfad_V12
      data DE_KN_CCF_DiagPfad_V12: type=boolean
    IF_KN_ICAS3Sys01_DiagPfad_V12
      data DE_KN_ICAS3Sys01_DiagPfad_V12: type=boolean
    IF_KN_Info_El_DiagPfad_V12
      data DE_KN_Info_El_DiagPfad_V12: type=boolean
    IF_HCP3Sys03_SNI_10
      data DE_HCP3Sys03_SNI_10: type=uint16
    IF_WLC1_SNI_10
      data DE_WLC1_SNI_10: type=uint16
    IF_WLC2_SNI_10
      data DE_WLC2_SNI_10: type=uint16
    IF_PID_SNI_10
      data DE_PID_SNI_10: type=uint16
    IF_CCF_SNI_10
      data DE_CCF_SNI_10: type=uint16
    IF_FID_VA_Communication_Init
      data DE_FID_VA_Communication_Init: type=FID_VA_Communication_Init
    IF_ZR_VA_Communication_Init_Ack_FID
      data DE_ZR_VA_Communication_Init_Ack_FID: type=ZR_VA_Communication_Init_Ack_FID
    IF_OruVehicleLockRequestA
      data DE_OruVehicleLockRequestA: type=uint8
    IF_ORU_Control_A_01_CRC
      data DE_ORU_Control_A_01_CRC: type=uint8
    IF_ORU_Control_A_01_BZ
      data DE_ORU_Control_A_01_BZ: type=uint8
    IF_SG_ORU_Control_A_01
      data DE_SG_ORU_Control_A_01: type=AT_SG_ORU_Control_A_01
    IF_CID_Touchstate
      data DE_CID_Touchstate: type=boolean
    IF_PID_VA_Communication_Init
      data DE_PID_VA_Communication_Init: type=PID_VA_Communication_Init
    IF_ZR_VA_Communication_Init_Ack_CID
      data DE_ZR_VA_Communication_Init_Ack_CID: type=ZR_VA_Communication_Init_Ack_CID
    IF_ZR_VA_Communication_Init_Ack_PID
      data DE_ZR_VA_Communication_Init_Ack_PID: type=ZR_VA_Communication_Init_Ack_PID
    IF_CID_VA_Communication_Init
      data DE_CID_VA_Communication_Init: type=CID_VA_Communication_Init
    IF_ZV_Tasten_HMI_Anf
      data DE_ZV_Tasten_HMI_Anf: type=boolean
    IF_PID_Touchstate
      data DE_PID_Touchstate: type=boolean
    IF_HCP3Sys03_KD_Fehler
      data DE_HCP3Sys03_KD_Fehler: type=boolean
    IF_NM_aktiv_GoodbyeScreen
      data DE_NM_aktiv_GoodbyeScreen: type=boolean
    IF_ACA_HMI_Color
      data DE_ACA_HMI_Color: type=uint8
    IF_OnlineRemoteUpdateControlA
      data DE_OnlineRemoteUpdateControlA: type=uint8
    IF_OnlineRemoteUpdateControlOldA
      data DE_OnlineRemoteUpdateControlOldA: type=uint8
    IF_OnlineRemoteUpdateControlOldD
      data DE_OnlineRemoteUpdateControlOldD: type=uint8
    IF_OnlineRemoteUpdateControlD
      data DE_OnlineRemoteUpdateControlD: type=uint8
    IF_TNK_Wegstrecke_Hinweis
      data DE_TNK_Wegstrecke_Hinweis: type=boolean
    IF_VehicleProtectedEnvironment_D
      data DE_VehicleProtectedEnvironment_D: type=uint8
    IF_ORU_Control_D_01_BZ
      data DE_ORU_Control_D_01_BZ: type=uint8
    IF_SG_ORU_Control_D_01
      data DE_SG_ORU_Control_D_01: type=AT_SG_ORU_Control_D_01
    IF_ORU_Control_D_01_CRC
      data DE_ORU_Control_D_01_CRC: type=uint8
    IF_OTAMC_D_01_CRC
      data DE_OTAMC_D_01_CRC: type=uint8
    IF_OTAMC_D_01_BZ
      data DE_OTAMC_D_01_BZ: type=uint8
    IF_SG_OTAMC_D_01
      data DE_SG_OTAMC_D_01: type=AT_SG_OTAMC_D_01
    IF_CID_HID_FetchAll
      data DE_CID_HID_FetchAll: type=boolean
    IF_DS_Info_El_Lokalaktiv
      data DE_DS_Info_El_Lokalaktiv: type=boolean
    IF_NM_aktiv_SysPartition_3
      data DE_NM_aktiv_SysPartition_3: type=boolean
    IF_NM_aktiv_SysPartition_2
      data DE_NM_aktiv_SysPartition_2: type=boolean
    IF_NM_aktiv_IVIPartition_1
      data DE_NM_aktiv_IVIPartition_1: type=boolean
    IF_NM_aktiv_IVIPartition_3
      data DE_NM_aktiv_IVIPartition_3: type=boolean
    IF_NM_aktiv_IVIPartition_2
      data DE_NM_aktiv_IVIPartition_2: type=boolean
    IF_NM_aktiv_SysPartition_1
      data DE_NM_aktiv_SysPartition_1: type=boolean
    IF_NM_aktiv_Innenraumerlebnis
      data DE_NM_aktiv_Innenraumerlebnis: type=boolean
    IF_NM_aktiv_SOK_Master_Anf_Info_El
      data DE_NM_aktiv_SOK_Master_Anf_Info_El: type=boolean
    IF_NM_aktiv_User_Anmeldung
      data DE_NM_aktiv_User_Anmeldung: type=boolean
    IF_NM_aktiv_BAP_Kommunikation_SYS
      data DE_NM_aktiv_BAP_Kommunikation_SYS: type=boolean
  5 x client server interface:
    WakeupclusterConfigurationMethods
      7 x operation:
        subscribeConfigurationsByKey
          arg key: type=AT_vnsmInstancesApp, direction=IN
          arg initialEventRequired: type=booleanApp, direction=IN
          arg result: type=AT_WakeupclusterConfigurationSubscriptionResponseApp, direction=OUT
        setConfigurationsElement
          arg key: type=AT_vnsmInstancesApp, direction=IN
          arg element: type=AT_ConfigurationsSetApp, direction=IN
          arg status: type=AT_OperationStatusApp, direction=OUT
        getConfigurationsElementByKey
          arg key: type=AT_vnsmInstancesApp, direction=IN
          arg result: type=AT_configurationsResponseSingleApp, direction=OUT
        subscribeConfigurations
          arg initialEventRequired: type=booleanApp, direction=IN
          arg result: type=AT_WakeupclusterConfigurationSubscriptionResponseApp, direction=OUT
        getConfigurationsElements
          arg result: type=AT_ConfigurationsResponseApp, direction=OUT
        unsubscribeConfigurations
          arg subscriptionId: type=unsubscribeConfigurations_subscriptionId_typeApp, direction=IN
          arg status: type=AT_SubscriptionStatusApp, direction=OUT
        createConfigurationsElement
          arg element: type=AT_ConfigurationsCreateApp, direction=IN
          arg result: type=AT_ConfigurationsCreateResponseApp, direction=OUT
    WakeUpMonitorDataMethods
      operation startCycle
        arg cycleCounterRequested: type=startCycle_cycleCounterRequested_typeApp, direction=IN
        arg cycleCounterAcknowledgement: type=startCycle_cycleCounterAcknowledgement_typeApp, direction=OUT
      operation getTable
        7 x arg:
          cycleCounterRequested: type=getTable_cycleCounterRequested_typeApp, direction=IN
          cycleCounterAcknowledgement: type=getTable_cycleCounterAcknowledgement_typeApp, direction=OUT
          busActiveTimes: type=getTable_busActiveTimesApp, direction=OUT
          networkManagementActiveTimes: type=getTable_networkManagementActiveTimesApp, direction=OUT
          hostCommunicationActiveTimes: type=getTable_hostCommunicationActiveTimesApp, direction=OUT
          hostLocalActiveTimes: type=getTable_hostLocalActiveTimesApp, direction=OUT
          systemfunctionActiveTimes: type=getTable_systemfunctionActiveTimesApp, direction=OUT
    SOMEIPTestabilityClientMethods
      7 x operation:
        echoFloat32
          arg inFloat32: type=echoFloat32_inFloat32_typeApp, direction=IN
          arg outFloat32: type=echoFloat32_outFloat32_typeApp, direction=OUT
        echoUInt8UInt16UInt32
          6 x arg:
            inUInt8: type=echoUInt8UInt16UInt32_inUInt8_typeApp, direction=IN
            inUInt16: type=echoUInt8UInt16UInt32_inUInt16_typeApp, direction=IN
            inUInt32: type=echoUInt8UInt16UInt32_inUInt32_typeApp, direction=IN
            outUInt8: type=echoUInt8UInt16UInt32_outUInt8_typeApp, direction=OUT
            outUInt16: type=echoUInt8UInt16UInt32_outUInt16_typeApp, direction=OUT
            outUInt32: type=echoUInt8UInt16UInt32_outUInt32_typeApp, direction=OUT
        echoComplexStruct
          arg inStruct: type=AT_TestComplexStructApp, direction=IN
          arg outStruct: type=AT_TestComplexStructApp, direction=OUT
        echoUInt8
          arg inUInt8: type=echoUInt8_inUInt8_typeApp, direction=IN
          arg outUInt8: type=echoUInt8_outUInt8_typeApp, direction=OUT
        echoComplexDynamicArray
          arg inArray: type=echoComplexDynamicArray_inArrayApp, direction=IN
          arg outArray: type=echoComplexDynamicArray_outArrayApp, direction=OUT
        getTestFieldUInt8
          arg data: type=TestFieldUInt8_typeApp, direction=OUT
        setTestFieldUInt8
          arg data: type=TestFieldUInt8_typeApp, direction=IN
          arg returnData: type=TestFieldUInt8_typeApp, direction=OUT
    SOMEIPTestabilityReliableMethods
      33 x operation:
        echoUInt8UInt16UInt32
          6 x arg:
            inUInt8: type=SOMEIPTestabilityReliable_echoUInt8UInt16UInt32_inUInt8_typeApp, direction=IN
            inUInt16: type=SOMEIPTestabilityReliable_echoUInt8UInt16UInt32_inUInt16_typeApp, direction=IN
            inUInt32: type=SOMEIPTestabilityReliable_echoUInt8UInt16UInt32_inUInt32_typeApp, direction=IN
            outUInt8: type=SOMEIPTestabilityReliable_echoUInt8UInt16UInt32_outUInt8_typeApp, direction=OUT
            outUInt16: type=SOMEIPTestabilityReliable_echoUInt8UInt16UInt32_outUInt16_typeApp, direction=OUT
            outUInt32: type=SOMEIPTestabilityReliable_echoUInt8UInt16UInt32_outUInt32_typeApp, direction=OUT
        echoUInt8
          arg inUInt8: type=SOMEIPTestabilityReliable_echoUInt8_inUInt8_typeApp, direction=IN
          arg outUInt8: type=SOMEIPTestabilityReliable_echoUInt8_outUInt8_typeApp, direction=OUT
        echoBool
          arg inBool: type=booleanApp, direction=IN
          arg outBool: type=booleanApp, direction=OUT
        getLastValueFieldMulticast
          arg client: type=AT_EnumTsClientTypeApp, direction=IN
          arg lastValue: type=getLastValueFieldMulticast_lastValue_typeApp, direction=OUT
        echoInverseDynamicArray
          arg inArray: type=echoInverseDynamicArray_inArrayApp, direction=IN
          arg outArray: type=echoInverseDynamicArray_outArrayApp, direction=OUT
        getLastValueEventUInt8
          arg outEventValue: type=getLastValueEventUInt8_outEventValue_typeApp, direction=OUT
          arg client: type=AT_EnumTsClientTypeApp, direction=OUT
        echoUInt64
          arg inUInt64: type=echoUInt64_inUInt64_typeApp, direction=IN
          arg outUInt64: type=echoUInt64_outUInt64_typeApp, direction=OUT
        echoUInt32
          arg inUInt32: type=echoUInt32_inUInt32_typeApp, direction=IN
          arg outUInt32: type=echoUInt32_outUInt32_typeApp, direction=OUT
        echoComplexStruct
          arg inStruct: type=SOMEIPTestabilityReliable_AT_TestComplexStructApp, direction=IN
          arg outStruct: type=SOMEIPTestabilityReliable_AT_TestComplexStructApp, direction=OUT
        checkByteOrder
          5 x arg:
            operationType: type=AT_EnumOperationTypeApp, direction=IN
            inUInt32: type=checkByteOrder_inUInt32_typeApp, direction=IN
            inUInt16: type=checkByteOrder_inUInt16_typeApp, direction=IN
            outUInt16: type=checkByteOrder_outUInt16_typeApp, direction=OUT
            outUInt32: type=checkByteOrder_outUInt32_typeApp, direction=OUT
        getSupportedFunctions
          arg ids: type=getSupportedFunctions_idsApp, direction=OUT
        echoInverseDynamicMultidimensionalArray
          arg inArray: type=echoInverseDynamicMultidimensionalArray_inArrayApp, direction=IN
          arg outArray: type=echoInverseDynamicMultidimensionalArray_outArrayApp, direction=OUT
        echoFloat32
          arg inFloat32: type=SOMEIPTestabilityReliable_echoFloat32_inFloat32_typeApp, direction=IN
          arg outFloat32: type=SOMEIPTestabilityReliable_echoFloat32_outFloat32_typeApp, direction=OUT
        echoComplexDynamicArray
          arg inArray: type=SOMEIPTestabilityReliable_echoComplexDynamicArray_inArrayApp, direction=IN
          arg outArray: type=SOMEIPTestabilityReliable_echoComplexDynamicArray_outArrayApp, direction=OUT
        activateTsClient: possible-error=ActivateTsClientClientInterfaceActivationFailed
          arg startDelay: type=activateTsClient_startDelay_typeApp, direction=IN
          arg client: type=AT_EnumTsClientTypeApp, direction=IN
        enableSubscription: possible-error=EnableSubscriptionClientInterfaceSubscriptionFailed
          arg eventGroupId: type=enableSubscription_eventGroupId_typeApp, direction=IN
          arg client: type=AT_EnumTsClientTypeApp, direction=IN
        echoStructInStruct
          arg inStruct: type=AT_TestStructInStructApp, direction=IN
          arg outStruct: type=AT_TestStructInStructApp, direction=OUT
        echoFloat64
          arg inFloat64: type=echoFloat64_inFloat64_typeApp, direction=IN
          arg outFloat64: type=echoFloat64_outFloat64_typeApp, direction=OUT
        resetInterface: possible-error=ResetInterfaceResetInterfaceFailed
          arg delay: type=resetInterface_delay_typeApp, direction=IN
        echoInverseBitField
          4 x arg:
            inBitfield1: type=echoInverseBitField_inBitfield1_typeApp, direction=IN
            inBitfield2: type=echoInverseBitField_inBitfield2_typeApp, direction=IN
            outBitfield1: type=echoInverseBitField_outBitfield1_typeApp, direction=OUT
            outBitfield2: type=echoInverseBitField_outBitfield2_typeApp, direction=OUT
        echoUInt16
          arg inUInt16: type=echoUInt16_inUInt16_typeApp, direction=IN
          arg outUInt16: type=echoUInt16_outUInt16_typeApp, direction=OUT
        echoSInt32
          arg inSInt32: type=echoSInt32_inSInt32_typeApp, direction=IN
          arg outSInt32: type=echoSInt32_outSInt32_typeApp, direction=OUT
        echoInverseStruct
          arg inStruct: type=SOMEIPTestabilityReliable_AT_TestStructApp, direction=IN
          arg outStruct: type=SOMEIPTestabilityReliable_AT_TestStructApp, direction=OUT
        echoSInt64
          arg inSInt64: type=echoSInt64_inSInt64_typeApp, direction=IN
          arg outSInt64: type=echoSInt64_outSInt64_typeApp, direction=OUT
        echoSInt16
          arg inSInt16: type=echoSInt16_inSInt16_typeApp, direction=IN
          arg outSInt16: type=echoSInt16_outSInt16_typeApp, direction=OUT
        echoUTF8String
          arg inString: type=echoUTF8String_inString_typeApp, direction=IN
          arg outString: type=echoUTF8String_outString_typeApp, direction=OUT
        deactivateTsClient: possible-error=DeactivateTsClientClientInterfaceDeactivationFailed
          arg delay: type=deactivateTsClient_delay_typeApp, direction=IN
          arg client: type=AT_EnumTsClientTypeApp, direction=IN
        echoSInt8
          arg inSInt8: type=echoSInt8_inSInt8_typeApp, direction=IN
          arg outSInt8: type=echoSInt8_outSInt8_typeApp, direction=OUT
        getTestFieldComplexStruct
          arg data: type=SOMEIPTestabilityReliable_AT_TestComplexStructApp, direction=OUT
        setTestFieldComplexStruct
          arg data: type=SOMEIPTestabilityReliable_AT_TestComplexStructApp, direction=IN
          arg returnData: type=SOMEIPTestabilityReliable_AT_TestComplexStructApp, direction=OUT
        getTestFieldUInt64
          arg data: type=TestFieldUInt64_typeApp, direction=OUT
        getTestFieldUInt8
          arg data: type=SOMEIPTestabilityReliable_TestFieldUInt8_typeApp, direction=OUT
        setTestFieldUInt8
          arg data: type=SOMEIPTestabilityReliable_TestFieldUInt8_typeApp, direction=IN
          arg returnData: type=SOMEIPTestabilityReliable_TestFieldUInt8_typeApp, direction=OUT
      4 x error:
        ActivateTsClientClientInterfaceActivationFailed: error-code=33
        DeactivateTsClientClientInterfaceDeactivationFailed: error-code=34
        EnableSubscriptionClientInterfaceSubscriptionFailed: error-code=32
        ResetInterfaceResetInterfaceFailed: error-code=35
    IdsCanSensorMethods
      4 x operation:
        undefineCanSensorFeaturesElement0
          arg element: type=AT_CanSensorFeaturesUndefineApp, direction=IN
          arg status: type=IdsCanSensor_AT_OperationStatusApp, direction=OUT
        setCanSensorFeaturesElement0
          arg element: type=AT_CanSensorFeaturesSetApp, direction=IN
          arg status: type=IdsCanSensor_AT_OperationStatusApp, direction=OUT
        getcanSensorFeaturesElement0
          arg data: type=AT_CanSensorFeaturesTypeApp, direction=OUT
        getperiodicSignalElement0
          arg data: type=AT_PeriodicSignalTypeApp, direction=OUT
package /Interfaces/Types
  39 x impl type, all with category=ARRAY:
    CID_VA_Communication_Init
      element CID_VA_Communication_InitBase: array-size=17, array-size-semantics=FIXED-SIZE, implementation-data-type=uint8
      symbol props SymbolProps: symbol=CID_VA_Communication_Init
    CID_VA_Communication_Init_Ack
      element CID_VA_Communication_Init_AckBase: array-size=17, array-size-semantics=FIXED-SIZE, implementation-data-type=uint8
      symbol props SymbolProps: symbol=CID_VA_Communication_Init_Ack
    CID_VA_Response
      element CID_VA_ResponseBase: array-size=64, array-size-semantics=FIXED-SIZE, implementation-data-type=uint8
      symbol props SymbolProps: symbol=CID_VA_Response
    FBS_MKGO_01
      element FBS_MKGO_01Base: array-size=64, array-size-semantics=FIXED-SIZE, implementation-data-type=uint8
      symbol props SymbolProps: symbol=FBS_MKGO_01
    FBS_MKGO_02
      element FBS_MKGO_02Base: array-size=64, array-size-semantics=FIXED-SIZE, implementation-data-type=uint8
      symbol props SymbolProps: symbol=FBS_MKGO_02
    FBS_MKGO_03
      element FBS_MKGO_03Base: array-size=64, array-size-semantics=FIXED-SIZE, implementation-data-type=uint8
      symbol props SymbolProps: symbol=FBS_MKGO_03
    FBS_MKGO_04
      element FBS_MKGO_04Base: array-size=64, array-size-semantics=FIXED-SIZE, implementation-data-type=uint8
      symbol props SymbolProps: symbol=FBS_MKGO_04
    FBS_MKGO_05
      element FBS_MKGO_05Base: array-size=64, array-size-semantics=FIXED-SIZE, implementation-data-type=uint8
      symbol props SymbolProps: symbol=FBS_MKGO_05
    FID_VA_Communication_Init
      element FID_VA_Communication_InitBase: array-size=17, array-size-semantics=FIXED-SIZE, implementation-data-type=uint8
      symbol props SymbolProps: symbol=FID_VA_Communication_Init
    FID_VA_Communication_Init_Ack
      element FID_VA_Communication_Init_AckBase: array-size=17, array-size-semantics=FIXED-SIZE, implementation-data-type=uint8
      symbol props SymbolProps: symbol=FID_VA_Communication_Init_Ack
    FID_VA_Response
      element FID_VA_ResponseBase: array-size=64, array-size-semantics=FIXED-SIZE, implementation-data-type=uint8
      symbol props SymbolProps: symbol=FID_VA_Response
    FoD_Info_El_Req_Eth_Data
      element FoD_Info_El_Req_Eth_DataBase: array-size=402, array-size-semantics=VARIABLE-SIZE, implementation-data-type=uint8
      symbol props SymbolProps: symbol=FoD_Info_El_Req_Eth_Data
    FoD_Info_El_Resp_Eth_Data
      element FoD_Info_El_Resp_Eth_DataBase: array-size=502, array-size-semantics=VARIABLE-SIZE, implementation-data-type=uint8
      symbol props SymbolProps: symbol=FoD_Info_El_Resp_Eth_Data
    IP_TS_CTO_01_Data
      element IP_TS_CTO_01_DataBase: array-size=1452, array-size-semantics=FIXED-SIZE, implementation-data-type=uint8
      symbol props SymbolProps: symbol=IP_TS_CTO_01_Data
    IP_TS_DTO_01_Data
      element IP_TS_DTO_01_DataBase: array-size=1452, array-size-semantics=FIXED-SIZE, implementation-data-type=uint8
      symbol props SymbolProps: symbol=IP_TS_DTO_01_Data
    IP_TS_DTO_02_Data
      element IP_TS_DTO_02_DataBase: array-size=1452, array-size-semantics=FIXED-SIZE, implementation-data-type=uint8
      symbol props SymbolProps: symbol=IP_TS_DTO_02_Data
    IP_TS_DTO_03_Data
      element IP_TS_DTO_03_DataBase: array-size=1452, array-size-semantics=FIXED-SIZE, implementation-data-type=uint8
      symbol props SymbolProps: symbol=IP_TS_DTO_03_Data
    IP_TS_DTO_04_Data
      element IP_TS_DTO_04_DataBase: array-size=1452, array-size-semantics=FIXED-SIZE, implementation-data-type=uint8
      symbol props SymbolProps: symbol=IP_TS_DTO_04_Data
    MKGO_FBS_01
      element MKGO_FBS_01Base: array-size=64, array-size-semantics=FIXED-SIZE, implementation-data-type=uint8
      symbol props SymbolProps: symbol=MKGO_FBS_01
    MKGO_FBS_02
      element MKGO_FBS_02Base: array-size=64, array-size-semantics=FIXED-SIZE, implementation-data-type=uint8
      symbol props SymbolProps: symbol=MKGO_FBS_02
    MKGO_FBS_03
      element MKGO_FBS_03Base: array-size=64, array-size-semantics=FIXED-SIZE, implementation-data-type=uint8
      symbol props SymbolProps: symbol=MKGO_FBS_03
    MKGO_FBS_04
      element MKGO_FBS_04Base: array-size=64, array-size-semantics=FIXED-SIZE, implementation-data-type=uint8
      symbol props SymbolProps: symbol=MKGO_FBS_04
    MKGO_FBS_05
      element MKGO_FBS_05Base: array-size=64, array-size-semantics=FIXED-SIZE, implementation-data-type=uint8
      symbol props SymbolProps: symbol=MKGO_FBS_05
    PID_VA_Communication_Init
      element PID_VA_Communication_InitBase: array-size=17, array-size-semantics=FIXED-SIZE, implementation-data-type=uint8
      symbol props SymbolProps: symbol=PID_VA_Communication_Init
    PID_VA_Communication_Init_Ack
      element PID_VA_Communication_Init_AckBase: array-size=17, array-size-semantics=FIXED-SIZE, implementation-data-type=uint8
      symbol props SymbolProps: symbol=PID_VA_Communication_Init_Ack
    PID_VA_Response
      element PID_VA_ResponseBase: array-size=64, array-size-semantics=FIXED-SIZE, implementation-data-type=uint8
      symbol props SymbolProps: symbol=PID_VA_Response
    TCPServer_IP_TS_DTO_01_Data
      element TCPServer_IP_TS_DTO_01_DataBase: array-size=1440, array-size-semantics=FIXED-SIZE, implementation-data-type=uint8
      symbol props SymbolProps: symbol=TCPServer_IP_TS_DTO_01_Data
    TCPServer_IP_TS_DTO_02_Data
      element TCPServer_IP_TS_DTO_02_DataBase: array-size=1440, array-size-semantics=FIXED-SIZE, implementation-data-type=uint8
      symbol props SymbolProps: symbol=TCPServer_IP_TS_DTO_02_Data
    TCPServer_IP_TS_DTO_03_Data
      element TCPServer_IP_TS_DTO_03_DataBase: array-size=1440, array-size-semantics=FIXED-SIZE, implementation-data-type=uint8
      symbol props SymbolProps: symbol=TCPServer_IP_TS_DTO_03_Data
    TCPServer_IP_TS_DTO_04_Data
      element TCPServer_IP_TS_DTO_04_DataBase: array-size=1440, array-size-semantics=FIXED-SIZE, implementation-data-type=uint8
      symbol props SymbolProps: symbol=TCPServer_IP_TS_DTO_04_Data
    ZR_VA_Challenge_CID
      element ZR_VA_Challenge_CIDBase: array-size=64, array-size-semantics=FIXED-SIZE, implementation-data-type=uint8
      symbol props SymbolProps: symbol=ZR_VA_Challenge_CID
    ZR_VA_Challenge_FID
      element ZR_VA_Challenge_FIDBase: array-size=64, array-size-semantics=FIXED-SIZE, implementation-data-type=uint8
      symbol props SymbolProps: symbol=ZR_VA_Challenge_FID
    ZR_VA_Challenge_PID
      element ZR_VA_Challenge_PIDBase: array-size=64, array-size-semantics=FIXED-SIZE, implementation-data-type=uint8
      symbol props SymbolProps: symbol=ZR_VA_Challenge_PID
    ZR_VA_Communication_Init_Ack_CID
      element ZR_VA_Communication_Init_Ack_CIDBase: array-size=17, array-size-semantics=FIXED-SIZE, implementation-data-type=uint8
      symbol props SymbolProps: symbol=ZR_VA_Communication_Init_Ack_CID
    ZR_VA_Communication_Init_Ack_FID
      element ZR_VA_Communication_Init_Ack_FIDBase: array-size=17, array-size-semantics=FIXED-SIZE, implementation-data-type=uint8
      symbol props SymbolProps: symbol=ZR_VA_Communication_Init_Ack_FID
    ZR_VA_Communication_Init_Ack_PID
      element ZR_VA_Communication_Init_Ack_PIDBase: array-size=17, array-size-semantics=FIXED-SIZE, implementation-data-type=uint8
      symbol props SymbolProps: symbol=ZR_VA_Communication_Init_Ack_PID
    ZR_VA_Communication_Init_CID
      element ZR_VA_Communication_Init_CIDBase: array-size=17, array-size-semantics=FIXED-SIZE, implementation-data-type=uint8
      symbol props SymbolProps: symbol=ZR_VA_Communication_Init_CID
    ZR_VA_Communication_Init_FID
      element ZR_VA_Communication_Init_FIDBase: array-size=17, array-size-semantics=FIXED-SIZE, implementation-data-type=uint8
      symbol props SymbolProps: symbol=ZR_VA_Communication_Init_FID
    ZR_VA_Communication_Init_PID
      element ZR_VA_Communication_Init_PIDBase: array-size=17, array-size-semantics=FIXED-SIZE, implementation-data-type=uint8
      symbol props SymbolProps: symbol=ZR_VA_Communication_Init_PID
package /ComponentTypes
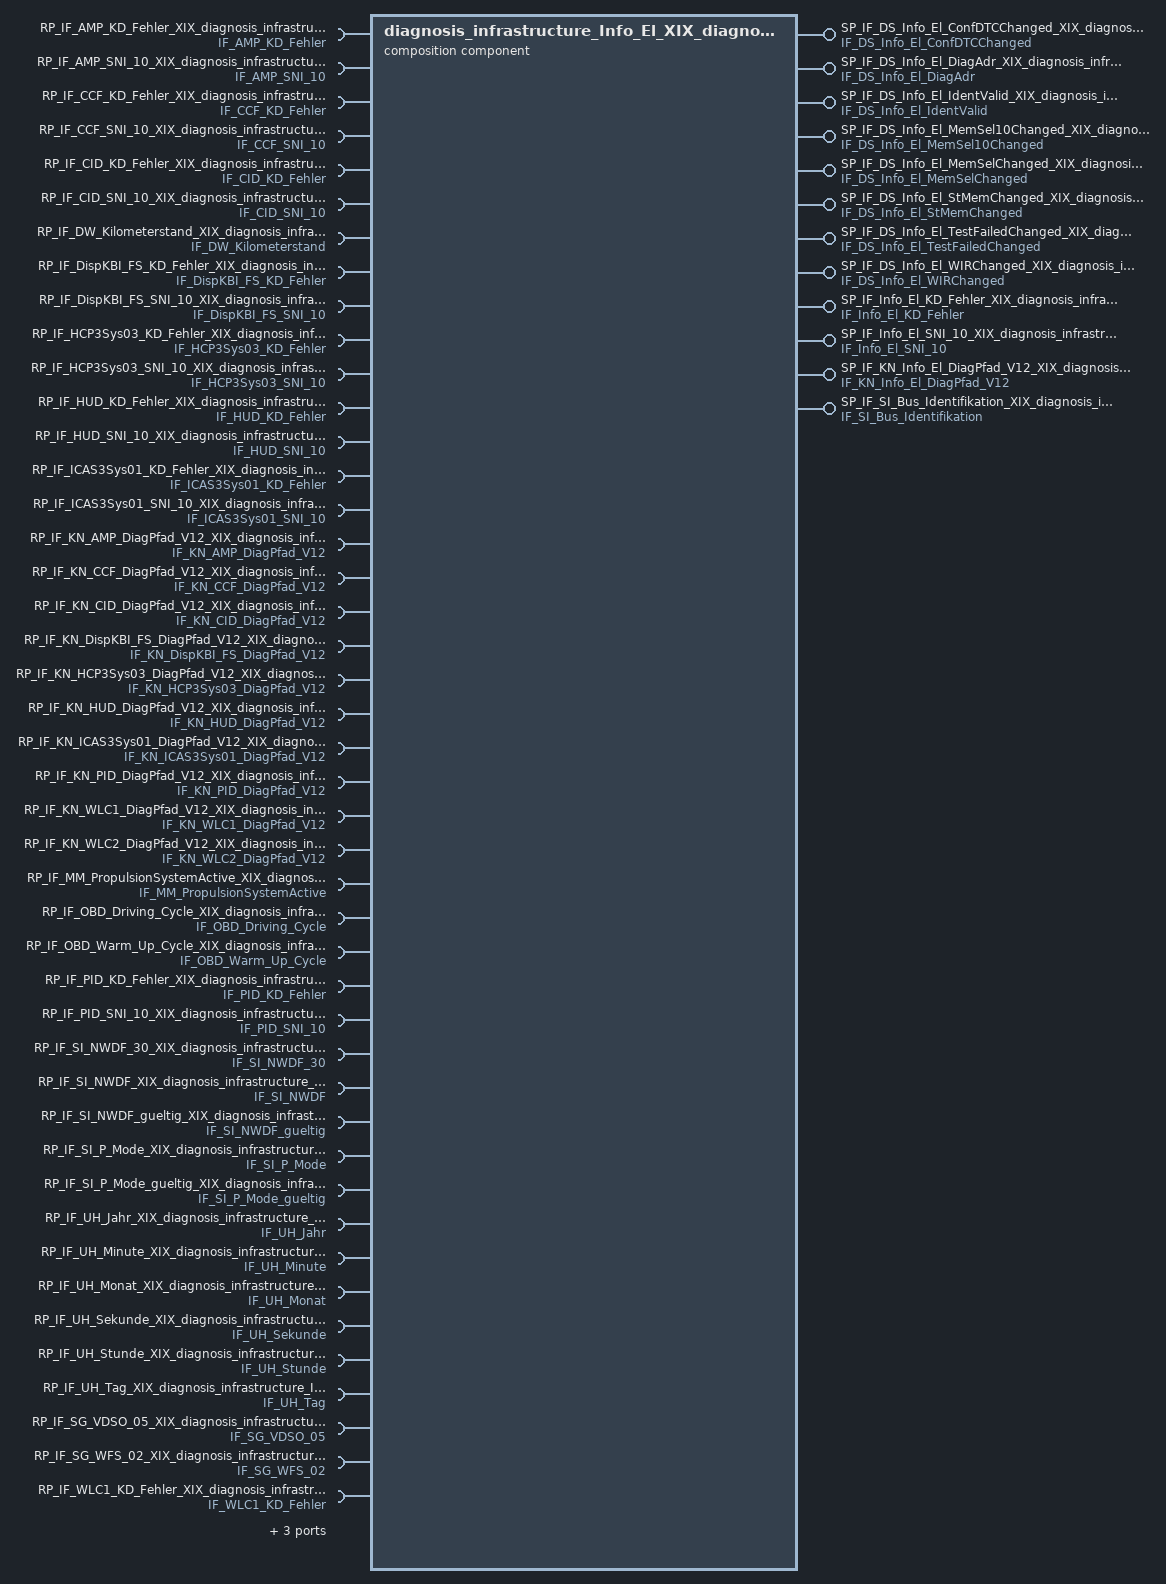
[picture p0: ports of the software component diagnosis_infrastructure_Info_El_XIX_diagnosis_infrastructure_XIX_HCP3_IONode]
  composition sw component type diagnosis_infrastructure_Info_El_XIX_diagnosis_infrastructure_XIX_HCP3_IONode
    12 x provide port:
      SP_IF_DS_Info_El_ConfDTCChanged_XIX_diagnosis_infrastructure_Info_El_XIX_diagnosis_infrastructure_XIX_HCP3_IONode: provided-interface=IF_DS_Info_El_ConfDTCChanged
      SP_IF_DS_Info_El_DiagAdr_XIX_diagnosis_infrastructure_Info_El_XIX_diagnosis_infrastructure_XIX_HCP3_IONode: provided-interface=IF_DS_Info_El_DiagAdr
      SP_IF_DS_Info_El_IdentValid_XIX_diagnosis_infrastructure_Info_El_XIX_diagnosis_infrastructure_XIX_HCP3_IONode: provided-interface=IF_DS_Info_El_IdentValid
      SP_IF_DS_Info_El_MemSel10Changed_XIX_diagnosis_infrastructure_Info_El_XIX_diagnosis_infrastructure_XIX_HCP3_IONode: provided-interface=IF_DS_Info_El_MemSel10Changed
      SP_IF_DS_Info_El_MemSelChanged_XIX_diagnosis_infrastructure_Info_El_XIX_diagnosis_infrastructure_XIX_HCP3_IONode: provided-interface=IF_DS_Info_El_MemSelChanged
      SP_IF_DS_Info_El_StMemChanged_XIX_diagnosis_infrastructure_Info_El_XIX_diagnosis_infrastructure_XIX_HCP3_IONode: provided-interface=IF_DS_Info_El_StMemChanged
      SP_IF_DS_Info_El_TestFailedChanged_XIX_diagnosis_infrastructure_Info_El_XIX_diagnosis_infrastructure_XIX_HCP3_IONode: provided-interface=IF_DS_Info_El_TestFailedChanged
      SP_IF_DS_Info_El_WIRChanged_XIX_diagnosis_infrastructure_Info_El_XIX_diagnosis_infrastructure_XIX_HCP3_IONode: provided-interface=IF_DS_Info_El_WIRChanged
      SP_IF_Info_El_KD_Fehler_XIX_diagnosis_infrastructure_Info_El_XIX_diagnosis_infrastructure_XIX_HCP3_IONode: provided-interface=IF_Info_El_KD_Fehler
      SP_IF_Info_El_SNI_10_XIX_diagnosis_infrastructure_Info_El_XIX_diagnosis_infrastructure_XIX_HCP3_IONode: provided-interface=IF_Info_El_SNI_10
      SP_IF_KN_Info_El_DiagPfad_V12_XIX_diagnosis_infrastructure_Info_El_XIX_diagnosis_infrastructure_XIX_HCP3_IONode: provided-interface=IF_KN_Info_El_DiagPfad_V12
      SP_IF_SI_Bus_Identifikation_XIX_diagnosis_infrastructure_Info_El_XIX_diagnosis_infrastructure_XIX_HCP3_IONode: provided-interface=IF_SI_Bus_Identifikation
    47 x require port:
      RP_IF_AMP_KD_Fehler_XIX_diagnosis_infrastructure_Info_El_XIX_diagnosis_infrastructure_XIX_HCP3_IONode: required-interface=IF_AMP_KD_Fehler
      RP_IF_AMP_SNI_10_XIX_diagnosis_infrastructure_Info_El_XIX_diagnosis_infrastructure_XIX_HCP3_IONode: required-interface=IF_AMP_SNI_10
      RP_IF_CCF_KD_Fehler_XIX_diagnosis_infrastructure_Info_El_XIX_diagnosis_infrastructure_XIX_HCP3_IONode: required-interface=IF_CCF_KD_Fehler
      RP_IF_CCF_SNI_10_XIX_diagnosis_infrastructure_Info_El_XIX_diagnosis_infrastructure_XIX_HCP3_IONode: required-interface=IF_CCF_SNI_10
      RP_IF_CID_KD_Fehler_XIX_diagnosis_infrastructure_Info_El_XIX_diagnosis_infrastructure_XIX_HCP3_IONode: required-interface=IF_CID_KD_Fehler
      RP_IF_CID_SNI_10_XIX_diagnosis_infrastructure_Info_El_XIX_diagnosis_infrastructure_XIX_HCP3_IONode: required-interface=IF_CID_SNI_10
      RP_IF_DW_Kilometerstand_XIX_diagnosis_infrastructure_Info_El_XIX_diagnosis_infrastructure_XIX_HCP3_IONode: required-interface=IF_DW_Kilometerstand
      RP_IF_DispKBI_FS_KD_Fehler_XIX_diagnosis_infrastructure_Info_El_XIX_diagnosis_infrastructure_XIX_HCP3_IONode: required-interface=IF_DispKBI_FS_KD_Fehler
      RP_IF_DispKBI_FS_SNI_10_XIX_diagnosis_infrastructure_Info_El_XIX_diagnosis_infrastructure_XIX_HCP3_IONode: required-interface=IF_DispKBI_FS_SNI_10
      RP_IF_HCP3Sys03_KD_Fehler_XIX_diagnosis_infrastructure_Info_El_XIX_diagnosis_infrastructure_XIX_HCP3_IONode: required-interface=IF_HCP3Sys03_KD_Fehler
      RP_IF_HCP3Sys03_SNI_10_XIX_diagnosis_infrastructure_Info_El_XIX_diagnosis_infrastructure_XIX_HCP3_IONode: required-interface=IF_HCP3Sys03_SNI_10
      RP_IF_HUD_KD_Fehler_XIX_diagnosis_infrastructure_Info_El_XIX_diagnosis_infrastructure_XIX_HCP3_IONode: required-interface=IF_HUD_KD_Fehler
      RP_IF_HUD_SNI_10_XIX_diagnosis_infrastructure_Info_El_XIX_diagnosis_infrastructure_XIX_HCP3_IONode: required-interface=IF_HUD_SNI_10
      RP_IF_ICAS3Sys01_KD_Fehler_XIX_diagnosis_infrastructure_Info_El_XIX_diagnosis_infrastructure_XIX_HCP3_IONode: required-interface=IF_ICAS3Sys01_KD_Fehler
      RP_IF_ICAS3Sys01_SNI_10_XIX_diagnosis_infrastructure_Info_El_XIX_diagnosis_infrastructure_XIX_HCP3_IONode: required-interface=IF_ICAS3Sys01_SNI_10
      RP_IF_KN_AMP_DiagPfad_V12_XIX_diagnosis_infrastructure_Info_El_XIX_diagnosis_infrastructure_XIX_HCP3_IONode: required-interface=IF_KN_AMP_DiagPfad_V12
      RP_IF_KN_CCF_DiagPfad_V12_XIX_diagnosis_infrastructure_Info_El_XIX_diagnosis_infrastructure_XIX_HCP3_IONode: required-interface=IF_KN_CCF_DiagPfad_V12
      RP_IF_KN_CID_DiagPfad_V12_XIX_diagnosis_infrastructure_Info_El_XIX_diagnosis_infrastructure_XIX_HCP3_IONode: required-interface=IF_KN_CID_DiagPfad_V12
      RP_IF_KN_DispKBI_FS_DiagPfad_V12_XIX_diagnosis_infrastructure_Info_El_XIX_diagnosis_infrastructure_XIX_HCP3_IONode: required-interface=IF_KN_DispKBI_FS_DiagPfad_V12
      RP_IF_KN_HCP3Sys03_DiagPfad_V12_XIX_diagnosis_infrastructure_Info_El_XIX_diagnosis_infrastructure_XIX_HCP3_IONode: required-interface=IF_KN_HCP3Sys03_DiagPfad_V12
      RP_IF_KN_HUD_DiagPfad_V12_XIX_diagnosis_infrastructure_Info_El_XIX_diagnosis_infrastructure_XIX_HCP3_IONode: required-interface=IF_KN_HUD_DiagPfad_V12
      RP_IF_KN_ICAS3Sys01_DiagPfad_V12_XIX_diagnosis_infrastructure_Info_El_XIX_diagnosis_infrastructure_XIX_HCP3_IONode: required-interface=IF_KN_ICAS3Sys01_DiagPfad_V12
      RP_IF_KN_PID_DiagPfad_V12_XIX_diagnosis_infrastructure_Info_El_XIX_diagnosis_infrastructure_XIX_HCP3_IONode: required-interface=IF_KN_PID_DiagPfad_V12
      RP_IF_KN_WLC1_DiagPfad_V12_XIX_diagnosis_infrastructure_Info_El_XIX_diagnosis_infrastructure_XIX_HCP3_IONode: required-interface=IF_KN_WLC1_DiagPfad_V12
      RP_IF_KN_WLC2_DiagPfad_V12_XIX_diagnosis_infrastructure_Info_El_XIX_diagnosis_infrastructure_XIX_HCP3_IONode: required-interface=IF_KN_WLC2_DiagPfad_V12
      RP_IF_MM_PropulsionSystemActive_XIX_diagnosis_infrastructure_Info_El_XIX_diagnosis_infrastructure_XIX_HCP3_IONode: required-interface=IF_MM_PropulsionSystemActive
      RP_IF_OBD_Driving_Cycle_XIX_diagnosis_infrastructure_Info_El_XIX_diagnosis_infrastructure_XIX_HCP3_IONode: required-interface=IF_OBD_Driving_Cycle
      RP_IF_OBD_Warm_Up_Cycle_XIX_diagnosis_infrastructure_Info_El_XIX_diagnosis_infrastructure_XIX_HCP3_IONode: required-interface=IF_OBD_Warm_Up_Cycle
      RP_IF_PID_KD_Fehler_XIX_diagnosis_infrastructure_Info_El_XIX_diagnosis_infrastructure_XIX_HCP3_IONode: required-interface=IF_PID_KD_Fehler
      RP_IF_PID_SNI_10_XIX_diagnosis_infrastructure_Info_El_XIX_diagnosis_infrastructure_XIX_HCP3_IONode: required-interface=IF_PID_SNI_10
      RP_IF_SI_NWDF_30_XIX_diagnosis_infrastructure_Info_El_XIX_diagnosis_infrastructure_XIX_HCP3_IONode: required-interface=IF_SI_NWDF_30
      RP_IF_SI_NWDF_XIX_diagnosis_infrastructure_Info_El_XIX_diagnosis_infrastructure_XIX_HCP3_IONode: required-interface=IF_SI_NWDF
      RP_IF_SI_NWDF_gueltig_XIX_diagnosis_infrastructure_Info_El_XIX_diagnosis_infrastructure_XIX_HCP3_IONode: required-interface=IF_SI_NWDF_gueltig
      RP_IF_SI_P_Mode_XIX_diagnosis_infrastructure_Info_El_XIX_diagnosis_infrastructure_XIX_HCP3_IONode: required-interface=IF_SI_P_Mode
      RP_IF_SI_P_Mode_gueltig_XIX_diagnosis_infrastructure_Info_El_XIX_diagnosis_infrastructure_XIX_HCP3_IONode: required-interface=IF_SI_P_Mode_gueltig
      RP_IF_UH_Jahr_XIX_diagnosis_infrastructure_Info_El_XIX_diagnosis_infrastructure_XIX_HCP3_IONode: required-interface=IF_UH_Jahr
      RP_IF_UH_Minute_XIX_diagnosis_infrastructure_Info_El_XIX_diagnosis_infrastructure_XIX_HCP3_IONode: required-interface=IF_UH_Minute
      RP_IF_UH_Monat_XIX_diagnosis_infrastructure_Info_El_XIX_diagnosis_infrastructure_XIX_HCP3_IONode: required-interface=IF_UH_Monat
      RP_IF_UH_Sekunde_XIX_diagnosis_infrastructure_Info_El_XIX_diagnosis_infrastructure_XIX_HCP3_IONode: required-interface=IF_UH_Sekunde
      RP_IF_UH_Stunde_XIX_diagnosis_infrastructure_Info_El_XIX_diagnosis_infrastructure_XIX_HCP3_IONode: required-interface=IF_UH_Stunde
      RP_IF_UH_Tag_XIX_diagnosis_infrastructure_Info_El_XIX_diagnosis_infrastructure_XIX_HCP3_IONode: required-interface=IF_UH_Tag
      RP_IF_SG_VDSO_05_XIX_diagnosis_infrastructure_Info_El_XIX_diagnosis_infrastructure_XIX_HCP3_IONode: required-interface=IF_SG_VDSO_05
      RP_IF_SG_WFS_02_XIX_diagnosis_infrastructure_Info_El_XIX_diagnosis_infrastructure_XIX_HCP3_IONode: required-interface=IF_SG_WFS_02
      RP_IF_WLC1_KD_Fehler_XIX_diagnosis_infrastructure_Info_El_XIX_diagnosis_infrastructure_XIX_HCP3_IONode: required-interface=IF_WLC1_KD_Fehler
      RP_IF_WLC1_SNI_10_XIX_diagnosis_infrastructure_Info_El_XIX_diagnosis_infrastructure_XIX_HCP3_IONode: required-interface=IF_WLC1_SNI_10
      RP_IF_WLC2_KD_Fehler_XIX_diagnosis_infrastructure_Info_El_XIX_diagnosis_infrastructure_XIX_HCP3_IONode: required-interface=IF_WLC2_KD_Fehler
      RP_IF_WLC2_SNI_10_XIX_diagnosis_infrastructure_Info_El_XIX_diagnosis_infrastructure_XIX_HCP3_IONode: required-interface=IF_WLC2_SNI_10
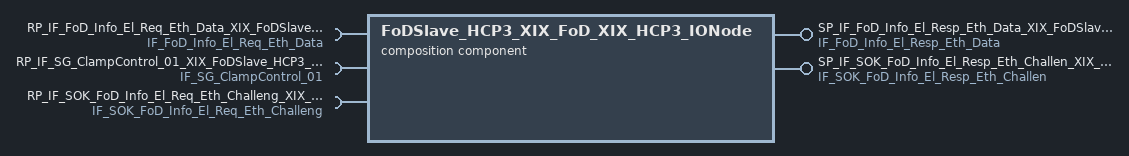
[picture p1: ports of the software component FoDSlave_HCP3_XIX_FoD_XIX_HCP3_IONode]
  composition sw component type FoDSlave_HCP3_XIX_FoD_XIX_HCP3_IONode
    provide port SP_IF_FoD_Info_El_Resp_Eth_Data_XIX_FoDSlave_HCP3_XIX_FoD_XIX_HCP3_IONode: provided-interface=IF_FoD_Info_El_Resp_Eth_Data
    provide port SP_IF_SOK_FoD_Info_El_Resp_Eth_Challen_XIX_FoDSlave_HCP3_XIX_FoD_XIX_HCP3_IONode: provided-interface=IF_SOK_FoD_Info_El_Resp_Eth_Challen
    require port RP_IF_FoD_Info_El_Req_Eth_Data_XIX_FoDSlave_HCP3_XIX_FoD_XIX_HCP3_IONode: required-interface=IF_FoD_Info_El_Req_Eth_Data
    require port RP_IF_SG_ClampControl_01_XIX_FoDSlave_HCP3_XIX_FoD_XIX_HCP3_IONode: required-interface=IF_SG_ClampControl_01
    require port RP_IF_SOK_FoD_Info_El_Req_Eth_Challeng_XIX_FoDSlave_HCP3_XIX_FoD_XIX_HCP3_IONode: required-interface=IF_SOK_FoD_Info_El_Req_Eth_Challeng
